[part 4 of 5: package /POWERTRAIN]
AUTOSAR XML (schema 3.2.2)
package /POWERTRAIN  (continued)
  can cluster POWERTRAIN:  (continued)
    physical channel POWERTRAIN  (continued)
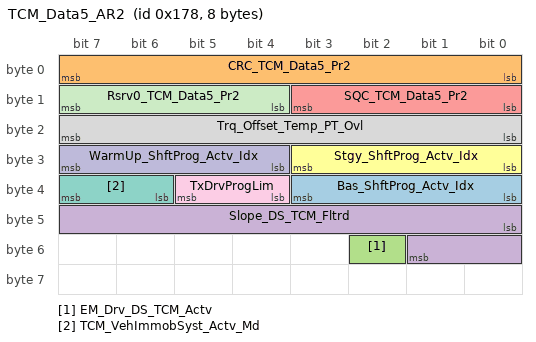
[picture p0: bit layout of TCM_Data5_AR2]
      frame TCM_Data5_AR2: id 0x178, from TCM, to CPC, frame-length=8, can-addressing-mode=STANDARD  # TCM Data5 AR2
        pdu TCM_Data5_AR2: length=64, unused-bit-pattern=0, cyclic-timing={repeating-time=0.1, starting-time=0.045}, event-controlled-timing=number-of-repeats=0, minimum-delay=0.01  # TCM Data5 AR2
          signal Bas_ShftProg_Actv_Idx: start 32, 4 bit, little-endian, data-type=c04_0_15_1_SNA_na, init-value=XDIS_2gdok7is6uk227cngmpgf9wxb/l0, transfer-property=TRIGGERED-ON-CHANGE, to CPC  # Index aktives Basisschaltprogramm / Index active base shift progrm
          signal CRC_TCM_Data5_Pr2: start 0, 8 bit, little-endian, data-type=c08_CRC_woSNA, init-value=l28, to CPC  # CRC-Checksumme der Signal Gruppe gemäß AUTOSAR Profil 2 / CRC-checksum of signal group according to AUTOSAR Profile 2
          signal EM_Drv_DS_TCM_Actv: start 50, 1 bit, little-endian, data-type=DC_BOOL, init-value=XDIS_h5tcyk98kzbgrc5svasomeyt/lfalse, transfer-property=TRIGGERED-ON-CHANGE, to CPC  # Aktivierung E-Fahrt Schaltprogramm der Fahrstrategie / activating E-Drive shift program of the driving strategie
          signal Slope_DS_TCM_Fltrd: start 40, 10 bit, little-endian, data-type=c10_perc_m30_70_0k1, init-value=XDIS_9q9tei3m1fjehhzmxi2ewe8ef/l1023, transfer-property=PENDING, to CPC  # Berechnete Steigung im TCM, gefiltert / Calculated TCM Slope, filtered
          signal SQC_TCM_Data5_Pr2: start 8, 4 bit, little-endian, data-type=c04_0_15_1_SNA_na, init-value=XDIS_2gdok7is6uk227cngmpgf9wxb/l0, to CPC  # Sequenzzähler / Sequence counter
          signal Stgy_ShftProg_Actv_Idx: start 24, 4 bit, little-endian, data-type=c04_0_15_1_SNA_na, init-value=XDIS_2gdok7is6uk227cngmpgf9wxb/l0, transfer-property=TRIGGERED-ON-CHANGE, to CPC  # Index aktives Strategie Schaltprogramm / Index active strategy shift progrm
          signal TCM_VehImmobSyst_Actv_Md: start 38, 2 bit, little-endian, data-type=c02_Rel_Lock_Free_SNA, init-value=XDIS_7xmnmysjdekva9q0y0lravx16/lREL, transfer-property=TRIGGERED-ON-CHANGE, to CPC  # FBS Freigabestatus TCM / TCM Vehicle immobilizing system active
          signal Trq_Offset_Temp_PT_Ovl: start 16, 8 bit, little-endian, data-type=c08_Nm_0_254_1, init-value=XDIS_atdfawq2fo29xmbv147hlg3xp/l255, to CPC  # Tq Offset für temporäre Überlastung PT / Torque Offset for temporary PT Overload
          signal TxDrvProgLim: start 36, 2 bit, little-endian, data-type=c02_TxDrvProgLim, init-value=lNO_RES_TCM, transfer-property=PENDING, to CPC  # Einschränkung Fahrprogramm TCM / TCM Limitation of Driving Program
          signal WarmUp_ShftProg_Actv_Idx: start 28, 4 bit, little-endian, data-type=c04_0_15_1_SNA_na, init-value=XDIS_2gdok7is6uk227cngmpgf9wxb/l0, transfer-property=TRIGGERED-ON-CHANGE, to CPC  # Index aktives Warmlaufschaltprogramm / Index active warmup shift progrm
          signal Rsrv0_TCM_Data5_Pr2: start 12, 4 bit, little-endian, data-type=Rsrv04, init-value=XDIS_eb9yua4lxmhrmvzyfsmxg3ler/l0, to CPC  # Reserviert für zukünftige Verwendung / Reserved for future use
          signal TCM_Data5_Pr2_c73komxr1qix41zrytxs0vhwu: little-endian, system-signal=[CRC_TCM_Data5_Pr2, Rsrv0_TCM_Data5_Pr2, SQC_TCM_Data5_Pr2, Trq_Offset_Temp_PT_Ovl], transfer-property=PENDING, to CPC  # TCM Data 5 (degraded) / TCM Date 5 (degraded)
      frame HVAC_Rs_AR2: id 0x1ED, from CPC, to ECM TCM, frame-length=8, can-addressing-mode=STANDARD  # Rückmeldung Klimaanlage / Heating, Ventilation and Air Conditioning response
        pdu HVAC_Rs_AR2: length=64, unused-bit-pattern=0, cyclic-timing=repeating-time=0.1  # Rückmeldung Klimaanlage / Heating, Ventilation and Air Conditioning response
          signal AddWtrPmp_Actv: start 36, 1 bit, little-endian, data-type=DC_BOOL, init-value=XDIS_h5tcyk98kzbgrc5svasomeyt/lfalse, transfer-property=PENDING, to ECM  # Zusatzwasserpumpe läuft / Additional water pump active
          signal AddWtrPmp_Err: start 37, 1 bit, little-endian, data-type=DC_BOOL, init-value=XDIS_h5tcyk98kzbgrc5svasomeyt/lfalse, transfer-property=PENDING, to ECM  # Fehler Zusatzwasserpumpe / Additional water pump error
          signal CRC_HVAC_CompTrq_Pr2: start 0, 8 bit, little-endian, data-type=c08_CRC_woSNA, init-value=l75, to ECM TCM  # CRC-Checksumme der Signal Gruppe gemäß AUTOSAR Profil 2 / CRC-checksum of signal group according to AUTOSAR Profile 2
          signal EngFanRPM_Rq_HVAC: start 56, 8 bit, little-endian, data-type=c08_perc_0_100_1, init-value=XDIS_526m332undv8qhobkm645cf10/l255, transfer-property=PENDING, to ECM  # Motorlüfter Solldrehzahl / Engine fan rpm request
          signal FrntGrllBlnd_Opn_Rq: start 29, 1 bit, little-endian, data-type=DC_BOOL, init-value=XDIS_h5tcyk98kzbgrc5svasomeyt/lfalse, transfer-property=PENDING, to ECM  # Jalousie Kühlergrill öffnen / Front grill blind open request
          signal HtPwr_Ft_Rq: start 48, 8 bit, little-endian, data-type=c08_perc_0_100_1, init-value=XDIS_526m332undv8qhobkm645cf10/l255, transfer-property=PENDING, to ECM  # Anforderung Heizleistung vorne / Heating power front request
          signal HVAC_Comp_Ft_On: start 28, 1 bit, little-endian, data-type=DC_BOOL, init-value=XDIS_h5tcyk98kzbgrc5svasomeyt/lfalse, transfer-property=PENDING, to ECM TCM  # Klima-Kompressor für vorne eingeschaltet / Aircon compressor front on
          signal HVAC_CompTrq_Ft: start 16, 8 bit, little-endian, data-type=c08_Nm_0_63k5_0k25, init-value=XDIS_3tke51neyh9tc3i280hit3n6t/l255, to ECM TCM  # Klima-Kompressormoment für vorne / Actual front aircon compressor crankshaft torque
          signal HVAC_CoolCirc_Actv: start 35, 1 bit, little-endian, data-type=DC_BOOL, init-value=XDIS_h5tcyk98kzbgrc5svasomeyt/lfalse, transfer-property=PENDING  # Kältekreislauf aktiv / HVAC cooling circuit active
          signal HVAC_CoolFan_Rq: start 31, 1 bit, little-endian, data-type=DC_BOOL, init-value=XDIS_h5tcyk98kzbgrc5svasomeyt/lfalse, transfer-property=PENDING  # Anforderung Klimaanlage: Kühlgebläse einschalten / Air condition cooling fan on request
          signal HVAC_CoolVlv_Rq: start 32, 2 bit, little-endian, data-type=c02_REM_CLS_OPN, init-value=XDIS_5kqf2dbype8wo99wu5c8aruyw/l3, transfer-property=PENDING  # Anforderung Kühlventil / Cool valve request
          signal HVAC_EngIdleRPM_Inc_Rq: start 27, 1 bit, little-endian, data-type=DC_BOOL, init-value=XDIS_h5tcyk98kzbgrc5svasomeyt/lfalse, transfer-property=PENDING, to ECM TCM  # Leerlauf-Drehzahlanhebung zur Kälteleistungserhöhung / Engine idle speed increase request
          signal HVAC_FrntGrllBlnd_Low_Rq: start 40, 4 bit, little-endian, data-type=c04_perc_0_100_10_SNA, init-value=XDIS_b7ef3mnghukxmc04ohxr08npp/l15, transfer-property=PENDING  # Anforderung untere Kühlergrill-Jalousie / Lower front grill blind request
          signal HVAC_FrntGrllBlnd_Up_Rq: start 44, 4 bit, little-endian, data-type=c04_perc_0_100_10_SNA, init-value=XDIS_b7ef3mnghukxmc04ohxr08npp/l15, transfer-property=PENDING  # Anforderung obere Kühlergrill-Jalousie / Upper front grill blind request
          signal HVAC_MaxCool_Rq: start 34, 1 bit, little-endian, data-type=DC_BOOL, init-value=XDIS_h5tcyk98kzbgrc5svasomeyt/lfalse, transfer-property=PENDING  # Maximale Kühlleistung für Klimakreislauf benötigt / Cooling circuit req. max. cooling performance
          signal HVAC_Ref_Circ_NA: start 30, 1 bit, little-endian, data-type=DC_BOOL, init-value=XDIS_h5tcyk98kzbgrc5svasomeyt/lfalse, transfer-property=PENDING  # HVAC Kühlkreislauf nicht verfügbar / HVAC cooling circuit not available
          signal HVAC_TxShftPoint_Inc_Rq: start 24, 1 bit, little-endian, data-type=DC_BOOL, init-value=XDIS_h5tcyk98kzbgrc5svasomeyt/lfalse, transfer-property=PENDING, to ECM TCM  # Anhebung des Getriebeschaltpunkts zur Klimakomfortsteigerung (kühlen) / Transmission shift point increase request for thermal comfort (cooling)
          signal HVAC_TxShftPointHt_Inc_Rq: start 25, 1 bit, little-endian, data-type=DC_BOOL, init-value=XDIS_h5tcyk98kzbgrc5svasomeyt/lfalse, transfer-property=PENDING, to ECM TCM  # Anhebung des Getriebeschaltpunkts zur Klimakomfortsteigerung (heizen) / Transmission shift point increase request for thermal comfort (heating)
          signal SQC_HVAC_CompTrq_Pr2: start 8, 4 bit, little-endian, data-type=c04_0_15_1_SNA_na, init-value=XDIS_2gdok7is6uk227cngmpgf9wxb/l0, to ECM TCM  # Sequenzzähler / Sequence counter
          signal SSA_Enbl_Rq_HVAC: start 26, 1 bit, little-endian, data-type=DC_BOOL, init-value=ltrue, transfer-property=PENDING, to ECM  # ASS enable / Enable stop/start automatic request
          signal Rsrv1_HVAC_Comp_Trq_Pr2: start 12, 4 bit, little-endian, data-type=Rsrv04, init-value=XDIS_eb9yua4lxmhrmvzyfsmxg3ler/l0, to ECM TCM  # Reserviert für zukünftige Verwendung / Reserved for future use
          signal HVAC_CompTrq_Pr2_c82iy4u15nkwuh8st1cqydegx: little-endian, system-signal=[CRC_HVAC_CompTrq_Pr2, HVAC_CompTrq_Ft, Rsrv1_HVAC_Comp_Trq_Pr2, SQC_HVAC_CompTrq_Pr2], transfer-property=PENDING, to ECM TCM  # KLimaanlage Kompressormoment (degraded) / HVAC compressor torque (degraded)
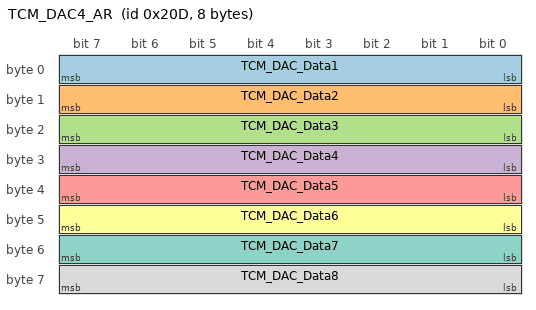
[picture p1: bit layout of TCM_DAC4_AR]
      frame TCM_DAC4_AR: id 0x20D, from TCM, to CPC, frame-length=8, can-addressing-mode=STANDARD  # FBS-Botschaft an EIS / Driving authorization checker
        pdu TCM_DAC4_AR: length=64, unused-bit-pattern=0, event-controlled-timing=number-of-repeats=0, minimum-delay=0.0050  # FBS-Botschaft an EIS / Driving authorization checker
          signal TCM_DAC_Data1: start 0, 8 bit, little-endian, data-type=c08_UInt_SNA_na, init-value=XDIS_2kt9ss9xytkqyzr4359iyexvi/l0, to CPC  # FBS-Botschaft an EIS Byte #1 / Driving authorization checker Byte #1
          signal TCM_DAC_Data2: start 8, 8 bit, little-endian, data-type=c08_UInt_SNA_na, init-value=XDIS_2kt9ss9xytkqyzr4359iyexvi/l0, to CPC  # FBS-Botschaft an EIS Byte #2 / Driving authorization checker Byte #2
          signal TCM_DAC_Data3: start 16, 8 bit, little-endian, data-type=c08_UInt_SNA_na, init-value=XDIS_2kt9ss9xytkqyzr4359iyexvi/l0, to CPC  # FBS-Botschaft an EIS Byte #3 / Driving authorization checker Byte #3
          signal TCM_DAC_Data4: start 24, 8 bit, little-endian, data-type=c08_UInt_SNA_na, init-value=XDIS_2kt9ss9xytkqyzr4359iyexvi/l0, to CPC  # FBS-Botschaft an EIS Byte #4 / Driving authorization checker Byte #4
          signal TCM_DAC_Data5: start 32, 8 bit, little-endian, data-type=c08_UInt_SNA_na, init-value=XDIS_2kt9ss9xytkqyzr4359iyexvi/l0, to CPC  # FBS-Botschaft an EIS Byte #5 / Driving authorization checker Byte #5
          signal TCM_DAC_Data6: start 40, 8 bit, little-endian, data-type=c08_UInt_SNA_na, init-value=XDIS_2kt9ss9xytkqyzr4359iyexvi/l0, to CPC  # FBS-Botschaft an EIS Byte #6 / Driving authorization checker Byte #6
          signal TCM_DAC_Data7: start 48, 8 bit, little-endian, data-type=c08_UInt_SNA_na, init-value=XDIS_2kt9ss9xytkqyzr4359iyexvi/l0, to CPC  # FBS-Botschaft an EIS Byte #7 / Driving authorization checker Byte #7
          signal TCM_DAC_Data8: start 56, 8 bit, little-endian, data-type=c08_UInt_SNA_na, init-value=XDIS_2kt9ss9xytkqyzr4359iyexvi/l0, to CPC  # FBS-Botschaft an EIS Byte #8 / Driving authorization checker Byte #8
          signal TCM_DAC_Data_4hn6jksl9jdh5r8zfj9p3zrj0: little-endian, system-signal=[TCM_DAC_Data1, TCM_DAC_Data2, TCM_DAC_Data3, TCM_DAC_Data4, TCM_DAC_Data5, TCM_DAC_Data6, TCM_DAC_Data7, TCM_DAC_Data8], transfer-property=TRIGGERED, to CPC  # FBS-Botschaft an EIS (degraded) / Driving authorization checker (degraded)
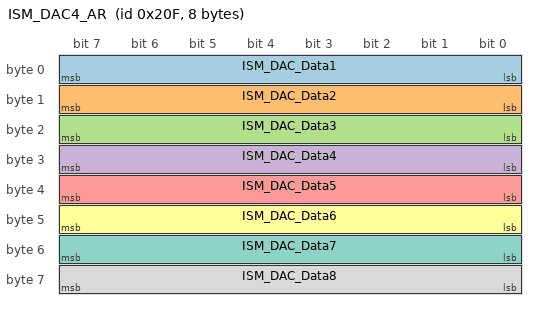
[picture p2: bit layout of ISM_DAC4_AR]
      frame ISM_DAC4_AR: id 0x20F, from ISM, to CPC, frame-length=8, can-addressing-mode=STANDARD  # FBS-Botschaft an EIS / Driving authorization checker
        pdu ISM_DAC4_AR: length=64, unused-bit-pattern=0, event-controlled-timing=number-of-repeats=0, minimum-delay=0.0050  # FBS-Botschaft an EIS / Driving authorization checker
          signal ISM_DAC_Data1: start 0, 8 bit, little-endian, data-type=c08_UInt_SNA_na, init-value=XDIS_2kt9ss9xytkqyzr4359iyexvi/l0, to CPC  # FBS-Botschaft an EIS Byte #1 / Driving authorization checker Byte #1
          signal ISM_DAC_Data2: start 8, 8 bit, little-endian, data-type=c08_UInt_SNA_na, init-value=XDIS_2kt9ss9xytkqyzr4359iyexvi/l0, to CPC  # FBS-Botschaft an EIS Byte #2 / Driving authorization checker Byte #2
          signal ISM_DAC_Data3: start 16, 8 bit, little-endian, data-type=c08_UInt_SNA_na, init-value=XDIS_2kt9ss9xytkqyzr4359iyexvi/l0, to CPC  # FBS-Botschaft an EIS Byte #3 / Driving authorization checker Byte #3
          signal ISM_DAC_Data4: start 24, 8 bit, little-endian, data-type=c08_UInt_SNA_na, init-value=XDIS_2kt9ss9xytkqyzr4359iyexvi/l0, to CPC  # FBS-Botschaft an EIS Byte #4 / Driving authorization checker Byte #4
          signal ISM_DAC_Data5: start 32, 8 bit, little-endian, data-type=c08_UInt_SNA_na, init-value=XDIS_2kt9ss9xytkqyzr4359iyexvi/l0, to CPC  # FBS-Botschaft an EIS Byte #5 / Driving authorization checker Byte #5
          signal ISM_DAC_Data6: start 40, 8 bit, little-endian, data-type=c08_UInt_SNA_na, init-value=XDIS_2kt9ss9xytkqyzr4359iyexvi/l0, to CPC  # FBS-Botschaft an EIS Byte #6 / Driving authorization checker Byte #6
          signal ISM_DAC_Data7: start 48, 8 bit, little-endian, data-type=c08_UInt_SNA_na, init-value=XDIS_2kt9ss9xytkqyzr4359iyexvi/l0, to CPC  # FBS-Botschaft an EIS Byte #7 / Driving authorization checker Byte #7
          signal ISM_DAC_Data8: start 56, 8 bit, little-endian, data-type=c08_UInt_SNA_na, init-value=XDIS_2kt9ss9xytkqyzr4359iyexvi/l0, to CPC  # FBS-Botschaft an EIS Byte #8 / Driving authorization checker Byte #8
          signal ISM_DAC_Data_7p6mfdvzdjn83yje572o4gwnl: little-endian, system-signal=[ISM_DAC_Data1, ISM_DAC_Data2, ISM_DAC_Data3, ISM_DAC_Data4, ISM_DAC_Data5, ISM_DAC_Data6, ISM_DAC_Data7, ISM_DAC_Data8], transfer-property=TRIGGERED, to CPC  # FBS-Botschaft an EIS (degraded) / Driving authorization checker (degraded)
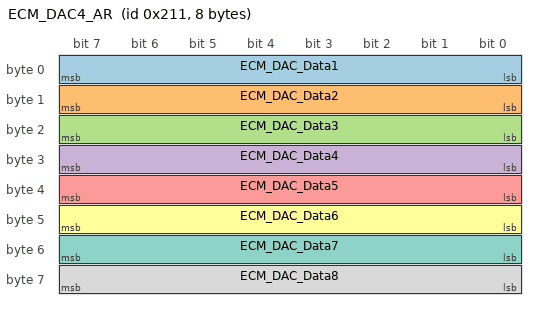
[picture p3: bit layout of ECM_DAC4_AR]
      frame ECM_DAC4_AR: id 0x211, from ECM, to CPC, frame-length=8, can-addressing-mode=STANDARD  # FBS-Botschaft an EIS / Driving authorization checker
        pdu ECM_DAC4_AR: length=64, unused-bit-pattern=0, event-controlled-timing=number-of-repeats=0, minimum-delay=0.0050  # FBS-Botschaft an EIS / Driving authorization checker
          signal ECM_DAC_Data1: start 0, 8 bit, little-endian, data-type=c08_UInt_SNA_na, init-value=XDIS_2kt9ss9xytkqyzr4359iyexvi/l0, to CPC  # FBS-Botschaft an EIS Byte #1 / Driving authorization checker Byte #1
          signal ECM_DAC_Data2: start 8, 8 bit, little-endian, data-type=c08_UInt_SNA_na, init-value=XDIS_2kt9ss9xytkqyzr4359iyexvi/l0, to CPC  # FBS-Botschaft an EIS Byte #2 / Driving authorization checker Byte #2
          signal ECM_DAC_Data3: start 16, 8 bit, little-endian, data-type=c08_UInt_SNA_na, init-value=XDIS_2kt9ss9xytkqyzr4359iyexvi/l0, to CPC  # FBS-Botschaft an EIS Byte #3 / Driving authorization checker Byte #3
          signal ECM_DAC_Data4: start 24, 8 bit, little-endian, data-type=c08_UInt_SNA_na, init-value=XDIS_2kt9ss9xytkqyzr4359iyexvi/l0, to CPC  # FBS-Botschaft an EIS Byte #4 / Driving authorization checker Byte #4
          signal ECM_DAC_Data5: start 32, 8 bit, little-endian, data-type=c08_UInt_SNA_na, init-value=XDIS_2kt9ss9xytkqyzr4359iyexvi/l0, to CPC  # FBS-Botschaft an EIS Byte #5 / Driving authorization checker Byte #5
          signal ECM_DAC_Data6: start 40, 8 bit, little-endian, data-type=c08_UInt_SNA_na, init-value=XDIS_2kt9ss9xytkqyzr4359iyexvi/l0, to CPC  # FBS-Botschaft an EIS Byte #6 / Driving authorization checker Byte #6
          signal ECM_DAC_Data7: start 48, 8 bit, little-endian, data-type=c08_UInt_SNA_na, init-value=XDIS_2kt9ss9xytkqyzr4359iyexvi/l0, to CPC  # FBS-Botschaft an EIS Byte #7 / Driving authorization checker Byte #7
          signal ECM_DAC_Data8: start 56, 8 bit, little-endian, data-type=c08_UInt_SNA_na, init-value=XDIS_2kt9ss9xytkqyzr4359iyexvi/l0, to CPC  # FBS-Botschaft an EIS Byte #8 / Driving authorization checker Byte #8
          signal ECM_DAC_Data_evokyfu54wz1o08tpk616zohb: little-endian, system-signal=[ECM_DAC_Data1, ECM_DAC_Data2, ECM_DAC_Data3, ECM_DAC_Data4, ECM_DAC_Data5, ECM_DAC_Data6, ECM_DAC_Data7, ECM_DAC_Data8], transfer-property=TRIGGERED, to CPC  # FBS-Botschaft an EIS (degraded) / Driving authorization checker (degraded)
      frame DAC4_ECM_AR: id 0x213, from CPC, to ECM, frame-length=8, can-addressing-mode=STANDARD  # FBS-Botschaft an ECM / Driving authorization checker
        pdu DAC4_ECM_AR: length=64, unused-bit-pattern=0, event-controlled-timing=number-of-repeats=0, minimum-delay=0.0050  # FBS-Botschaft an ECM / Driving authorization checker
          signal DAC_ECM_Data1: start 0, 8 bit, little-endian, data-type=c08_UInt_SNA_na, init-value=XDIS_2kt9ss9xytkqyzr4359iyexvi/l0, to ECM  # FBS-Botschaft an ECM Byte #1 / Driving authorization checker Byte #1
          signal DAC_ECM_Data2: start 8, 8 bit, little-endian, data-type=c08_UInt_SNA_na, init-value=XDIS_2kt9ss9xytkqyzr4359iyexvi/l0, to ECM  # FBS-Botschaft an ECM Byte #2 / Driving authorization checker Byte #2
          signal DAC_ECM_Data3: start 16, 8 bit, little-endian, data-type=c08_UInt_SNA_na, init-value=XDIS_2kt9ss9xytkqyzr4359iyexvi/l0, to ECM  # FBS-Botschaft an ECM Byte #3 / Driving authorization checker Byte #3
          signal DAC_ECM_Data4: start 24, 8 bit, little-endian, data-type=c08_UInt_SNA_na, init-value=XDIS_2kt9ss9xytkqyzr4359iyexvi/l0, to ECM  # FBS-Botschaft an ECM Byte #4 / Driving authorization checker Byte #4
          signal DAC_ECM_Data5: start 32, 8 bit, little-endian, data-type=c08_UInt_SNA_na, init-value=XDIS_2kt9ss9xytkqyzr4359iyexvi/l0, to ECM  # FBS-Botschaft an ECM Byte #5 / Driving authorization checker Byte #5
          signal DAC_ECM_Data6: start 40, 8 bit, little-endian, data-type=c08_UInt_SNA_na, init-value=XDIS_2kt9ss9xytkqyzr4359iyexvi/l0, to ECM  # FBS-Botschaft an ECM Byte #6 / Driving authorization checker Byte #6
          signal DAC_ECM_Data7: start 48, 8 bit, little-endian, data-type=c08_UInt_SNA_na, init-value=XDIS_2kt9ss9xytkqyzr4359iyexvi/l0, to ECM  # FBS-Botschaft an ECM Byte #7 / Driving authorization checker Byte #7
          signal DAC_ECM_Data8: start 56, 8 bit, little-endian, data-type=c08_UInt_SNA_na, init-value=XDIS_2kt9ss9xytkqyzr4359iyexvi/l0, to ECM  # FBS-Botschaft an ECM Byte #8 / Driving authorization checker Byte #8
          signal DAC_ECM_Data_2al2wd1ekctisq83jz37brera: little-endian, system-signal=[DAC_ECM_Data1, DAC_ECM_Data2, DAC_ECM_Data3, DAC_ECM_Data4, DAC_ECM_Data5, DAC_ECM_Data6, DAC_ECM_Data7, DAC_ECM_Data8], transfer-property=TRIGGERED, to ECM  # FBS-Botschaft an ECM (degraded) / Driving authorization checker (degraded)
      frame DAC4_TCM_AR: id 0x215, from CPC, to TCM, frame-length=8, can-addressing-mode=STANDARD  # FBS-Botschaft an TCM / Driving authorization checker
        pdu DAC4_TCM_AR: length=64, unused-bit-pattern=0, event-controlled-timing=number-of-repeats=0, minimum-delay=0.0050  # FBS-Botschaft an TCM / Driving authorization checker
          signal DAC_TCM_Data1: start 0, 8 bit, little-endian, data-type=c08_UInt_SNA_na, init-value=XDIS_2kt9ss9xytkqyzr4359iyexvi/l0, to TCM  # FBS-Botschaft an TCM Byte#1 / Driving authorization checker Byte#1
          signal DAC_TCM_Data2: start 8, 8 bit, little-endian, data-type=c08_UInt_SNA_na, init-value=XDIS_2kt9ss9xytkqyzr4359iyexvi/l0, to TCM  # FBS-Botschaft an TCM Byte#2 / Driving authorization checker Byte#2
          signal DAC_TCM_Data3: start 16, 8 bit, little-endian, data-type=c08_UInt_SNA_na, init-value=XDIS_2kt9ss9xytkqyzr4359iyexvi/l0, to TCM  # FBS-Botschaft an TCM Byte#3 / Driving authorization checker Byte#3
          signal DAC_TCM_Data4: start 24, 8 bit, little-endian, data-type=c08_UInt_SNA_na, init-value=XDIS_2kt9ss9xytkqyzr4359iyexvi/l0, to TCM  # FBS-Botschaft an TCM Byte#4 / Driving authorization checker Byte#4
          signal DAC_TCM_Data5: start 32, 8 bit, little-endian, data-type=c08_UInt_SNA_na, init-value=XDIS_2kt9ss9xytkqyzr4359iyexvi/l0, to TCM  # FBS-Botschaft an TCM Byte#5 / Driving authorization checker Byte#5
          signal DAC_TCM_Data6: start 40, 8 bit, little-endian, data-type=c08_UInt_SNA_na, init-value=XDIS_2kt9ss9xytkqyzr4359iyexvi/l0, to TCM  # FBS-Botschaft an TCM Byte#6 / Driving authorization checker Byte#6
          signal DAC_TCM_Data7: start 48, 8 bit, little-endian, data-type=c08_UInt_SNA_na, init-value=XDIS_2kt9ss9xytkqyzr4359iyexvi/l0, to TCM  # FBS-Botschaft an TCM Byte#7 / Driving authorization checker Byte#7
          signal DAC_TCM_Data8: start 56, 8 bit, little-endian, data-type=c08_UInt_SNA_na, init-value=XDIS_2kt9ss9xytkqyzr4359iyexvi/l0, to TCM  # FBS-Botschaft an TCM Byte#8 / Driving authorization checker Byte#8
          signal DAC_TCM_Data_2bwrxx3jxcrr8ui2py52ml14h: little-endian, system-signal=[DAC_TCM_Data1, DAC_TCM_Data2, DAC_TCM_Data3, DAC_TCM_Data4, DAC_TCM_Data5, DAC_TCM_Data6, DAC_TCM_Data7, DAC_TCM_Data8], transfer-property=TRIGGERED, to TCM  # FBS-Botschaft an TCM (degraded) / Driving authorization checker (degraded)
      frame DAC4_ISM_AR: id 0x217, from CPC, to ISM, frame-length=8, can-addressing-mode=STANDARD  # FBS-Botschaft an ISM / Driving authorization checker
        pdu DAC4_ISM_AR: length=64, unused-bit-pattern=0, event-controlled-timing=number-of-repeats=0, minimum-delay=0.0050  # FBS-Botschaft an ISM / Driving authorization checker
          signal DAC_ISM_Data1: start 0, 8 bit, little-endian, data-type=c08_UInt_SNA_na, init-value=XDIS_2kt9ss9xytkqyzr4359iyexvi/l0, to ISM  # FBS-Botschaft an ISM Byte#1 / Driving authorization checker Byte#1
          signal DAC_ISM_Data2: start 8, 8 bit, little-endian, data-type=c08_UInt_SNA_na, init-value=XDIS_2kt9ss9xytkqyzr4359iyexvi/l0, to ISM  # FBS-Botschaft an ISM Byte#2 / Driving authorization checker Byte#2
          signal DAC_ISM_Data3: start 16, 8 bit, little-endian, data-type=c08_UInt_SNA_na, init-value=XDIS_2kt9ss9xytkqyzr4359iyexvi/l0, to ISM  # FBS-Botschaft an ISM Byte#3 / Driving authorization checker Byte#3
          signal DAC_ISM_Data4: start 24, 8 bit, little-endian, data-type=c08_UInt_SNA_na, init-value=XDIS_2kt9ss9xytkqyzr4359iyexvi/l0, to ISM  # FBS-Botschaft an ISM Byte#4 / Driving authorization checker Byte#4
          signal DAC_ISM_Data5: start 32, 8 bit, little-endian, data-type=c08_UInt_SNA_na, init-value=XDIS_2kt9ss9xytkqyzr4359iyexvi/l0, to ISM  # FBS-Botschaft an ISM Byte#5 / Driving authorization checker Byte#5
          signal DAC_ISM_Data6: start 40, 8 bit, little-endian, data-type=c08_UInt_SNA_na, init-value=XDIS_2kt9ss9xytkqyzr4359iyexvi/l0, to ISM  # FBS-Botschaft an ISM Byte#6 / Driving authorization checker Byte#6
          signal DAC_ISM_Data7: start 48, 8 bit, little-endian, data-type=c08_UInt_SNA_na, init-value=XDIS_2kt9ss9xytkqyzr4359iyexvi/l0, to ISM  # FBS-Botschaft an ISM Byte#7 / Driving authorization checker Byte#7
          signal DAC_ISM_Data8: start 56, 8 bit, little-endian, data-type=c08_UInt_SNA_na, init-value=XDIS_2kt9ss9xytkqyzr4359iyexvi/l0, to ISM  # FBS-Botschaft an ISM Byte#8 / Driving authorization checker Byte#8
          signal DAC_ISM_Data_a00gd8sscucoi8oddzqtfrwxy: little-endian, system-signal=[DAC_ISM_Data1, DAC_ISM_Data2, DAC_ISM_Data3, DAC_ISM_Data4, DAC_ISM_Data5, DAC_ISM_Data6, DAC_ISM_Data7, DAC_ISM_Data8], transfer-property=TRIGGERED, to ISM  # FBS-Botschaft an ISM (degraded) / Driving authorization checker (degraded)
      frame Fuel_Stat_AR2: id 0x21D, from FSCM, to ECM, frame-length=8, can-addressing-mode=STANDARD
        pdu Fuel_Stat_AR2: length=64, unused-bit-pattern=0, cyclic-timing={repeating-time=0.1, starting-time=0.045}  # Kraftstoff Status / Fuel Status
          signal ElectricFuelPmp_Curr: start 32, 8 bit, little-endian, data-type=c08_A_0_30d1_0d15, init-value=XDIS_i4e3ph6igxm4spvtvcd0aaxn/l0, transfer-property=PENDING, to ECM  # Stromstärke elektrische Kraftstoffpumpe / Electric Fuel Pump current
          signal ElectricFuelPmp_RPM: start 24, 8 bit, little-endian, data-type=c08_rpm_0_5080_20, init-value=XDIS_em3qjydapl05yf4dt066kijsc/l0, transfer-property=PENDING, to ECM  # U/min der elektrischen Kraftstoffpumpe / RPM of the electric fuel Pump
          signal ElectricFuelPmp_Stat: start 40, 4 bit, little-endian, data-type=c04_ElectricFuelPmp_Stat, init-value=XDIS_cn7ds5rce5o16qs43tbneudnt/lOFF, transfer-property=PENDING, to ECM  # Status elektrische Kraftstoffpumpe / State of electric fuel pump
          signal EthanolConcent: start 16, 8 bit, little-endian, data-type=c08_perc_0_100_0k5, init-value=XDIS_7gd3auxmk1537dxoewcnzblfs/l255, transfer-property=PENDING, to ECM  # Kraftstoffethanolgehalt / Fuel Ethanol concentration
          signal FuelPmpDtyCyc: start 0, 8 bit, little-endian, data-type=c08_perc_0_100_0k5, init-value=XDIS_7gd3auxmk1537dxoewcnzblfs/l255, transfer-property=PENDING, to ECM  # Aktuelles Tastverhältnis Kraftstoffpumpe / Actual fuel pump duty cycle
          signal FuelPress: start 8, 8 bit, little-endian, data-type=c08_bar_0_10_0k05, init-value=XDIS_7frps0id7o3a7jqx301qmd2zx/l255, transfer-property=PENDING, to ECM  # Aktueller Kraftstoffdruck / Actual fuel pressure
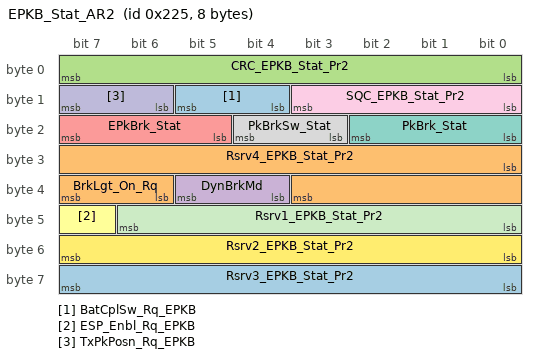
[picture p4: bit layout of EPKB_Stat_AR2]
      frame EPKB_Stat_AR2: id 0x225, from CPC, to ECM ISM TCM, frame-length=8, can-addressing-mode=STANDARD
        pdu EPKB_Stat_AR2: length=64, unused-bit-pattern=0, cyclic-timing=repeating-time=0.1, event-controlled-timing=number-of-repeats=0, minimum-delay=0.0050  # Status elektrische Parkbremse / Electrical parking brake state
          signal BatCplSw_Rq_EPKB: start 12, 2 bit, little-endian, data-type=c02_BatCplSw_Rq, init-value=XDIS_dl69ynb9ox7e9q5squkescmw4/lIDLE, transfer-property=TRIGGERED-ON-CHANGE, to ECM ISM TCM  # Anforderung Batteriekoppelschalter / Battery coupling switch request
          signal BrkLgt_On_Rq: start 38, 2 bit, little-endian, data-type=c02_Off_On, init-value=XDIS_222cmje3au9eeyrzykrya1i1q/lOFF, transfer-property=TRIGGERED-ON-CHANGE, to ECM ISM TCM  # Bremslicht einschalten / Brake light on request
          signal CRC_EPKB_Stat_Pr2: start 0, 8 bit, little-endian, data-type=c08_CRC_woSNA, init-value=l120, transfer-property=PENDING, to ECM ISM TCM  # CRC-Checksumme der Signal Gruppe gemäß AUTOSAR Profil 2 / CRC-checksum of signal group according to AUTOSAR Profile 2
          signal DynBrkMd: start 36, 2 bit, little-endian, data-type=c02_DynBrkMd, init-value=XDIS_34pxfrh12b3pknp94x9up6ty8/l3, transfer-property=TRIGGERED-ON-CHANGE, to ECM ISM TCM  # Modus dynamisches Bremsen / Dynamic braking mode
          signal EPkBrk_Stat: start 21, 3 bit, little-endian, data-type=c03_EPkBrk_Stat, init-value=XDIS_a5y42lspsaonemgf5sbikbeo/l7, transfer-property=TRIGGERED-ON-CHANGE, to ECM ISM TCM  # Status EPKB / Electrical parking brake system state
          signal ESP_Enbl_Rq_EPKB: start 47, 1 bit, little-endian, data-type=DC_BOOL, init-value=XDIS_h5tcyk98kzbgrc5svasomeyt/lfalse, transfer-property=TRIGGERED-ON-CHANGE, to ECM ISM TCM  # ESP-Anforderung erlaubt / Enable ESP request
          signal PkBrk_Stat: start 16, 3 bit, little-endian, data-type=c03_PkBrk_Stat, init-value=XDIS_792fn6nanbwsc1tnzw8o9lx5c/l7, transfer-property=TRIGGERED-ON-CHANGE, to ECM ISM TCM  # Status Feststellbremse / Parking brake state
          signal PkBrkSw_Stat: start 19, 2 bit, little-endian, data-type=c02_PkBrk_Sw_Stat, init-value=XDIS_256fs0r9jnfeiadezxr0n6q99/l3, transfer-property=TRIGGERED-ON-CHANGE, to ECM ISM TCM  # Feststellbremsenschalterzustand / Parking brake switch state
          signal SQC_EPKB_Stat_Pr2: start 8, 4 bit, little-endian, data-type=c04_0_15_1_SNA_na, init-value=XDIS_2gdok7is6uk227cngmpgf9wxb/l0, transfer-property=PENDING, to ECM ISM TCM  # Sequenzzähler / Sequence counter
          signal TxPkPosn_Rq_EPKB: start 14, 2 bit, little-endian, data-type=c02_TxPkPos_Rq, init-value=XDIS_2db0f8ngs6vghwr5wq6rrafpy/lIDLE, transfer-property=TRIGGERED-ON-CHANGE, to ECM ISM TCM  # EPKB-Wunsch: "P" einlegen / Transmission parking position request
          signal Rsrv1_EPKB_Stat_Pr2: start 40, 7 bit, little-endian, data-type=Rsrv07, init-value=XDIS_1uvqkcvexva3vp6bv7zoxjawg/l0, transfer-property=PENDING, to ECM ISM TCM  # Reserviert für zukünftige Verwendung / Reserved for future use
          signal Rsrv2_EPKB_Stat_Pr2: start 48, 8 bit, little-endian, data-type=Rsrv08, init-value=XDIS_4flxbk4wkjkdew7cw07d9of66/l0, transfer-property=PENDING, to ECM ISM TCM  # Reserviert für zukünftige Verwendung / Reserved for future use
          signal Rsrv3_EPKB_Stat_Pr2: start 56, 8 bit, little-endian, data-type=Rsrv08, init-value=XDIS_4flxbk4wkjkdew7cw07d9of66/l0, transfer-property=PENDING, to ECM ISM TCM  # Reserviert für zukünftige Verwendung / Reserved for future use
          signal Rsrv4_EPKB_Stat_Pr2: start 24, 12 bit, little-endian, data-type=Rsrv12, init-value=XDIS_94njywbs6xys4vfs8fqiw3tks/l0, transfer-property=PENDING, to ECM ISM TCM  # Reserviert für zukünftige Verwendung / Reserved for future use
          signal EPKB_Stat_Pr2_9vocfbztwmx64yya8hopavqwq: little-endian, system-signal=[BatCplSw_Rq_EPKB, BrkLgt_On_Rq, CRC_EPKB_Stat_Pr2, DynBrkMd, EPkBrk_Stat, ESP_Enbl_Rq_EPKB, PkBrk_Stat, PkBrkSw_Stat, Rsrv1_EPKB_Stat_Pr2, Rsrv2_EPKB_Stat_Pr2, Rsrv3_EPKB_Stat_Pr2, Rsrv4_EPKB_Stat_Pr2, SQC_EPKB_Stat_Pr2, TxPkPosn_Rq_EPKB], to ECM ISM TCM  # Status elektrische Parkbremse (degraded) / Electrical parking brake state (degraded)
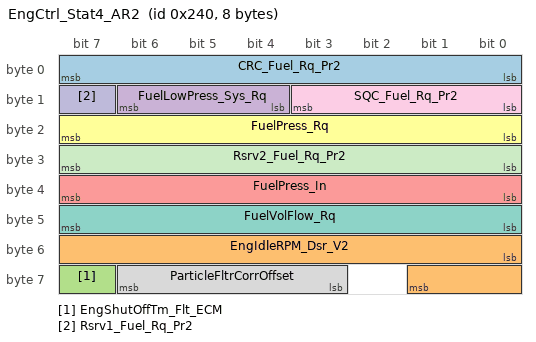
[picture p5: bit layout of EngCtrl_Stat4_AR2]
      frame EngCtrl_Stat4_AR2: id 0x240, from ECM, to CPC FSCM TCM, frame-length=8, can-addressing-mode=STANDARD
        pdu EngCtrl_Stat4_AR2: length=64, unused-bit-pattern=0, cyclic-timing={repeating-time=0.1, starting-time=0.0050}, event-controlled-timing=number-of-repeats=0, minimum-delay=0.01
          signal CRC_Fuel_Rq_Pr2: start 0, 8 bit, little-endian, data-type=c08_CRC_woSNA, init-value=l171, transfer-property=PENDING, to FSCM  # CRC-Checksumme der Signal Gruppe gemäß AUTOSAR Profil 2 / CRC-checksum of signal group according to AUTOSAR Profile 2
          signal EngIdleRPM_Dsr_V2: start 48, 10 bit, little-endian, data-type=c10_rpm_0_5000_5, init-value=XDIS_4l8q09vxqhutv9go97s4i82pi/l0, transfer-property=PENDING, to CPC TCM  # TCM Motorleerlaufsolldrehzahl / Desired engine idle speed to TCM
          signal EngShutOffTm_Flt_ECM: start 63, 1 bit, little-endian, data-type=DC_BOOL, init-value=XDIS_h5tcyk98kzbgrc5svasomeyt/lfalse, transfer-property=PENDING, to CPC FSCM  # Motorabstellzeit fehler von ECm festgestellt / Engine shut-off time fault from ECM
          signal FuelLowPress_Sys_Rq: start 12, 3 bit, little-endian, data-type=c03_FuelLowPress_Sys_Rq, init-value=XDIS_75kgv6x5wmeuyxn4jb0wfq7lq/l7, transfer-property=TRIGGERED-ON-CHANGE, to FSCM  # Anforderung an Kraftstoffniederdruckbereitstellung / Fuel Low pressure request
          signal FuelPress_In: start 32, 8 bit, little-endian, data-type=c08_hPa_0_12700_50, init-value=XDIS_bcvzfb8xc82lopd6nomhoa8hz/l0, transfer-property=PENDING, to FSCM  # Kraftstoffdruck für Mengensteuerung vor Hochdruckpumpe / Fuel pressure for quantity control before high pressure pump
          signal FuelPress_Rq: start 16, 8 bit, little-endian, data-type=c08_bar_0_10_0k05, init-value=XDIS_7frps0id7o3a7jqx301qmd2zx/l255, transfer-property=PENDING, to FSCM  # Anforderung Kraftstoffdruck / Fuel pressure request
          signal FuelVolFlow_Rq: start 40, 8 bit, little-endian, data-type=c08_l_per_h_0_381_1d5, init-value=XDIS_7aptig5ed7lppf85ff76xckus/l0, transfer-property=PENDING, to FSCM  # Kraftstoffflussanforderung / Fuel volume flow request
          signal ParticleFltrCorrOffset: start 59, 4 bit, little-endian, data-type=c04_0_0k42_0k03, init-value=XDIS_62zcs6tgdsblatw2e20ozynnd/l0, transfer-property=PENDING, to TCM  # Partikelfilterkorrekturwert / Particle filter correction offset on EngTrqMaxCorrFctr
          signal SQC_Fuel_Rq_Pr2: start 8, 4 bit, little-endian, data-type=c04_0_15_1_SNA_na, init-value=XDIS_2gdok7is6uk227cngmpgf9wxb/l0, transfer-property=PENDING, to FSCM  # Sequenzzähler / Sequence counter
          signal Rsrv1_Fuel_Rq_Pr2: start 15, 1 bit, little-endian, data-type=Rsrv01, init-value=XDIS_e2uhxyvdu33zsyqfjnk549pp2/l0, transfer-property=PENDING, to CPC FSCM TCM  # Reserviert für zukünftige Verwendung / Reserved for future use
          signal Rsrv2_Fuel_Rq_Pr2: start 24, 8 bit, little-endian, data-type=Rsrv08, init-value=XDIS_4flxbk4wkjkdew7cw07d9of66/l0, transfer-property=PENDING, to CPC FSCM TCM  # Reserviert für zukünftige Verwendung / Reserved for future use
          signal Fuel_Rq_Pr2_eypyqep6qt2njcbx8m8j4hfby: little-endian, system-signal=[CRC_Fuel_Rq_Pr2, FuelLowPress_Sys_Rq, FuelPress_Rq, Rsrv1_Fuel_Rq_Pr2, Rsrv2_Fuel_Rq_Pr2, SQC_Fuel_Rq_Pr2], to FSCM  # Fuel Request (degraded)
      frame FSCM_DTC_OBD_AR2: id 0x27F, from FSCM, to ECM, frame-length=8, can-addressing-mode=STANDARD  # FSCM Diagnostic trouble code für OBD / FSCM Diagnostic trouble code for OBD
        pdu FSCM_DTC_OBD_AR2: length=64, unused-bit-pattern=0, cyclic-timing={repeating-time=0.1, starting-time=0.0}  # FSCM Diagnostic trouble code für OBD / FSCM Diagnostic trouble code for OBD
          signal FSCM_CALID_CVN_ErrNum: start 0, 6 bit, little-endian, data-type=c06_0_63_1_SNA_na, init-value=XDIS_efjwndmyv9jwvt4o20fd0h4jr/l0, transfer-property=PENDING, to ECM  # Fehlernummer oder Zähler für CALID/CVN-Übertragung / Error number or counter for CALID/CVN transmission
          signal FSCM_CALID_Data: start 8, 8 bit, little-endian, data-type=c08_0_255_1_SNA_na, init-value=XDIS_ewtdrsxwev3sdrb0l7wuuy5x2/l255, transfer-property=PENDING, to ECM  # CALID/CVN Datenbyte / CALID/CVN data byte
          signal FSCM_CVN_Tx_Actv: start 7, 1 bit, little-endian, data-type=DC_BOOL, init-value=XDIS_h5tcyk98kzbgrc5svasomeyt/lfalse, transfer-property=PENDING, to ECM  # CVN wird übertragen / CVN transmission is active
          signal FSCM_DTC1_Idx: start 16, 5 bit, little-endian, data-type=c05_0_31_1_SNA_na, init-value=XDIS_eyvjtlfat7mxs0ushx899rtu2/l0, transfer-property=PENDING, to ECM  # Diagnostic trouble code #1 index
          signal FSCM_DTC1_Stat: start 21, 3 bit, little-endian, data-type=c03_RBS_DTC_Stat, init-value=lNOT_SUPPORTED, transfer-property=PENDING, to ECM  # Diagnostic trouble code #1 state
      frame TCM_Disp_Rq_AMG_AR: id 0x28D, from TCM, to CPC DRVU, frame-length=8, can-addressing-mode=STANDARD  # TCM Display Anforderung (nur AMG) / TCM display request (only AMG)
        pdu TCM_Disp_Rq_AMG_AR: length=64, unused-bit-pattern=0, cyclic-timing={repeating-time=0.2, starting-time=0.12}, event-controlled-timing=number-of-repeats=0, minimum-delay=0.04  # TCM Display Anforderung (nur AMG) / TCM display request (only AMG)
          signal TCM_TxLED_Disp_Rq: start 0, 5 bit, little-endian, data-type=c05_TCM_TxLED, init-value=XDIS_6h6s0bv7efp11m4nlf9yg5z0a/lLED_OFF, to CPC DRVU(timeout 2.1 s)  # Getriebe LED-Anzeige Anforderung / Transmission LED display request
          signal TCM_TxShift_Disp_Rq: start 8, 4 bit, little-endian, data-type=c04_TCM_TxShift, init-value=XDIS_bmt0u1x06oaiquus1ilde29fw/lNO_RQ, to CPC DRVU(timeout 2.1 s)  # Transmission shift denial/proposal display request
          signal Tx_OptmzFullLoad_Rq: start 62, 2 bit, little-endian, data-type=c02_InActv_Actv, init-value=XDIS_erebtjnp6vmvpjp0dso95abr3/lINACTV, transfer-property=TRIGGERED-ON-CHANGE, to CPC  # Optimierte Volllast Anforderung von Getriebe / Optimzied full load request of transmission
          signal TxBurnOut_Stat: start 5, 2 bit, little-endian, data-type=c02_TxBurnOut_Stat, init-value=lINACTIVE, to CPC DRVU(timeout 2.1 s)  # Getriebe Burnout status (nur AMG) / Transmission burnout state (only AMG)
          signal TCM_Disp_Rq_AMG_a2nvzdcsqucauph6dn6priuij: little-endian, system-signal=[TCM_TxLED_Disp_Rq, TCM_TxShift_Disp_Rq, TxBurnOut_Stat], transfer-property=TRIGGERED-ON-CHANGE, to CPC DRVU(timeout 2.1 s)  # TCM Display Anforderung (nur AMG) (degraded) / TCM display request (only AMG) (degraded)
      frame TCM_Rq1_AR: id 0x2A5, from TCM, to SSP, frame-length=8, can-addressing-mode=STANDARD
        pdu TCM_Rq1_AR: length=64, unused-bit-pattern=0, cyclic-timing={repeating-time=0.02, starting-time=0.1}
          signal AuxOilPmp_Mess_Enbl: start 8, 1 bit, little-endian, data-type=DC_BOOL, init-value=XDIS_h5tcyk98kzbgrc5svasomeyt/lfalse, transfer-property=PENDING, to SSP  # Enable measurement ID of auxiliary oil pump
          signal CurrDtyCyc_Rq: start 0, 8 bit, little-endian, data-type=c08_perc_0_100_0k5, init-value=XDIS_7gd3auxmk1537dxoewcnzblfs/l255, transfer-property=PENDING, to SSP  # Soll-Strom (Tastverhältnis) / Requested current duty cycle
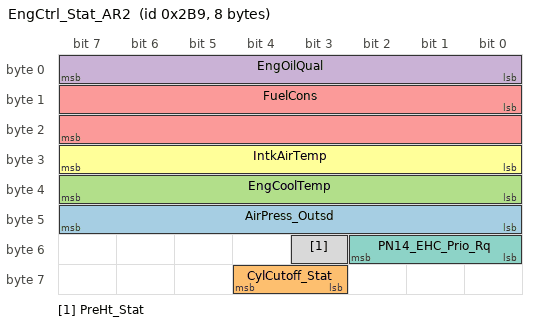
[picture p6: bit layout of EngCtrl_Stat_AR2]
      frame EngCtrl_Stat_AR2: id 0x2B9, from ECM, to ASX CPC FSCM TCM, frame-length=8, can-addressing-mode=STANDARD
        pdu EngCtrl_Stat_AR2: length=64, unused-bit-pattern=0, cyclic-timing={repeating-time=0.1, starting-time=0.065}, event-controlled-timing=number-of-repeats=0, minimum-delay=0.01
          signal AirPress_Outsd: start 40, 8 bit, little-endian, data-type=c08_hPa_0_1980_7k8, init-value=XDIS_2fhjzhyzrl6fjzklwzp7lg8jy/l255, transfer-property=PENDING, to CPC FSCM TCM  # Außenluftdruck / Outside air pressure
          signal CylCutoff_Stat: start 59, 2 bit, little-endian, data-type=c02_CylCutoff_Stat, init-value=lNO_ZAS, transfer-property=TRIGGERED-ON-CHANGE, to ASX CPC TCM  # Zylinderabschaltung Status / Cylinder cutoff state
          signal EngCoolTemp: start 32, 8 bit, little-endian, data-type=c08_degC_m40_214_1, init-value=XDIS_carqyv2gq7ncv789c849hnl6r/l255, transfer-property=PENDING, to CPC FSCM TCM  # Motorkühlmitteltemperatur / Engine coolant temperature
          signal EngOilQual: start 0, 8 bit, little-endian, data-type=c08_1_6_0k01969, init-value=XDIS_enuzrfb1f0b4exavz9gba8664/l255, transfer-property=PENDING, to CPC  # Motorölqualität / Engine oil quality
          signal FuelCons: start 8, 16 bit, little-endian, data-type=c16_ul_p_250ms_0_14200_0k21668, init-value=XDIS_a07pbof8nfjy6sopkumlg9k7r/l65535, transfer-property=PENDING, to CPC FSCM  # Verbrauch / Fuel consumption
          signal IntkAirTemp: start 24, 8 bit, little-endian, data-type=c08_degC_m40_214_1, init-value=XDIS_carqyv2gq7ncv789c849hnl6r/l255, transfer-property=PENDING, to CPC TCM  # Ansauglufttemperatur / Intake air temperature
          signal PN14_EHC_Prio_Rq: start 48, 3 bit, little-endian, data-type=c03_PN14_EHC_Prio_Rq, init-value=XDIS_2wcffyjyaskh0k7y4ufyneacn/lOFF, transfer-property=PENDING, to CPC  # Anforderung für EHC Priorität / Priority of EHC request
          signal PreHt_Stat: start 51, 1 bit, little-endian, data-type=DC_BOOL, init-value=XDIS_h5tcyk98kzbgrc5svasomeyt/lfalse, transfer-property=PENDING, to CPC  # Vorglühstatus / Preheating state
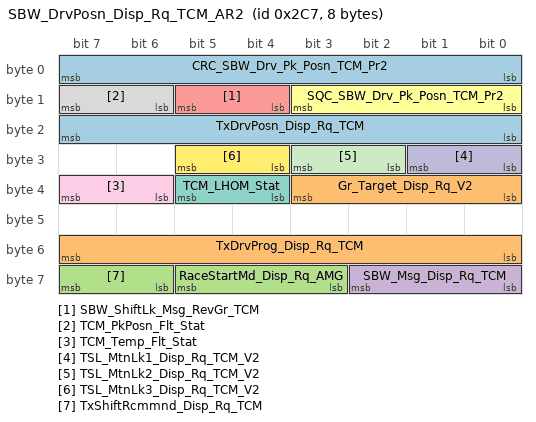
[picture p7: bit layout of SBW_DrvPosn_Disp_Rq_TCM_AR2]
      frame SBW_DrvPosn_Disp_Rq_TCM_AR2: id 0x2C7, from TCM, to CPC DRVU ECM, frame-length=8, can-addressing-mode=STANDARD  # Anzeige Shift by Wire und Fahrstufe / Shift by wire and driving position display request
        pdu SBW_DrvPosn_Disp_Rq_TCM_AR2: length=64, unused-bit-pattern=0, cyclic-timing={repeating-time=0.2, starting-time=0.17}, event-controlled-timing=number-of-repeats=0, minimum-delay=0.02  # Anzeige Shift by Wire und Fahrstufe / Shift by wire and driving position display request
          signal CRC_SBW_Drv_Pk_Posn_TCM_Pr2: start 0, 8 bit, little-endian, data-type=c08_CRC_woSNA, init-value=l205, transfer-property=PENDING, to CPC DRVU(timeout 2.1 s) ECM  # CRC-Checksumme der Signal Gruppe gemäß AUTOSAR Profil 2 / CRC-checksum of signal group according to AUTOSAR Profile 2
          signal Gr_Target_Disp_Rq_V2: start 32, 4 bit, little-endian, data-type=c04_Gr_Target_Disp_Rq_V2, init-value=XDIS_t15dy9y69dbq57aa6cdecyq/l15, transfer-property=TRIGGERED-ON-CHANGE, to CPC  # Anforderung Anzeige Zielgang / Target gear display request
          signal RaceStartMd_Disp_Rq_AMG: start 59, 3 bit, little-endian, data-type=c03_RaceStMd_Disp_Rq_AMG, init-value=XDIS_80m5pwr2zjsnpgmh203n30pqt/l7, transfer-property=TRIGGERED-ON-CHANGE, to CPC DRVU(timeout 2.1 s)  # Anzeige Rennstart-Modus / Race start mode display request
          signal SBW_Msg_Disp_Rq_TCM: start 56, 3 bit, little-endian, data-type=c03_SBW_Msg_Disp_Rq, init-value=XDIS_1btwp40vfzysklfc9vhyfb8lg/lIDLE, transfer-property=TRIGGERED-ON-CHANGE, to CPC  # Anforderung Shift by wire Meldung anzeigen / Shift by wire message display request
          signal SBW_ShiftLk_Msg_RevGr_TCM: start 12, 2 bit, little-endian, data-type=c02_SBW_ShiftLk_Msg_RevGr_TCM, init-value=XDIS_5ky3lk60o7o5ndyw6cx2aook/l3, transfer-property=TRIGGERED-ON-CHANGE, to CPC DRVU(timeout 2.1 s) ECM  # SBW Nachricht TCM "Bremse betätigen, um Rückwärtsgang einzulegen" / SBW Message from TCM "Press Brake to orient Reverse Gear"
          signal SQC_SBW_Drv_Pk_Posn_TCM_Pr2: start 8, 4 bit, little-endian, data-type=c04_0_15_1_SNA_na, init-value=XDIS_2gdok7is6uk227cngmpgf9wxb/l0, transfer-property=PENDING, to CPC DRVU(timeout 2.1 s) ECM  # Sequenzzähler / Sequence counter
          signal TCM_LHOM_Stat: start 36, 2 bit, little-endian, data-type=c02_TCM_LHOM_Stat, init-value=XDIS_7ksp2j8cgi96g5rowq7ywoklr/lIDLE, transfer-property=TRIGGERED-ON-CHANGE, to CPC(timeout 3.1 s)  # Status Getriebe Notabschaltung / TCM limp-home state
          signal TCM_PkPosn_Flt_Stat: start 14, 2 bit, little-endian, data-type=c02_TCM_PkPosn_Flt, init-value=XDIS_8k19ab1yez6czusrvo38kfnut/lIDLE, transfer-property=TRIGGERED-ON-CHANGE, to CPC DRVU(timeout 2.1 s) ECM  # Störung Parksperre / Transmission park position fault state
          signal TCM_Temp_Flt_Stat: start 38, 2 bit, little-endian, data-type=c02_TCM_Temp_Flt, init-value=XDIS_82nnft7uwz4cxp9vzn6tew6vu/lIDLE, transfer-property=TRIGGERED-ON-CHANGE, to CPC  # Getriebetemperatur Fehlerstatus / Transmission temperature fault state
          signal TSL_MtnLk1_Disp_Rq_TCM_V2: start 24, 2 bit, little-endian, data-type=c02_TSL_MtnLk_Disp_Rq_V2, init-value=XDIS_46hl4413mztp2ukvqdcv4cwpj/lIDLE, transfer-property=TRIGGERED-ON-CHANGE, to CPC  # Anforderung Getriebewählhebelsperre 1 Anzeige / Transmission selector lever motion lock 1 display request
          signal TSL_MtnLk2_Disp_Rq_TCM_V2: start 26, 2 bit, little-endian, data-type=c02_TSL_MtnLk2_3_Disp_Rq_V2, init-value=XDIS_ekoet742eksgh9ctith6nex6m/lIDLE, transfer-property=TRIGGERED-ON-CHANGE, to CPC  # Anforderung Getriebewählhebelsperre 2 Anzeige / Transmission selector lever motion lock 2 display request
          signal TSL_MtnLk3_Disp_Rq_TCM_V2: start 28, 2 bit, little-endian, data-type=c02_TSL_MtnLk2_3_Disp_Rq_V2, init-value=XDIS_ekoet742eksgh9ctith6nex6m/lIDLE, transfer-property=TRIGGERED-ON-CHANGE, to CPC  # Anforderung Getriebewählhebelsperre 3 Anzeige / Transmission selector lever motion lock 3 display request
          signal TxDrvPosn_Disp_Rq_TCM: start 16, 8 bit, little-endian, data-type=c08_TxDrvPosn, init-value=XDIS_1cx5hyudrxwg04ni87gsdlad7/l255, transfer-property=TRIGGERED-ON-CHANGE, to CPC DRVU(timeout 2.1 s) ECM  # Anforderung Anzeige Getriebefahrstufe / Transmission driving position display request
          signal TxDrvProg_Disp_Rq_TCM: start 48, 8 bit, little-endian, data-type=c08_TxDrvProg, init-value=XDIS_bh1p1818zl6ing1j8hr41frrg/l255, transfer-property=TRIGGERED-ON-CHANGE, to CPC DRVU(timeout 2.1 s) ECM  # Anforderung Anzeige Getriebefahrprogramm / Transmission driving program display request
          signal TxShiftRcmmnd_Disp_Rq_TCM: start 62, 2 bit, little-endian, data-type=c02_TxShftRcmnd_Disp_Rq_TCM, init-value=XDIS_cv70zed5pprac0yqjn2k05rnv/lIDLE, transfer-property=TRIGGERED-ON-CHANGE, to CPC  # Anforderung Anzeige Getriebeschaltempfehlung / Transmission shift recommendation display request
          signal SBW_Drv_Pk_Posn_TCM_Pr2_87jwxqxlzqql6r2vkjah89c7p: little-endian, system-signal=[CRC_SBW_Drv_Pk_Posn_TCM_Pr2, SBW_ShiftLk_Msg_RevGr_TCM, SQC_SBW_Drv_Pk_Posn_TCM_Pr2, TCM_PkPosn_Flt_Stat, TxDrvPosn_Disp_Rq_TCM], to CPC DRVU(timeout 2.1 s) ECM  # SBW_Drv_Pk_Posn_TCM_Pr2 (degraded)
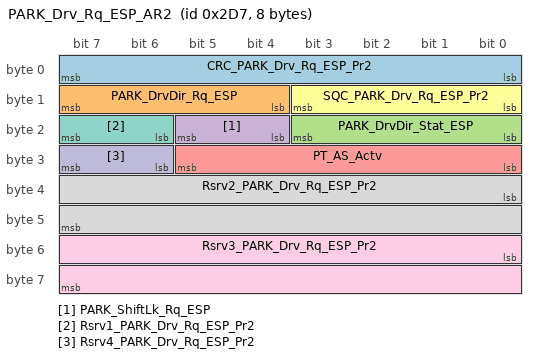
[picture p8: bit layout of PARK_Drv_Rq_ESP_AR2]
      frame PARK_Drv_Rq_ESP_AR2: id 0x2D7, from CPC, to ECM ISM TCM, frame-length=8, can-addressing-mode=STANDARD
        pdu PARK_Drv_Rq_ESP_AR2: length=64, unused-bit-pattern=0, cyclic-timing={repeating-time=0.1, starting-time=0.02}  # PARK fordert ESP an / PARK Requests ESP
          signal CRC_PARK_Drv_Rq_ESP_Pr2: start 0, 8 bit, little-endian, data-type=c08_CRC_woSNA, init-value=l175, to ECM ISM(timeout 1.05 s) TCM(timeout 1.05 s)  # CRC-Checksumme der Signal Gruppe gemäß AUTOSAR Profil 2 / CRC-checksum of signal group according to AUTOSAR Profile 2
          signal PARK_DrvDir_Rq_ESP: start 12, 4 bit, little-endian, data-type=c04_PARK_DrvDir_Rq_EBS, init-value=XDIS_4v614sdwfh8bujpigj1pmwdvy/lIDLE, to ECM ISM(timeout 1.05 s) TCM(timeout 1.05 s)  # ParkMan Fahrtrichtungsanforderung von ESP / ParkMan driving direction request from ESP
          signal PARK_DrvDir_Stat_ESP: start 16, 4 bit, little-endian, data-type=c04_PARK_DrvDir_Stat_EBS, init-value=XDIS_617d24xuqh44r69m83zq6at3s/lIDLE, to ECM ISM(timeout 1.05 s) TCM(timeout 1.05 s)  # ParkMan Fahrtrichtungsstatus von ESP / ParkMan driving direction state from ESP
          signal PARK_ShiftLk_Rq_ESP: start 20, 2 bit, little-endian, data-type=c02_PARK_ShiftLk_Rq_EBS, init-value=lACTIVE, to ECM ISM(timeout 1.05 s) TCM(timeout 1.05 s)  # ParkMan Anforderung Schaltsperre von ESP (Ermöglicht Verlassen von P) / ParkMan Shift-Lock request from ESP (enables leaving of P)
          signal PT_AS_Actv: start 24, 6 bit, little-endian, data-type=c06_VehAccel_X_AS_Actv, init-value=XDIS_7slpd5uy08tpkficw8xdx499o/lIDLE, to ECM ISM(timeout 1.05 s) TCM(timeout 1.05 s)  # Antwort aktives Assistenzsystem / Active assistance system response
          signal SQC_PARK_Drv_Rq_ESP_Pr2: start 8, 4 bit, little-endian, data-type=c04_0_15_1_SNA_na, init-value=XDIS_2gdok7is6uk227cngmpgf9wxb/l0, to ECM ISM(timeout 1.05 s) TCM(timeout 1.05 s)  # Sequenzzähler / Sequence counter
          signal Rsrv1_PARK_Drv_Rq_ESP_Pr2: start 22, 2 bit, little-endian, data-type=Rsrv02, init-value=XDIS_7jeo5ges9wp8ufla3pohsuw83/l0, to ECM ISM TCM  # Reserviert für zukünftige Verwendung / Reserved for future use
          signal Rsrv2_PARK_Drv_Rq_ESP_Pr2: start 32, 16 bit, little-endian, data-type=Rsrv16, init-value=XDIS_dn8lf2t3vtro1vkmqfxqg05qy/l0, to ECM ISM TCM  # Reserviert für zukünftige Verwendung / Reserved for future use
          signal Rsrv3_PARK_Drv_Rq_ESP_Pr2: start 48, 16 bit, little-endian, data-type=Rsrv16, init-value=XDIS_dn8lf2t3vtro1vkmqfxqg05qy/l0, to ECM ISM TCM  # Reserviert für zukünftige Verwendung / Reserved for future use
          signal Rsrv4_PARK_Drv_Rq_ESP_Pr2: start 30, 2 bit, little-endian, data-type=Rsrv02, init-value=XDIS_7jeo5ges9wp8ufla3pohsuw83/l0, to ECM ISM TCM  # Reserviert für zukünftige Verwendung / Reserved for future use
          signal PARK_Drv_Rq_ESP_Pr2_156rahkn2e7mmvc2542gbao5u: little-endian, system-signal=[CRC_PARK_Drv_Rq_ESP_Pr2, PARK_DrvDir_Rq_ESP, PARK_DrvDir_Stat_ESP, PARK_ShiftLk_Rq_ESP, PT_AS_Actv, Rsrv1_PARK_Drv_Rq_ESP_Pr2, Rsrv2_PARK_Drv_Rq_ESP_Pr2, Rsrv3_PARK_Drv_Rq_ESP_Pr2, Rsrv4_PARK_Drv_Rq_ESP_Pr2, SQC_PARK_Drv_Rq_ESP_Pr2], transfer-property=PENDING, to ECM ISM(timeout 1.05 s) TCM(timeout 1.05 s)  # PARK fordert ESP an (degraded) / PARK Requests ESP (degraded)
      frame PARK_Drv_Rs_TCM_AR2: id 0x2EE, from ISM TCM, to CPC, frame-length=8, can-addressing-mode=STANDARD
        pdu PARK_Drv_Rs_TCM_AR2: length=64, unused-bit-pattern=0, cyclic-timing={repeating-time=0.12, starting-time=0.03}  # TCM Antwort an PARK / TCM response to PARK
          signal CRC_PARK_Drv_Rs_TCM_Pr2: start 0, 8 bit, little-endian, data-type=c08_CRC_woSNA, init-value=l192, to CPC  # CRC-Checksumme der Signal Gruppe gemäß AUTOSAR Profil 2 / CRC-checksum of signal group according to AUTOSAR Profile 2
          signal PARK_DrvDir_Stat_TCM: start 12, 4 bit, little-endian, data-type=c04_PARK_DrvDir_Stat_EBS, init-value=XDIS_5cef29zuo9cutic9pjz31ahco/l15, to CPC  # ParkMan Status Fahrtrichtung von TCM / ParkMan driving direction state from TCM
          signal SQC_PARK_Drv_Rs_TCM_Pr2: start 8, 4 bit, little-endian, data-type=c04_0_15_1_SNA_na, init-value=XDIS_2gdok7is6uk227cngmpgf9wxb/l0, to CPC  # Sequenzzähler / Sequence counter
          signal TCM_Dir_Stat: start 16, 5 bit, little-endian, data-type=c05_TCM_Dir_Stat, init-value=XDIS_2quzou7gbuptic5scarc72vwd/l31, to CPC  # ParkMan: Mögliche Richtungen des TCM / ParkMan possible directions from TCM
          signal Rsrv1_PARK_Drv_Rs_TCM_Pr2: start 21, 11 bit, little-endian, data-type=Rsrv11, init-value=XDIS_e2tmoqhrqj608ty4o78grs9ui/l0, to CPC  # Reserviert für zukünftige Verwendung / Reserved for future use
          signal Rsrv2_PARK_Drv_Rs_TCM_Pr2: start 32, 8 bit, little-endian, data-type=Rsrv08, init-value=XDIS_4flxbk4wkjkdew7cw07d9of66/l0, to CPC  # Reserviert für zukünftige Verwendung / Reserved for future use
          signal PARK_Drv_Rs_TCM_Pr2_oe4nkdc61vmdsai3dvff2tvs: little-endian, system-signal=[CRC_PARK_Drv_Rs_TCM_Pr2, PARK_DrvDir_Stat_TCM, Rsrv1_PARK_Drv_Rs_TCM_Pr2, Rsrv2_PARK_Drv_Rs_TCM_Pr2, SQC_PARK_Drv_Rs_TCM_Pr2, TCM_Dir_Stat], transfer-property=PENDING, to CPC  # TCM Antwort an PARK (degraded) / TCM response to PARK (degraded)
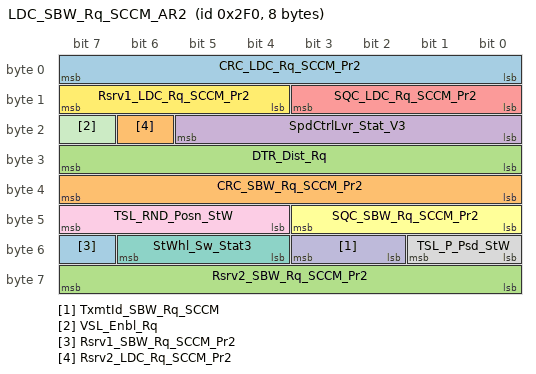
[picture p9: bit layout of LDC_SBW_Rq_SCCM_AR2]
      frame LDC_SBW_Rq_SCCM_AR2: id 0x2F0, from CPC, to ECM ISM TCM, frame-length=8, can-addressing-mode=STANDARD  # SCCM-Anforderungen Längsregler und Shift by Wire / Longitudinal controller and shift by wire request by SCCM
        pdu LDC_SBW_Rq_SCCM_AR2: length=64, unused-bit-pattern=0, cyclic-timing=repeating-time=0.2, event-controlled-timing=number-of-repeats=0, minimum-delay=0.02  # SCCM-Anforderungen Längsregler und Shift by Wire / Longitudinal controller and shift by wire request by SCCM
          signal CRC_LDC_Rq_SCCM_Pr2: start 0, 8 bit, little-endian, data-type=c08_CRC_woSNA, init-value=l196, transfer-property=PENDING, to ECM TCM  # CRC-Checksumme der Signal Gruppe gemäß AUTOSAR Profil 2 / CRC-checksum of signal group according to AUTOSAR Profile 2
          signal CRC_SBW_Rq_SCCM_Pr2: start 32, 8 bit, little-endian, data-type=c08_CRC_woSNA, init-value=l219, transfer-property=PENDING, to ECM ISM TCM  # CRC-Checksumme der Signal Gruppe gemäß AUTOSAR Profil 2 / CRC-checksum of signal group according to AUTOSAR Profile 2
          signal DTR_Dist_Rq: start 24, 8 bit, little-endian, data-type=c08_0_200_1, init-value=XDIS_37r48co1agrbd30wx53gabdmv/l255, transfer-property=TRIGGERED-ON-CHANGE, to ECM TCM  # DTR Abstandsfaktor / Distronic distance factor request
          signal SpdCtrlLvr_Stat_V3: start 16, 6 bit, little-endian, data-type=c02_SpdCtrlLvr_Stat_V3, init-value=lFWD, transfer-property=TRIGGERED-ON-CHANGE, to ECM TCM  # Tempomatwählhebel betätigt / Speed control lever state
          signal SQC_LDC_Rq_SCCM_Pr2: start 8, 4 bit, little-endian, data-type=c04_0_15_1_SNA_na, init-value=XDIS_2gdok7is6uk227cngmpgf9wxb/l0, transfer-property=PENDING, to ECM TCM  # Sequenzzähler / Sequence counter
          signal SQC_SBW_Rq_SCCM_Pr2: start 40, 4 bit, little-endian, data-type=c04_0_15_1_SNA_na, init-value=XDIS_2gdok7is6uk227cngmpgf9wxb/l0, transfer-property=PENDING, to ECM ISM TCM  # Sequenzzähler / Sequence counter
          signal StWhl_Sw_Stat3: start 52, 3 bit, little-endian, data-type=c03_StWhl_Sw_Stat3, init-value=XDIS_6y1s8o04spumiv3g0r74kz1ku/lINI, transfer-property=TRIGGERED-ON-CHANGE, to ECM ISM TCM  # Lenkradtasten "+", "-" betätigt / State steering wheel switch ("+","-")
          signal TSL_P_Psd_StW: start 48, 2 bit, little-endian, data-type=c02_TSL_P_Psd_StW, init-value=XDIS_14t9fsb52vme4w2qcdz9a54fa/lINI, transfer-property=TRIGGERED-ON-CHANGE, to ECM ISM TCM  # Getriebewählhebel "P" betätigt / Transmission selector lever "P" switch actuated (steering wheel)
          signal TSL_RND_Posn_StW: start 44, 4 bit, little-endian, data-type=c04_TSL_RND_Posn_StW, init-value=XDIS_arh4cc0juzqoc7r4h5upl0lsk/lINI, transfer-property=TRIGGERED-ON-CHANGE, to ECM ISM TCM  # Getriebewählhebel RND-Stellung (Lenkrad) / Transmission selector lever RND position (steering wheel)
          signal TxmtId_SBW_Rq_SCCM: start 50, 2 bit, little-endian, data-type=c02_TxmtId_SBW_Rq_SCCM, init-value=XDIS_e06dodsc3ez64f6agiitc7pqb/lEWM, transfer-property=TRIGGERED-ON-CHANGE, to ECM ISM TCM  # Senderkennung / Transmitter identification
          signal VSL_Enbl_Rq: start 23, 1 bit, little-endian, data-type=DC_BOOL, init-value=XDIS_h5tcyk98kzbgrc5svasomeyt/lfalse, transfer-property=TRIGGERED-ON-CHANGE, to ECM TCM  # Bedienung variable Geschwindigkeitsbegrenzung / Enable variable speed limiter request
          signal Rsrv1_LDC_Rq_SCCM_Pr2: start 12, 4 bit, little-endian, data-type=Rsrv04, init-value=XDIS_eb9yua4lxmhrmvzyfsmxg3ler/l0, transfer-property=PENDING, to ECM ISM TCM  # Reserviert für zukünftige Verwendung / Reserved for future use
          signal Rsrv1_SBW_Rq_SCCM_Pr2: start 55, 1 bit, little-endian, data-type=Rsrv01, init-value=XDIS_e2uhxyvdu33zsyqfjnk549pp2/l0, transfer-property=PENDING, to ECM ISM TCM  # Reserviert für zukünftige Verwendung / Reserved for future use
          signal Rsrv2_LDC_Rq_SCCM_Pr2: start 22, 1 bit, little-endian, data-type=Rsrv01, init-value=XDIS_e2uhxyvdu33zsyqfjnk549pp2/l0, transfer-property=PENDING, to ECM ISM TCM  # Reserviert für zukünftige Verwendung / Reserved for future use
          signal Rsrv2_SBW_Rq_SCCM_Pr2: start 56, 8 bit, little-endian, data-type=Rsrv08, init-value=XDIS_4flxbk4wkjkdew7cw07d9of66/l0, transfer-property=PENDING, to ECM ISM TCM  # Reserviert für zukünftige Verwendung / Reserved for future use
          signal LDC_Rq_SCCM_Pr2_1urxjv3xbtzkrxlqmdhowxf5n: little-endian, system-signal=[CRC_LDC_Rq_SCCM_Pr2, DTR_Dist_Rq, Rsrv1_LDC_Rq_SCCM_Pr2, Rsrv2_LDC_Rq_SCCM_Pr2, SpdCtrlLvr_Stat_V3, SQC_LDC_Rq_SCCM_Pr2, VSL_Enbl_Rq], to ECM TCM  # SCCM-Anforderungen Längsregler (degraded) / Longitudinal controller request by SCCM (degraded)
          signal SBW_Rq_SCCM_Pr2_1bw4xg1pomod9nov43ee8m7kx: little-endian, system-signal=[CRC_SBW_Rq_SCCM_Pr2, Rsrv1_SBW_Rq_SCCM_Pr2, Rsrv2_SBW_Rq_SCCM_Pr2, SQC_SBW_Rq_SCCM_Pr2, StWhl_Sw_Stat3, TSL_P_Psd_StW, TSL_RND_Posn_StW, TxmtId_SBW_Rq_SCCM], to ECM ISM TCM  # SCCM-Anforderungen Shift by Wire (degraded) / Shift by wire request by SCCM (degraded)
      frame EVC_CfgBit_01_32_AR2: id 0x2F1, from CPC, to ECM TCM, frame-length=8, can-addressing-mode=STANDARD  # EVC-CfgMessage[Bitfield:01h-32h]
        pdu EVC_CfgBit_01_32_AR2: length=64, unused-bit-pattern=0, cyclic-timing=repeating-time=1.0  # EVC-CfgMessage[Bitfeld:01h-32h] / EVC-CfgMessage[Bitfield:01h-32h]
          signal CRC_EVC_CfgBit_01_32_Pr2: start 0, 8 bit, little-endian, data-type=c08_CRC_woSNA, init-value=l221, to ECM TCM  # CRC-Checksumme der Signal Gruppe gemäß AUTOSAR Profil 2 / CRC-checksum of signal group according to AUTOSAR Profile 2
          signal EVC_01_Ver_USA_Avl: start 14, 1 bit, little-endian, data-type=DC_BOOL, init-value=XDIS_h5tcyk98kzbgrc5svasomeyt/lfalse, to ECM TCM  # 494 USA-AUSFUEHRUNG / 494 VERSION FOR USA
          signal EVC_02_Ver_Mexico_Avl: start 15, 1 bit, little-endian, data-type=DC_BOOL, init-value=XDIS_h5tcyk98kzbgrc5svasomeyt/lfalse, to ECM TCM  # 496 MEXIKO-AUSFUEHRUNG / 496 VERSION FOR MEXICO
          signal EVC_03_Ver_Japan_Avl: start 16, 1 bit, little-endian, data-type=DC_BOOL, init-value=XDIS_h5tcyk98kzbgrc5svasomeyt/lfalse, to ECM TCM  # 498 JAPAN-AUSFUEHRUNG / 498 VERSION FOR JAPAN
          signal EVC_04_Ver_GulfStates_Avl: start 17, 1 bit, little-endian, data-type=DC_BOOL, init-value=XDIS_h5tcyk98kzbgrc5svasomeyt/lfalse, to ECM TCM  # 623 GOLF-STAATEN-AUSFUEHRUNG / 623 VERSION FOR GULF STATES
          signal EVC_05_Ver_Australia_Avl: start 18, 1 bit, little-endian, data-type=DC_BOOL, init-value=XDIS_h5tcyk98kzbgrc5svasomeyt/lfalse, to ECM TCM  # 625 AUSTRALIEN-AUSFUEHRUNG / 625 VERSION FOR AUSTRALIA
          signal EVC_06_Ver_China_Avl: start 19, 1 bit, little-endian, data-type=DC_BOOL, init-value=XDIS_h5tcyk98kzbgrc5svasomeyt/lfalse, to ECM TCM  # 830 CHINA-FAHRZEUGE-ZUSATZTEILE / 830 VEHICLES FOR CHINA-ADDITIONAL PARTS
          signal EVC_07_Ver_S_Korea_Avl: start 20, 1 bit, little-endian, data-type=DC_BOOL, init-value=XDIS_h5tcyk98kzbgrc5svasomeyt/lfalse, to ECM TCM  # 835 KOREA-SUED-ZUSATZTEILE / 835 SOUTHERN KOREA-SUPPLEMENTARY PARTS
          signal EVC_08_Ver_Canada_Avl: start 21, 1 bit, little-endian, data-type=DC_BOOL, init-value=XDIS_h5tcyk98kzbgrc5svasomeyt/lfalse, to ECM TCM  # 460 KANADA-AUSFUEHRUNG / ZUSATZTEILE / 460 VEHICLES FOR CANADA, ADDITIONAL PARTS
          signal EVC_09_FullHyb_Avl: start 22, 1 bit, little-endian, data-type=DC_BOOL, init-value=XDIS_h5tcyk98kzbgrc5svasomeyt/lfalse, to ECM TCM  # ME03 FULL-HYBRID ANTRIEB / ME03 FULL-HYBRID DRIVE
          signal EVC_0A_Hyb_20kW_Avl: start 23, 1 bit, little-endian, data-type=DC_BOOL, init-value=XDIS_h5tcyk98kzbgrc5svasomeyt/lfalse, to ECM TCM  # ME04 HYBRIDANTRIEB 20KW - VARIANTE / ME04 HYBRID DRIVE 20KW - VERSION
          signal EVC_0B_PlugInHyb_80kW_Avl: start 24, 1 bit, little-endian, data-type=DC_BOOL, init-value=XDIS_h5tcyk98kzbgrc5svasomeyt/lfalse, to ECM TCM  # ME05 HYBRIDANTRIEB 80 KW - VARIANTE (INKLUSIVE PLUGIN) / ME05 HYBRID DRIVE 80 KW - VERSION (INCLUSIVE PLUGIN)
          signal EVC_0C_AllWheelDr_Avl: start 25, 1 bit, little-endian, data-type=DC_BOOL, init-value=XDIS_h5tcyk98kzbgrc5svasomeyt/lfalse, to ECM TCM  # M005 FAHRZEUGE MIT 4-MATIC-/ALLRAD-ANTRIEB / M005 CHASSIS WITH 4-MATIC-/ALL-WHEEL DRIVE
          signal EVC_0D_4x2Drive_Avl: start 26, 1 bit, little-endian, data-type=DC_BOOL, init-value=XDIS_h5tcyk98kzbgrc5svasomeyt/lfalse, to ECM TCM  # M007 FAHRZEUGE MIT 4X2 ANTRIEB / M007 CHASSIS WITH 4X2 DRIVE
          signal EVC_0E_Presf_Avl: start 27, 1 bit, little-endian, data-type=DC_BOOL, init-value=XDIS_h5tcyk98kzbgrc5svasomeyt/lfalse, to ECM TCM  # 299 PRESAFE
          signal EVC_0F_TrlrHtch_Avl: start 28, 1 bit, little-endian, data-type=DC_BOOL, init-value=XDIS_h5tcyk98kzbgrc5svasomeyt/lfalse, to ECM TCM  # 550 ANHAENGEVORRICHTUNG / 550 TRAILER HITCH
          signal EVC_10_KG_Avl: start 29, 1 bit, little-endian, data-type=DC_BOOL, init-value=XDIS_h5tcyk98kzbgrc5svasomeyt/lfalse, to ECM TCM  # 889 KEYLESS - GO
          signal EVC_11_AutTrunkLid_Avl: start 30, 1 bit, little-endian, data-type=DC_BOOL, init-value=XDIS_h5tcyk98kzbgrc5svasomeyt/lfalse, to ECM TCM  # 881 HECKDECKEL-FERNSCHLIESSUNG / 881 TRUNK LID REMOTE LOCKING
          signal EVC_12_AutRearDr_Avl: start 31, 1 bit, little-endian, data-type=DC_BOOL, init-value=XDIS_h5tcyk98kzbgrc5svasomeyt/lfalse, to ECM TCM  # 890 AUTOMATISCHE RUECKWANDTUER / 890 AUTOMATIC REAR DOOR
          signal EVC_13_PwrCls_Avl: start 32, 1 bit, little-endian, data-type=DC_BOOL, init-value=XDIS_h5tcyk98kzbgrc5svasomeyt/lfalse, to ECM TCM  # 883 SERVOSCHLIESSUNG / 883 CLOSING AID
          signal EVC_14_RainSens_Avl: start 33, 1 bit, little-endian, data-type=DC_BOOL, init-value=XDIS_h5tcyk98kzbgrc5svasomeyt/lfalse, to ECM TCM  # 345 REGENSENSOR / 345 RAIN SENSOR
          signal EVC_15_DRLt_Avl: start 34, 1 bit, little-endian, data-type=DC_BOOL, init-value=XDIS_h5tcyk98kzbgrc5svasomeyt/lfalse, to ECM TCM  # 236 TAGFAHRLICHT / 236 DAYTIME RUNNING LAMP
          signal EVC_16_FogLmp_Avl: start 35, 1 bit, little-endian, data-type=DC_BOOL, init-value=XDIS_h5tcyk98kzbgrc5svasomeyt/lfalse, to ECM TCM  # U37 NEBELSCHEINWERFER / U37 FOG LAMPS
          signal EVC_17_IL_Pk_Avl: start 36, 1 bit, little-endian, data-type=DC_BOOL, init-value=XDIS_h5tcyk98kzbgrc5svasomeyt/lfalse, to ECM TCM  # 876 INNENRAUM-LICHTPAKET / 876 INTERIOR LIGHT ASSY.
          signal EVC_18_AmbLgt_Avl: start 37, 1 bit, little-endian, data-type=DC_BOOL, init-value=XDIS_h5tcyk98kzbgrc5svasomeyt/lfalse, to ECM TCM  # 877 AMBIENTENBELEUCHTUNG / 877 AMBIENCE LIGHTING
          signal EVC_19_ElDrPosnSel_Avl: start 38, 1 bit, little-endian, data-type=DC_BOOL, init-value=XDIS_h5tcyk98kzbgrc5svasomeyt/lfalse, to ECM TCM  # 279 FAHRSTUFENWAHL ELEKTRONISCH / 279 ELECTRICAL DRIVE POSITION SELECTION
          signal EVC_1A_IntSfProt_Avl: start 39, 1 bit, little-endian, data-type=DC_BOOL, init-value=XDIS_h5tcyk98kzbgrc5svasomeyt/lfalse, to ECM TCM  # 882 INNENRAUMABSICHERUNG / 882 INTERIOR SAFEGUARD/TOWING PROTECTION
          signal EVC_1B_VTA_Avl: start 40, 1 bit, little-endian, data-type=DC_BOOL, init-value=XDIS_h5tcyk98kzbgrc5svasomeyt/lfalse, to ECM TCM  # 551 EINBRUCH- UND DIEBSTAHLWARNANLAGE (EDW) / 551 THEFT WARNING SYSTEM
          signal EVC_1C_HghVTP_Avl: start 41, 1 bit, little-endian, data-type=DC_BOOL, init-value=XDIS_h5tcyk98kzbgrc5svasomeyt/lfalse, to ECM TCM  # 885 ERHOEHTER DIEBSTAHLSCHUTZ / 885 HIGHTEN THEFT PROTECTION
          signal EVC_1D_SecurityVer_Avl: start 42, 1 bit, little-endian, data-type=DC_BOOL, init-value=XDIS_h5tcyk98kzbgrc5svasomeyt/lfalse, to ECM TCM  # 979 SONDERSCHUTZ-AUSFUEHRUNG / 979 SECURITY VERSION
          signal EVC_1E_GuardLvl_B4_Avl: start 43, 1 bit, little-endian, data-type=DC_BOOL, init-value=XDIS_h5tcyk98kzbgrc5svasomeyt/lfalse, to ECM TCM  # Z04 B4-PANZERUNG BEI SONDERSCHUTZAUSFUEHRUNG / Z04 B4-ARMOR-PLATING FOR SECURITY VERSION
          signal EVC_1F_GuardLvl_B6_Avl: start 44, 1 bit, little-endian, data-type=DC_BOOL, init-value=XDIS_h5tcyk98kzbgrc5svasomeyt/lfalse, to ECM TCM  # Z06 B6-PANZERUNG BEI SONDERSCHUTZAUSFUEHRUNG / Z06 B6-ARMOR-PLATING FOR SECURITY VERSION
          signal EVC_20_GuardLvl_B7_Avl: start 45, 1 bit, little-endian, data-type=DC_BOOL, init-value=XDIS_h5tcyk98kzbgrc5svasomeyt/lfalse, to ECM TCM  # Z07 B7-PANZERUNG BEI SONDERSCHUTZAUSFUEHRUNG / Z07 B7-ARMOR-PLATING FOR SECURITY VERSION
          signal EVC_21_Pullman_Avl: start 46, 1 bit, little-endian, data-type=DC_BOOL, init-value=XDIS_h5tcyk98kzbgrc5svasomeyt/lfalse, to ECM TCM  # Z19 STAATSLIMOUSINE FVV PULLMAN / Z19 STATE COACH FVV PULLMAN
          signal EVC_22_SpecClos_Avl: start 47, 1 bit, little-endian, data-type=DC_BOOL, init-value=XDIS_h5tcyk98kzbgrc5svasomeyt/lfalse, to ECM TCM  # Z93 SONDERVERRIEGELUNG TANKDECKEL / Z93 SPECIAL LOCKING TANK CAP
          signal EVC_23_PASS_Avl: start 48, 1 bit, little-endian, data-type=DC_BOOL, init-value=XDIS_h5tcyk98kzbgrc5svasomeyt/lfalse, to ECM TCM  # 348 NOTRUF - / ASSISTENTSYSTEM / 348 EMERGENCY-/ASSISTANT SYSTEM
          signal EVC_24_ICH_Avl: start 49, 1 bit, little-endian, data-type=DC_BOOL, init-value=XDIS_h5tcyk98kzbgrc5svasomeyt/lfalse, to ECM TCM  # 228 ZUSATZHEIZUNG / 228 AUXILIARY HEATING
          signal EVC_25_HVAC_R_Avl: start 50, 1 bit, little-endian, data-type=DC_BOOL, init-value=XDIS_h5tcyk98kzbgrc5svasomeyt/lfalse, to ECM TCM  # 582 KLIMAANLAGE IM FOND / 582 CLIMATE CONTROL SYSTEM IN REAR
          signal EVC_26_SSA_Avl: start 51, 1 bit, little-endian, data-type=DC_BOOL, init-value=XDIS_h5tcyk98kzbgrc5svasomeyt/lfalse, to ECM TCM  # B03 DIREKTSTART / ECO START-STOP-FUNKTION / B03 DIREKTSTART / STOP-START-AUTOMATIC
          signal EVC_27_HandsFreeAcc_Avl: start 52, 1 bit, little-endian, data-type=DC_BOOL, init-value=XDIS_h5tcyk98kzbgrc5svasomeyt/lfalse, to ECM TCM  # 871 SENSORIK F. HECKDECKELOEFFNUNG/SCHLIESSUNG / 871 HANDSFREE ACCESS
          signal EVC_28_PlugInHyb_50kW_Avl: start 53, 1 bit, little-endian, data-type=DC_BOOL, init-value=XDIS_h5tcyk98kzbgrc5svasomeyt/lfalse, to ECM TCM  # ME06 HYBRIDANTRIEB 50 KW - VARIANTE (INKLUSIVE PLUGIN) / ME06 HYBRID DRIVE 50 KW - VERSION (INCLUSIVE PLUGIN)
          signal EVC_29_Hyb_30kW_Avl: start 54, 1 bit, little-endian, data-type=DC_BOOL, init-value=XDIS_h5tcyk98kzbgrc5svasomeyt/lfalse, to ECM TCM  # ME07 HYBRIDANTRIEB 30 KW - VARIANTE / ME07 HYBRID DRIVE 30 KW - VERSION
          signal EVC_2A_SeatElAdj_F_OprtnR_Avl: start 55, 1 bit, little-endian, data-type=DC_BOOL, init-value=XDIS_h5tcyk98kzbgrc5svasomeyt/lfalse, to ECM TCM  # 247 SITZVERSTELLUNG EL.ZUSAETZLICH VOM FOND BEDIENBAR / 247 SEAT ADJUSTMENT ELEC. ALSO OPERABLE FROM REAR
          signal EVC_2B_DSI_Sel_Avl: start 56, 1 bit, little-endian, data-type=DC_BOOL, init-value=XDIS_h5tcyk98kzbgrc5svasomeyt/lfalse, to ECM TCM  # 445 DSI-Wählhebel am Lenkrad / 445 DSI-selector on steering wheel
          signal EVC_2C_WC_VEDA_Avl: start 57, 1 bit, little-endian, data-type=DC_BOOL, init-value=XDIS_h5tcyk98kzbgrc5svasomeyt/lfalse, to ECM TCM  # 896 DRAHTLOSE AUFLADUNG, FAHRZEUGZUGANG UND BERECHTIG. / 896 WIRELESS CHARGING, VEHICLE ENTR.A.DRIVING AUTHOR.
          signal EVC_2D_AutoSpdCtrl_Avl: start 58, 1 bit, little-endian, data-type=DC_BOOL, init-value=XDIS_h5tcyk98kzbgrc5svasomeyt/lfalse, to ECM TCM  # 546 AUTOMATISCHE GESCHWINDIGKEITSREGELUNG / 546 AUTOMATIC SPEED CONTROL
          signal EVC_2E_AddEquipBlock_Avl: start 59, 1 bit, little-endian, data-type=DC_BOOL, init-value=XDIS_h5tcyk98kzbgrc5svasomeyt/lfalse, to ECM TCM  # 2Eh weitere Ausstattung Blockiert (kann nicht verwendet werden) / 2Eh Additional Equipment Blocked (not for use)
          signal EVC_2F_AddEquip_Avl: start 60, 1 bit, little-endian, data-type=DC_BOOL, init-value=XDIS_h5tcyk98kzbgrc5svasomeyt/lfalse, to ECM TCM  # 2Fh weitere Ausstattung (noch nicht genauer definiert) / 2Fh Additional Equipment (not specialized yet)
          signal EVC_30_AddEquip_Avl: start 61, 1 bit, little-endian, data-type=DC_BOOL, init-value=XDIS_h5tcyk98kzbgrc5svasomeyt/lfalse, to ECM TCM  # 30h weitere Ausstattung (noch nicht genauer definiert) / 30h Additional Equipment (not specialized yet)
          signal EVC_31_AddEquip_Avl: start 62, 1 bit, little-endian, data-type=DC_BOOL, init-value=XDIS_h5tcyk98kzbgrc5svasomeyt/lfalse, to ECM TCM  # 31h weitere Ausstattung (noch nicht genauer definiert) / 31h Additional Equipment (not specialized yet)
          signal EVC_32_AddEquip_Avl: start 63, 1 bit, little-endian, data-type=DC_BOOL, init-value=XDIS_h5tcyk98kzbgrc5svasomeyt/lfalse, to ECM TCM  # 32h weitere Ausstattung (noch nicht genauer definiert) / 32h Additional Equipment (not specialized yet)
          signal EVC_CfgBit_01_32_Stat: start 12, 2 bit, little-endian, data-type=c02_EVC_Stat, init-value=XDIS_b0sx1bf1u21ozu36byqxxhp5b/l3, to ECM TCM  # Status EVC-CfgMessage[Bitfeld:01h-32h] / Status EVC-CfgMessage[Bitfield:01h-32h]
          signal SQC_EVC_CfgBit_01_32_Pr2: start 8, 4 bit, little-endian, data-type=c04_0_15_1_SNA_na, init-value=XDIS_2gdok7is6uk227cngmpgf9wxb/l0, to ECM TCM  # Sequenzzähler / Sequence counter
          signal EVC_CfgBit_01_32_Pr2_bczisb61ims7titum6cc8o5oq: little-endian, system-signal=[CRC_EVC_CfgBit_01_32_Pr2, EVC_01_Ver_USA_Avl, EVC_02_Ver_Mexico_Avl, EVC_03_Ver_Japan_Avl, EVC_04_Ver_GulfStates_Avl, EVC_05_Ver_Australia_Avl, EVC_06_Ver_China_Avl, EVC_07_Ver_S_Korea_Avl, EVC_08_Ver_Canada_Avl, EVC_09_FullHyb_Avl, EVC_0A_Hyb_20kW_Avl, EVC_0B_PlugInHyb_80kW_Avl, EVC_0C_AllWheelDr_Avl, EVC_0D_4x2Drive_Avl, EVC_0E_Presf_Avl, EVC_0F_TrlrHtch_Avl, EVC_10_KG_Avl, EVC_11_AutTrunkLid_Avl, EVC_12_AutRearDr_Avl, EVC_13_PwrCls_Avl, EVC_14_RainSens_Avl, EVC_15_DRLt_Avl, EVC_16_FogLmp_Avl, EVC_17_IL_Pk_Avl, EVC_18_AmbLgt_Avl, EVC_19_ElDrPosnSel_Avl, EVC_1A_IntSfProt_Avl, EVC_1B_VTA_Avl, EVC_1C_HghVTP_Avl, EVC_1D_SecurityVer_Avl, EVC_1E_GuardLvl_B4_Avl, EVC_1F_GuardLvl_B6_Avl, EVC_20_GuardLvl_B7_Avl, EVC_21_Pullman_Avl, EVC_22_SpecClos_Avl, EVC_23_PASS_Avl, EVC_24_ICH_Avl, EVC_25_HVAC_R_Avl, EVC_26_SSA_Avl, EVC_27_HandsFreeAcc_Avl, EVC_28_PlugInHyb_50kW_Avl, EVC_29_Hyb_30kW_Avl, EVC_2A_SeatElAdj_F_OprtnR_Avl, EVC_2B_DSI_Sel_Avl, EVC_2C_WC_VEDA_Avl, EVC_2D_AutoSpdCtrl_Avl, EVC_2E_AddEquipBlock_Avl, EVC_2F_AddEquip_Avl, EVC_30_AddEquip_Avl, EVC_31_AddEquip_Avl, EVC_32_AddEquip_Avl, EVC_CfgBit_01_32_Stat, SQC_EVC_CfgBit_01_32_Pr2], transfer-property=PENDING, to ECM TCM  # EVC-CfgMessage[Bitfeld:01h-32h] (degraded) / EVC-CfgMessage[Bitfield:01h-32h] (degraded)
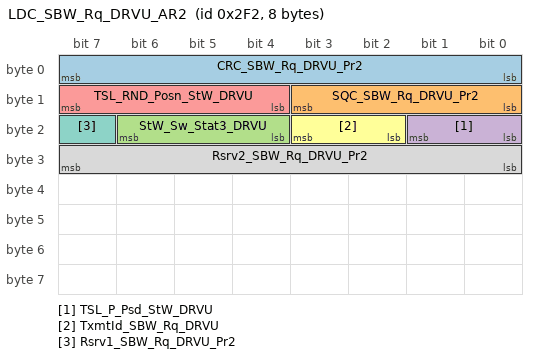
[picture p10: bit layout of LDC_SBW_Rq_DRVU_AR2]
      frame LDC_SBW_Rq_DRVU_AR2: id 0x2F2, from DRVU, to CPC ISM TCM, frame-length=8, can-addressing-mode=STANDARD  # SCCM-Anforderungen Längsregler und Shift by Wire / Longitudinal controller and shift by wire request by SCCM
        pdu LDC_SBW_Rq_DRVU_AR2: length=64, unused-bit-pattern=0, cyclic-timing={repeating-time=0.2, starting-time=0.1}, event-controlled-timing=number-of-repeats=0, minimum-delay=0.02  # SCCM-Anforderungen Längsregler und Shift by Wire / Longitudinal controller and shift by wire request by SCCM
          signal CRC_SBW_Rq_DRVU_Pr2: start 0, 8 bit, little-endian, data-type=c08_CRC_woSNA, init-value=l126, transfer-property=PENDING, to CPC ISM TCM  # CRC-Checksumme der Signal Gruppe gemäß AUTOSAR Profil 2 / CRC-checksum of signal group according to AUTOSAR Profile 2
          signal SQC_SBW_Rq_DRVU_Pr2: start 8, 4 bit, little-endian, data-type=c04_0_15_1_SNA_na, init-value=XDIS_2gdok7is6uk227cngmpgf9wxb/l0, transfer-property=PENDING, to CPC ISM TCM  # Sequenzzähler / Sequence counter
          signal StW_Sw_Stat3_DRVU: start 20, 3 bit, little-endian, data-type=c03_Npsd_Plus_Minus, init-value=lNPSD, transfer-property=TRIGGERED-ON-CHANGE, to CPC ISM TCM  # Lenkradtasten "+", "-" betätigt / State steering wheel switch ("+","-")
          signal TSL_P_Psd_StW_DRVU: start 16, 2 bit, little-endian, data-type=c02_TSL_P_Psd_StW, init-value=XDIS_14t9fsb52vme4w2qcdz9a54fa/lINI, transfer-property=TRIGGERED-ON-CHANGE, to CPC ISM TCM  # Getriebewählhebel "P" betätigt / Transmission selector lever "P" switch actuated (steering wheel)
          signal TSL_RND_Posn_StW_DRVU: start 12, 4 bit, little-endian, data-type=c04_TSL_RND_Posn_StW, init-value=XDIS_arh4cc0juzqoc7r4h5upl0lsk/lINI, transfer-property=TRIGGERED-ON-CHANGE, to CPC ISM TCM  # Getriebewählhebel RND-Stellung (Lenkrad) / Transmission selector lever RND position (steering wheel)
          signal TxmtId_SBW_Rq_DRVU: start 18, 2 bit, little-endian, data-type=c02_TxmtId_SBW_Rq_DRVU, init-value=XDIS_7r8rqqm9bzb4ksfh4tbf956i2/lEWM, transfer-property=TRIGGERED-ON-CHANGE, to CPC ISM TCM  # Senderkennung / Transmitter identification
          signal Rsrv1_SBW_Rq_DRVU_Pr2: start 23, 1 bit, little-endian, data-type=Rsrv01, init-value=XDIS_e2uhxyvdu33zsyqfjnk549pp2/l0, transfer-property=PENDING, to CPC ISM TCM  # Reserviert für zukünftige Verwendung / Reserved for future use
          signal Rsrv2_SBW_Rq_DRVU_Pr2: start 24, 8 bit, little-endian, data-type=Rsrv08, init-value=XDIS_4flxbk4wkjkdew7cw07d9of66/l0, transfer-property=PENDING, to CPC ISM TCM  # Reserviert für zukünftige Verwendung / Reserved for future use
          signal SBW_Rq_DRVU_Pr2_71okqqkd28hyyebm190lxt3vd: little-endian, system-signal=[CRC_SBW_Rq_DRVU_Pr2, Rsrv1_SBW_Rq_DRVU_Pr2, Rsrv2_SBW_Rq_DRVU_Pr2, SQC_SBW_Rq_DRVU_Pr2, StW_Sw_Stat3_DRVU, TSL_P_Psd_StW_DRVU, TSL_RND_Posn_StW_DRVU, TxmtId_SBW_Rq_DRVU], to CPC ISM TCM  # DRVU-Anforderungen Shift by Wire (degraded) / Shift by wire request by DRVU (degraded)
      frame EVC_CfgBit_33_64_AR2: id 0x2F3, from CPC, to ASX, frame-length=8, can-addressing-mode=STANDARD  # EVC-CfgMessage[Bitfield:33h-64h]
        pdu EVC_CfgBit_33_64_AR2: length=64, unused-bit-pattern=0, cyclic-timing=repeating-time=1.0  # EVC-CfgMessage[Bitfeld:33h-64h] / EVC-CfgMessage[Bitfield:33h-64h]
          signal CRC_EVC_CfgBit_33_64_Pr2: start 0, 8 bit, little-endian, data-type=c08_CRC_woSNA, init-value=l209, to ASX(timeout 10.5 s)  # CRC-Checksumme der Signal Gruppe gemäß AUTOSAR Profil 2 / CRC-checksum of signal group according to AUTOSAR Profile 2
          signal EVC_33_EmgOpn_F_Avl: start 14, 1 bit, little-endian, data-type=DC_BOOL, init-value=XDIS_h5tcyk98kzbgrc5svasomeyt/lfalse, to ASX(timeout 10.5 s)  # Z29 SPERRUNG FONDBEDIENUNG FENSTERHEBER / Z29 LOCKOUT OPERATING REAR WINDOW LIFTER
          signal EVC_34_Curtain_F_Avl: start 15, 1 bit, little-endian, data-type=DC_BOOL, init-value=XDIS_h5tcyk98kzbgrc5svasomeyt/lfalse, to ASX(timeout 10.5 s)  # 295 VORHANG AN FONDTUERE LI U. RE / 295 CURTAIN AT REAR DOOR LEFT AND RIGHT
          signal EVC_35_EmgOpn_Inact: start 16, 1 bit, little-endian, data-type=DC_BOOL, init-value=XDIS_h5tcyk98kzbgrc5svasomeyt/lfalse, to ASX(timeout 10.5 s)  # Z86 DEAKTIVIERUNG ZV NOTOEFFUNG / Z86 DEACTIVATION EMERGENCY OPENING (POWER LOCKS)
          signal EVC_36_SpecVehPW_FL_Avl: start 17, 1 bit, little-endian, data-type=DC_BOOL, init-value=XDIS_h5tcyk98kzbgrc5svasomeyt/lfalse, to ASX(timeout 10.5 s)  # Z11 FENSTERHEBER VO LI BEI SONDERSCHUTZ / Z11 WINDOW CONTR. FRT.LEFT FOR SPECIAL PROTECTION
          signal EVC_37_SpecVehPW_FR_Avl: start 18, 1 bit, little-endian, data-type=DC_BOOL, init-value=XDIS_h5tcyk98kzbgrc5svasomeyt/lfalse, to ASX(timeout 10.5 s)  # Z12 FENSTERHEBER VO RE BEI SONDERSCHUTZ / Z12 WINDOW CONTR. FRT.RIGHT FOR SPECIAL PROTECTION
          signal EVC_38_SpecVehPW_RL_Avl: start 19, 1 bit, little-endian, data-type=DC_BOOL, init-value=XDIS_h5tcyk98kzbgrc5svasomeyt/lfalse, to ASX(timeout 10.5 s)  # Z13 FENSTERHEBER HI LI BEI SONDERSCHUTZ / Z13 WINDOW CONTR. REAR.LEFT FOR SPECIAL PROTECTION
          signal EVC_39_SpecVehPW_RR_Avl: start 20, 1 bit, little-endian, data-type=DC_BOOL, init-value=XDIS_h5tcyk98kzbgrc5svasomeyt/lfalse, to ASX(timeout 10.5 s)  # Z14 FENSTERHEBER HI RE BEI SONDERSCHUTZ / Z14 WINDOW CONTR. REAR.RIGHT FOR SPECIAL PROTECTION
          signal EVC_3A_RB_F_Avl: start 21, 1 bit, little-endian, data-type=DC_BOOL, init-value=XDIS_h5tcyk98kzbgrc5svasomeyt/lfalse, to ASX(timeout 10.5 s)  # 297 SONNENSCHUTZROLLO IN FONDTUER LI.U.RE / 297 SUN BLIND IN REAR DOORS LH AND RH
          signal EVC_3B_RB_R_Avl: start 22, 1 bit, little-endian, data-type=DC_BOOL, init-value=XDIS_h5tcyk98kzbgrc5svasomeyt/lfalse, to ASX(timeout 10.5 s)  # 540 ROLLO ELEKTRISCH FUER HECKFENSTER / 540 ELECTRIC BLIND FOR REAR WINDOW
          signal EVC_3C_SeatDrvDyn_Ft_Avl: start 23, 1 bit, little-endian, data-type=DC_BOOL, init-value=XDIS_h5tcyk98kzbgrc5svasomeyt/lfalse, to ASX(timeout 10.5 s)  # 432 FAHRDYNAMISCHER SITZ LINKS UND RECHTS / 432 DYNAMICS SEAT,FRONT LEFT AND RIGHT
          signal EVC_3D_ComfHdRst_Ft_Avl: start 24, 1 bit, little-endian, data-type=DC_BOOL, init-value=XDIS_h5tcyk98kzbgrc5svasomeyt/lfalse, to ASX(timeout 10.5 s)  # 436 KOMFORTKOPFSTUETZE FAHRER UND BEIFAHRER / 436 COMFORT HEADREST DRIVER AND FRONTPASSENGER
          signal EVC_3E_SeatMultiCont_Ft_Avl: start 25, 1 bit, little-endian, data-type=DC_BOOL, init-value=XDIS_h5tcyk98kzbgrc5svasomeyt/lfalse, to ASX(timeout 10.5 s)  # 409 MULTIKONTURSITZ VORN LINKS U.RECHTS / 409 MULTI-CONTOUR SEAT, FRONT LEFT AND RIGHT
          signal EVC_3F_SeatHt_Ft_Avl: start 26, 1 bit, little-endian, data-type=DC_BOOL, init-value=XDIS_h5tcyk98kzbgrc5svasomeyt/lfalse, to ASX(timeout 10.5 s)  # 873 SITZHEIZUNG FAHRERSITZ LINKS UND RECHTS / 873 SEAT HEATING FRONT SEATS LH AND RH
          signal EVC_40_SeatClim_Ft_Avl: start 27, 1 bit, little-endian, data-type=DC_BOOL, init-value=XDIS_h5tcyk98kzbgrc5svasomeyt/lfalse, to ASX(timeout 10.5 s)  # 401 SITZKLIMATISIERUNG VORNE / 401 CLIMATISED SEATS FRONT
          signal EVC_41_SeatMem_LHD_Avl: start 28, 1 bit, little-endian, data-type=DC_BOOL, init-value=XDIS_h5tcyk98kzbgrc5svasomeyt/lfalse, to ASX(timeout 10.5 s)  # 241 FAHRERSITZ LI. ELEKTR.VERSTELLBAR M.MEMORY / 241 FRONT SEAT LH ELECTRIC ADJUSTABLE WITH MEMORY
          signal EVC_42_SeatMem_RHD_Avl: start 29, 1 bit, little-endian, data-type=DC_BOOL, init-value=XDIS_h5tcyk98kzbgrc5svasomeyt/lfalse, to ASX(timeout 10.5 s)  # 242 FAHRERSITZ RE. ELEKTR.VERSTELLBAR M.MEMORY / 242 FRONT SEAT RH ELECTRIC ADJUSTABLE WITH MEMORY
          signal EVC_43_SeatMemPk_Avl: start 30, 1 bit, little-endian, data-type=DC_BOOL, init-value=XDIS_h5tcyk98kzbgrc5svasomeyt/lfalse, to ASX(timeout 10.5 s)  # 275 MEMORY-PAKET (FAHRERSITZ, LENKSAEULE U. SPIEGEL) / 275 MEMORY PACKAGE (DRIVER SEAT, STRG. COL., MIRROR)
          signal EVC_44_ReclSeat_Avl: start 31, 1 bit, little-endian, data-type=DC_BOOL, init-value=XDIS_h5tcyk98kzbgrc5svasomeyt/lfalse, to ASX(timeout 10.5 s)  # 453 SITZ MIT LIEGEFUNKTION / 453 RECLINING SEAT
          signal EVC_45_SeatMultiCont_R_Avl: start 32, 1 bit, little-endian, data-type=DC_BOOL, init-value=XDIS_h5tcyk98kzbgrc5svasomeyt/lfalse, to ASX(timeout 10.5 s)  # 406 MULTIKONTURSITZ IM FOND / 406 MULTI-CONTOUR REAR SEAT
          signal EVC_46_SeatBkRstAdj_R_Avl: start 33, 1 bit, little-endian, data-type=DC_BOOL, init-value=XDIS_h5tcyk98kzbgrc5svasomeyt/lfalse, to ASX(timeout 10.5 s)  # 223 FONDLEHNENVERSTELLUNG UND KOPFSTUETZEN ELEKTRISCH / 223 REAR BACK REST ADJUSTMENT AND HEAD RESTRAINTS, ELE
          signal EVC_47_SeatHt_R_Avl: start 34, 1 bit, little-endian, data-type=DC_BOOL, init-value=XDIS_h5tcyk98kzbgrc5svasomeyt/lfalse, to ASX(timeout 10.5 s)  # 872 SITZHEIZUNG FONDSITZ LI UND RE / 872 REAR SEAT BENCH HEATING LEFT UND RIGHT
          signal EVC_48_SeatClim_R_Avl: start 35, 1 bit, little-endian, data-type=DC_BOOL, init-value=XDIS_h5tcyk98kzbgrc5svasomeyt/lfalse, to ASX(timeout 10.5 s)  # 402 SITZKLIMATISIERUNG HINTEN / 402 CLIMATISED SEATS REAR
          signal EVC_49_WShWashHt_Avl: start 36, 1 bit, little-endian, data-type=DC_BOOL, init-value=XDIS_h5tcyk98kzbgrc5svasomeyt/lfalse, to ASX(timeout 10.5 s)  # 875 SCHEIBENWASCHANLAGE BEHEIZT / 875 WINDSCREEN WASHING SYSTEM, HEATED
          signal EVC_4A_TaxiPwrSup_Avl: start 37, 1 bit, little-endian, data-type=DC_BOOL, init-value=XDIS_h5tcyk98kzbgrc5svasomeyt/lfalse, to ASX(timeout 10.5 s)  # 965 TAXI / MIETWAGEN - ELEKTRISCHE VORRUESTUNG / 965 ELECTR. PROVISION FOR HIRED CARS / TAXICAB
          signal EVC_4B_TaxiRoofLmpCon_Avl: start 38, 1 bit, little-endian, data-type=DC_BOOL, init-value=XDIS_h5tcyk98kzbgrc5svasomeyt/lfalse, to ASX(timeout 10.5 s)  # 342 ANSCHLUSS FUER TAXI-DACHZEICHEN / 342 CONNECTION FOR TAXI ROOF SIGN
          signal EVC_4C_TaxiEmgAlm_Avl: start 39, 1 bit, little-endian, data-type=DC_BOOL, init-value=XDIS_h5tcyk98kzbgrc5svasomeyt/lfalse, to ASX(timeout 10.5 s)  # 934 TAXI-NOTALARM-ANLAGE / 934 TAXI EMERGENCY WARNING SYSTEM
          signal EVC_4D_RadioHdFree_Avl: start 40, 1 bit, little-endian, data-type=DC_BOOL, init-value=XDIS_h5tcyk98kzbgrc5svasomeyt/lfalse, to ASX(timeout 10.5 s)  # 938 FUNKGERAETSCHALTER UND MIKROFON / 938 RADIO UNIT SWITCH AND MICROPHONE
          signal EVC_4E_GAS_Avl: start 41, 1 bit, little-endian, data-type=DC_BOOL, init-value=XDIS_h5tcyk98kzbgrc5svasomeyt/lfalse, to ASX(timeout 10.5 s)  # Z22 GEFAEHRDETEN ALARMSYSTEM (GAS)
          signal EVC_4F_CtrlU_MultiFunc_Avl: start 42, 1 bit, little-endian, data-type=DC_BOOL, init-value=XDIS_h5tcyk98kzbgrc5svasomeyt/lfalse, to ASX(timeout 10.5 s)  # Z90 MULTIFUNKTIONALES STEUERGERAET F. SONDERFUNKTIONEN / Z90 CONTROL CODE FOR MULTIFUNCTIONEL CONTROL UNIT
          signal EVC_50_TaxInMirr_Avl: start 43, 1 bit, little-endian, data-type=DC_BOOL, init-value=XDIS_h5tcyk98kzbgrc5svasomeyt/lfalse, to ASX(timeout 10.5 s)  # 337 TAXAMETER IM RUECKSPIEGEL INTEGRIERT / 337 TAXIMETER INTEGRATED IN REAR VIEW MIRROR
          signal EVC_51_DistRecInMirr_Avl: start 44, 1 bit, little-endian, data-type=DC_BOOL, init-value=XDIS_h5tcyk98kzbgrc5svasomeyt/lfalse, to ASX(timeout 10.5 s)  # 338 WEGSTRECKENZAEHLER IM RUECKSPIEGEL INTEGRIERT / 338 DISTANCE RECORDER INTEGRATED IN INTERIOR MIRROR
          signal EVC_52_PreInstRad_Avl: start 45, 1 bit, little-endian, data-type=DC_BOOL, init-value=XDIS_h5tcyk98kzbgrc5svasomeyt/lfalse, to ASX(timeout 10.5 s)  # 941 VORRUESTUNG FUER "INTEGRATION FUNK" / 941 PREINSTALLATION FOR "RADIO TRANSM. INTEG."
          signal EVC_53_VehHandi_Avl: start 46, 1 bit, little-endian, data-type=DC_BOOL, init-value=XDIS_h5tcyk98kzbgrc5svasomeyt/lfalse, to ASX(timeout 10.5 s)  # Z97 ELEKTRONISCHE KUNDENWUNSCH SCHNITTSTELLE / Z97 ELECTRONIC CUSTOMER REQUEST INTERFACE
          signal EVC_54_PanelHt_Ft_Avl: start 47, 1 bit, little-endian, data-type=DC_BOOL, init-value=XDIS_h5tcyk98kzbgrc5svasomeyt/lfalse, to ASX(timeout 10.5 s)  # 906 AUFLAGEN VORNE BEHEIZT / 906 PANEL HEATING FRONT
          signal EVC_55_SeatComfHt_Ft_Avl: start 48, 1 bit, little-endian, data-type=DC_BOOL, init-value=XDIS_h5tcyk98kzbgrc5svasomeyt/lfalse, to ASX(timeout 10.5 s)  # 902 KOMFORTSITZHEIZUNG VORNE / 902 COMFORT SEAT HEATING FRONT
          signal EVC_56_SeatComfHt_R_Avl: start 49, 1 bit, little-endian, data-type=DC_BOOL, init-value=XDIS_h5tcyk98kzbgrc5svasomeyt/lfalse, to ASX(timeout 10.5 s)  # 903 KOMFORTSITZHEIZUNG HINTEN / 903 COMFORT SEAT HEATING REAR
          signal EVC_57_IntFoldHdRst_Ft_Avl: start 50, 1 bit, little-endian, data-type=DC_BOOL, init-value=XDIS_h5tcyk98kzbgrc5svasomeyt/lfalse, to ASX(timeout 10.5 s)  # 439 INTELLIGENTE / KLAPPBARE KOMFORT-KOPFSTUETZE VORN / 439 INTELLIGENT / FOLDING COMFORT HEAD REST IN FRONT
          signal EVC_58_SeatInd_R_Avl: start 51, 1 bit, little-endian, data-type=DC_BOOL, init-value=XDIS_h5tcyk98kzbgrc5svasomeyt/lfalse, to ASX(timeout 10.5 s)  # 224 FONDEINZELSITZE / 224 INDIVIDUAL REAR SEATS
          signal EVC_59_SeatChauffPos_P_Avl: start 52, 1 bit, little-endian, data-type=DC_BOOL, init-value=XDIS_h5tcyk98kzbgrc5svasomeyt/lfalse, to ASX(timeout 10.5 s)  # 452 CHAUFFEURSTELLUNG BEIFAHRERSITZ / 452 CHAUFFEUR-POSTION FRONT PASSENGER
          signal EVC_5A_SeatMContMass_Ft_Avl: start 53, 1 bit, little-endian, data-type=DC_BOOL, init-value=XDIS_h5tcyk98kzbgrc5svasomeyt/lfalse, to ASX(timeout 10.5 s)  # 399 MULTIKONTURSITZ VORN MIT MASSAGEFUNKTION / 399 MULTI-CONTOUR SEAT FRONT WITH MASSAGE FUNCTION
          signal EVC_5B_PanelHt_R_Avl: start 54, 1 bit, little-endian, data-type=DC_BOOL, init-value=XDIS_h5tcyk98kzbgrc5svasomeyt/lfalse, to ASX(timeout 10.5 s)  # 907 AUFLAGEN HINTEN BEHEIZT / 907 PANEL HEATING REAR
          signal EVC_5C_Airscarf_Ft_Avl: start 55, 1 bit, little-endian, data-type=DC_BOOL, init-value=XDIS_h5tcyk98kzbgrc5svasomeyt/lfalse, to ASX(timeout 10.5 s)  # 403 AIRSCARF-SYSTEM VORNE / 403 HEADROOM VENTILATION FRONT
          signal EVC_5D_SeatLimit_P_Avl: start 56, 1 bit, little-endian, data-type=DC_BOOL, init-value=XDIS_h5tcyk98kzbgrc5svasomeyt/lfalse, to ASX(timeout 10.5 s)  # Z99 PROGRAMMIERUNG SITZBEGRENZUNG NACH VORN, BEIFAHRER
          signal EVC_5E_TaxiRoofLmp_Avl: start 57, 1 bit, little-endian, data-type=DC_BOOL, init-value=XDIS_h5tcyk98kzbgrc5svasomeyt/lfalse, to ASX(timeout 10.5 s)  # 341 TAXI-DACHZEICHEN / 341 TAXI ROOF SIGN
          signal EVC_5F_SeatElAdj_LHD_Avl: start 58, 1 bit, little-endian, data-type=DC_BOOL, init-value=XDIS_h5tcyk98kzbgrc5svasomeyt/lfalse, to ASX(timeout 10.5 s)  # 221 FAHRERSITZ LINKS ELEKTRISCH VERSTELLBAR / 221 FRONT SEAT LH ELECTRIC ADJUSTABLE
          signal EVC_60_SeatElAdj_RHD_Avl: start 59, 1 bit, little-endian, data-type=DC_BOOL, init-value=XDIS_h5tcyk98kzbgrc5svasomeyt/lfalse, to ASX(timeout 10.5 s)  # 222 FAHRERSITZ RECHTS ELEKTRISCH VERSTELLBAR / 222 FRONT SEAT RH ELECTRIC ADJUSTABLE
          signal EVC_61_AMGPerfSusp_Avl: start 60, 1 bit, little-endian, data-type=DC_BOOL, init-value=XDIS_h5tcyk98kzbgrc5svasomeyt/lfalse, to ASX(timeout 10.5 s)  # 492 AMG-PERFORMANCE FAHRWERK / 492 AMG-PERFORMANCE SUSPENSION
          signal EVC_62_ShiftExhstSys_Avl: start 61, 1 bit, little-endian, data-type=DC_BOOL, init-value=XDIS_h5tcyk98kzbgrc5svasomeyt/lfalse, to ASX(timeout 10.5 s)  # U78 SCHALTBARE ABGASANLAGE / U78 SHIFTABLE EXHAUST SYSTEM
          signal EVC_63_ActvLDA_MPC_Avl: start 62, 1 bit, little-endian, data-type=DC_BOOL, init-value=XDIS_h5tcyk98kzbgrc5svasomeyt/lfalse, to ASX(timeout 10.5 s)  # 243 AKTIVER SPURHALTE-ASSISTENT (KAMERA) / 243 ACTIVE LANE DEPARTURE-ASSISTANT (CAMERA)
          signal EVC_64_EAS_Avl: start 63, 1 bit, little-endian, data-type=DC_BOOL, init-value=XDIS_h5tcyk98kzbgrc5svasomeyt/lfalse, to ASX(timeout 10.5 s)  # 545K AUSWEICHASSISTENT (noch Entwicklungscode)
          signal EVC_CfgBit_33_64_Stat: start 12, 2 bit, little-endian, data-type=c02_EVC_Stat, init-value=XDIS_b0sx1bf1u21ozu36byqxxhp5b/l3, to ASX(timeout 10.5 s)  # Status EVC-CfgMessage[Bitfeld:33h-64h] / Status EVC-CfgMessage[Bitfield:33h-64h]
          signal SQC_EVC_CfgBit_33_64_Pr2: start 8, 4 bit, little-endian, data-type=c04_0_15_1_SNA_na, init-value=XDIS_2gdok7is6uk227cngmpgf9wxb/l0, to ASX(timeout 10.5 s)  # Sequenzzähler / Sequence counter
          signal EVC_CfgBit_33_64_Pr2_6j1ey0vfxblk9wf2gvnbh92fe: little-endian, system-signal=[CRC_EVC_CfgBit_33_64_Pr2, EVC_33_EmgOpn_F_Avl, EVC_34_Curtain_F_Avl, EVC_35_EmgOpn_Inact, EVC_36_SpecVehPW_FL_Avl, EVC_37_SpecVehPW_FR_Avl, EVC_38_SpecVehPW_RL_Avl, EVC_39_SpecVehPW_RR_Avl, EVC_3A_RB_F_Avl, EVC_3B_RB_R_Avl, EVC_3C_SeatDrvDyn_Ft_Avl, EVC_3D_ComfHdRst_Ft_Avl, EVC_3E_SeatMultiCont_Ft_Avl, EVC_3F_SeatHt_Ft_Avl, EVC_40_SeatClim_Ft_Avl, EVC_41_SeatMem_LHD_Avl, EVC_42_SeatMem_RHD_Avl, EVC_43_SeatMemPk_Avl, EVC_44_ReclSeat_Avl, EVC_45_SeatMultiCont_R_Avl, EVC_46_SeatBkRstAdj_R_Avl, EVC_47_SeatHt_R_Avl, EVC_48_SeatClim_R_Avl, EVC_49_WShWashHt_Avl, EVC_4A_TaxiPwrSup_Avl, EVC_4B_TaxiRoofLmpCon_Avl, EVC_4C_TaxiEmgAlm_Avl, EVC_4D_RadioHdFree_Avl, EVC_4E_GAS_Avl, EVC_4F_CtrlU_MultiFunc_Avl, EVC_50_TaxInMirr_Avl, EVC_51_DistRecInMirr_Avl, EVC_52_PreInstRad_Avl, EVC_53_VehHandi_Avl, EVC_54_PanelHt_Ft_Avl, EVC_55_SeatComfHt_Ft_Avl, EVC_56_SeatComfHt_R_Avl, EVC_57_IntFoldHdRst_Ft_Avl, EVC_58_SeatInd_R_Avl, EVC_59_SeatChauffPos_P_Avl, EVC_5A_SeatMContMass_Ft_Avl, EVC_5B_PanelHt_R_Avl, EVC_5C_Airscarf_Ft_Avl, EVC_5D_SeatLimit_P_Avl, EVC_5E_TaxiRoofLmp_Avl, EVC_5F_SeatElAdj_LHD_Avl, EVC_60_SeatElAdj_RHD_Avl, EVC_61_AMGPerfSusp_Avl, EVC_62_ShiftExhstSys_Avl, EVC_63_ActvLDA_MPC_Avl, EVC_64_EAS_Avl, EVC_CfgBit_33_64_Stat, SQC_EVC_CfgBit_33_64_Pr2], transfer-property=PENDING, to ASX(timeout 10.5 s)  # EVC-CfgMessage[Bitfeld:33h-64h] (degraded) / EVC-CfgMessage[Bitfield:33h-64h] (degraded)
      frame EVC_CfgBit_65_96_AR2: id 0x2F5, from CPC, to TCM, frame-length=8, can-addressing-mode=STANDARD  # EVC-CfgMessage[Bitfield:65h-96h]
        pdu EVC_CfgBit_65_96_AR2: length=64, unused-bit-pattern=0, cyclic-timing=repeating-time=1.0  # EVC-CfgMessage[Bitfeld:65h-96h] / EVC-CfgMessage[Bitfield:65h-96h]
          signal CRC_EVC_CfgBit_65_96_Pr2: start 0, 8 bit, little-endian, data-type=c08_CRC_woSNA, init-value=l234, to TCM  # CRC-Checksumme der Signal Gruppe gemäß AUTOSAR Profil 2 / CRC-checksum of signal group according to AUTOSAR Profile 2
          signal EVC_65_CruiseCtrl_Avl: start 14, 1 bit, little-endian, data-type=DC_BOOL, init-value=XDIS_h5tcyk98kzbgrc5svasomeyt/lfalse, to TCM  # 440 TEMPOMAT / 440 CRUISE CONTROL
          signal EVC_66_OffRoadPk_Avl: start 15, 1 bit, little-endian, data-type=DC_BOOL, init-value=XDIS_h5tcyk98kzbgrc5svasomeyt/lfalse, to TCM  # 430 OFFROAD-PAKET / 430 OFFROAD-PACKAGE
          signal EVC_67_CMS_Avl: start 16, 1 bit, little-endian, data-type=DC_BOOL, init-value=XDIS_h5tcyk98kzbgrc5svasomeyt/lfalse, to TCM  # 300 KOLLISIONSMINDERUNG -BREMSEINGRIFF/WARNUNG (CMS) / 300 COLLISION MITIGATION SYSTEM
          signal EVC_68_CMS_R_Avl: start 17, 1 bit, little-endian, data-type=DC_BOOL, init-value=XDIS_h5tcyk98kzbgrc5svasomeyt/lfalse, to TCM  # 253 HECKKOLLISIONSWARN-UND SCHUTZSYSTEM / 253 REAR COLLISION MITIGATION SYSTEM
          signal EVC_69_BrkEngg_PP_Avl: start 18, 1 bit, little-endian, data-type=DC_BOOL, init-value=XDIS_h5tcyk98kzbgrc5svasomeyt/lfalse, to TCM  # 271 AUTONOMER BREMSEINGRIFF/WARNG. Z FUSSGAENGERSCHUTZ / 271 AUTONOMIC BRAKE-ENGAGEMENT F.PEDESTRIAN PROTECTION
          signal EVC_6A_BasExtd_Avl: start 19, 1 bit, little-endian, data-type=DC_BOOL, init-value=XDIS_h5tcyk98kzbgrc5svasomeyt/lfalse, to TCM  # 268 BREMSASSISTENT ERWEITERT (BAS+) / 268 BRAKE-ASSISTANCE EXTENDED
          signal EVC_6B_MirrFld_Avl: start 20, 1 bit, little-endian, data-type=DC_BOOL, init-value=XDIS_h5tcyk98kzbgrc5svasomeyt/lfalse, to TCM  # 500 AUSSENSPIEGEL LI. U. RE. ABKLAPPBAR / 500 OUTSIDE REAR VIEW MIRROR LH AND RH FOLDING
          signal EVC_6C_BSM_Avl: start 21, 1 bit, little-endian, data-type=DC_BOOL, init-value=XDIS_h5tcyk98kzbgrc5svasomeyt/lfalse, to TCM  # 234 TOTWINKEL-ASSISTENT / 234 BLIND SPOT-ASSISTANT
          signal EVC_6D_ActvBSM_Avl: start 22, 1 bit, little-endian, data-type=DC_BOOL, init-value=XDIS_h5tcyk98kzbgrc5svasomeyt/lfalse, to TCM  # 237 AKTIVER TOTWINKEL-ASSISTENT / 237 ACTIVE BLIND SPOT ASSISTANT
          signal EVC_6E_TurnAss_Avl: start 23, 1 bit, little-endian, data-type=DC_BOOL, init-value=XDIS_h5tcyk98kzbgrc5svasomeyt/lfalse, to TCM  # 559K ABBIEGEASSISTENT (noch Entwicklungscode)
          signal EVC_6F_ADTR_Avl: start 24, 1 bit, little-endian, data-type=DC_BOOL, init-value=XDIS_h5tcyk98kzbgrc5svasomeyt/lfalse, to TCM  # 233 ABSTANDSREGELTEMPOMAT PLUS (DISTRONIC PLUS) / 233 ADVANCED DISTRONIC
          signal EVC_70_DTR_Pro_Avl: start 25, 1 bit, little-endian, data-type=DC_BOOL, init-value=XDIS_h5tcyk98kzbgrc5svasomeyt/lfalse, to TCM  # 239 ABSTANDSREGELTEMPOMAT PRO "DISTRONIC PRO" / 239 DISTRONIC PRO
          signal EVC_71_ALS_Avl: start 26, 1 bit, little-endian, data-type=DC_BOOL, init-value=XDIS_h5tcyk98kzbgrc5svasomeyt/lfalse, to TCM  # 266 DISTRONIC PLUS QUERUNTERSTUETZUNG (DTR+Q) / 266 DISTRONIC PLUS CROSS-ASSISTANCE
          signal EVC_72_ActvLDA_Avl: start 27, 1 bit, little-endian, data-type=DC_BOOL, init-value=XDIS_h5tcyk98kzbgrc5svasomeyt/lfalse, to TCM  # 238 AKTIVER SPURHALTE-ASSISTENT / 238 ACTIVE LANE DEPARTURE-ASSISTANT
          signal EVC_73_FCW_Avl: start 28, 1 bit, little-endian, data-type=DC_BOOL, init-value=XDIS_h5tcyk98kzbgrc5svasomeyt/lfalse, to TCM  # 258 KOLLISIONSWARNER M. AKTIVEM BREMSEINGRIFF FCW-STOP / 258 FORWARD COLLISION WARN.(FCW) W.ACTIVE BRAKE CONTR.
          signal EVC_74_LaneRec_Avl: start 29, 1 bit, little-endian, data-type=DC_BOOL, init-value=XDIS_h5tcyk98kzbgrc5svasomeyt/lfalse, to TCM  # 476 AUTOM. FAHRSPURERKENNUNG / 476 AUTO. LANE RECOGNITION (CONDITION ASSISTENT)
          signal EVC_75_NV_Avl: start 30, 1 bit, little-endian, data-type=DC_BOOL, init-value=XDIS_h5tcyk98kzbgrc5svasomeyt/lfalse, to TCM  # 610 NACHTSICHTSYSTEM / 610 NIGHTVIEW-SYSTEM
          signal EVC_76_RoadSignDtct_Avl: start 31, 1 bit, little-endian, data-type=DC_BOOL, init-value=XDIS_h5tcyk98kzbgrc5svasomeyt/lfalse, to TCM  # 513 VERKEHRSZEICHENERKENNUNG (SLA) / 513 ROAD SIGN DETECTION (SLA)
          signal EVC_77_RVC_Avl: start 32, 1 bit, little-endian, data-type=DC_BOOL, init-value=XDIS_h5tcyk98kzbgrc5svasomeyt/lfalse, to TCM  # 218 RUECKFAHRKAMERA / 218 REVERSING CAMERA
          signal EVC_78_SurrView_Avl: start 33, 1 bit, little-endian, data-type=DC_BOOL, init-value=XDIS_h5tcyk98kzbgrc5svasomeyt/lfalse, to TCM  # 501 RUNDUMSICHTSYSTEM (SURROUND VIEW) / 501 SURROUND VIEW SYSTEM
          signal EVC_79_PTS_Avl: start 34, 1 bit, little-endian, data-type=DC_BOOL, init-value=XDIS_h5tcyk98kzbgrc5svasomeyt/lfalse, to TCM  # 220 PARKTRONIC-SYSTEM (PTS) / 220 PARKTRONIC SYSTEM (PTS)
          signal EVC_7A_APG_Avl: start 35, 1 bit, little-endian, data-type=DC_BOOL, init-value=XDIS_h5tcyk98kzbgrc5svasomeyt/lfalse, to TCM  # 230 PARKFUEHRUNG / 230 ADVANCED PARKING GUIDANCE
          signal EVC_7B_ActPKAS_Avl: start 36, 1 bit, little-endian, data-type=DC_BOOL, init-value=XDIS_h5tcyk98kzbgrc5svasomeyt/lfalse, to TCM  # 235 AKTIVER PARKASSISTENT / 235 ACTIVE PARKING ASSISTANCE
          signal EVC_7C_IHC_Avl: start 37, 1 bit, little-endian, data-type=DC_BOOL, init-value=XDIS_h5tcyk98kzbgrc5svasomeyt/lfalse, to TCM  # 608 AUTOMATISCHE FERNLICHTSCHALTUNG (IHC) / 608 INTELLIGENT HEADLIGHT CONTROL
          signal EVC_7D_IHC_Plus_Avl: start 38, 1 bit, little-endian, data-type=DC_BOOL, init-value=XDIS_h5tcyk98kzbgrc5svasomeyt/lfalse, to TCM  # 628 AUTOMATISCHE FERNLICHTSCHALTUNG PLUS (IHC+) / 628 INTELLIGENT HEADLIGHT CONTROL PLUS (IHC+)
          signal EVC_7E_BasPlusQ_Avl: start 39, 1 bit, little-endian, data-type=DC_BOOL, init-value=XDIS_h5tcyk98kzbgrc5svasomeyt/lfalse, to TCM  # 269 BREMSASSISTENT PLUS QUERVERKEHR (BAS+Q) / 269 BRAKE-ASISSTANCE PLUS CROSS-TRAFFIC
          signal EVC_7F_ECO_St_Avl: start 40, 1 bit, little-endian, data-type=DC_BOOL, init-value=XDIS_h5tcyk98kzbgrc5svasomeyt/lfalse, to TCM  # 212 ECO LENKUNG
          signal EVC_80_PSTS_Avl: start 41, 1 bit, little-endian, data-type=DC_BOOL, init-value=XDIS_h5tcyk98kzbgrc5svasomeyt/lfalse, to TCM  # 213 PARAMETER-LENKUNG / VARIO-LENKUNG / 213 PARAMETRIC-STEERING
          signal EVC_81_ABC_Avl: start 42, 1 bit, little-endian, data-type=DC_BOOL, init-value=XDIS_h5tcyk98kzbgrc5svasomeyt/lfalse, to TCM  # 487 ABC-FEDERUNG (ACTIVE BODY CONTROL) / 487 ABC-SPRING (ACTIVE BODY CONTROL)
          signal EVC_82_SteelAirSusp_Avl: start 43, 1 bit, little-endian, data-type=DC_BOOL, init-value=XDIS_h5tcyk98kzbgrc5svasomeyt/lfalse, to TCM  # 488 FAHRWERK MIT STAHL-/LUFTFEDERUNG / 488 CHASSIS WITH STEEL-/AIR SUSPENSION
          signal EVC_83_AirSemiActv_Susp_Avl: start 44, 1 bit, little-endian, data-type=DC_BOOL, init-value=XDIS_h5tcyk98kzbgrc5svasomeyt/lfalse, to TCM  # 489 AIRMATIC DC / LUFTFEDERUNG SEMIAKTIV / 489 AIRMATIC DUAL CONTROL / AIR SUSPENSION SEMI-ACTIVE
          signal EVC_84_SportSusp_Avl: start 45, 1 bit, little-endian, data-type=DC_BOOL, init-value=XDIS_h5tcyk98kzbgrc5svasomeyt/lfalse, to TCM  # 486 SPORTFAHRWERK / 486 SPORTS SUSPENSION
          signal EVC_85_SportPk_AMG_Avl: start 46, 1 bit, little-endian, data-type=DC_BOOL, init-value=XDIS_h5tcyk98kzbgrc5svasomeyt/lfalse, to TCM  # 950 SPORTPAKET AMG / 950 AMG SPORTS PACKAGE
          signal EVC_86_SportPk_Avl: start 47, 1 bit, little-endian, data-type=DC_BOOL, init-value=XDIS_h5tcyk98kzbgrc5svasomeyt/lfalse, to TCM  # 952 SPORTPAKET / 952 SPORTS PACKAGE
          signal EVC_87_SportPk_Ext_Avl: start 48, 1 bit, little-endian, data-type=DC_BOOL, init-value=XDIS_h5tcyk98kzbgrc5svasomeyt/lfalse, to TCM  # P96 SPORTPAKET EXTERIEUR / P96 SPORT PACKAGE EXTERIEUR
          signal EVC_88_DualView_Avl: start 49, 1 bit, little-endian, data-type=DC_BOOL, init-value=XDIS_h5tcyk98kzbgrc5svasomeyt/lfalse, to TCM  # 867 BEIFAHRER - ENTERTAINMENT / 867 SPLITVIEW
          signal EVC_89_Entertain_R_Avl: start 50, 1 bit, little-endian, data-type=DC_BOOL, init-value=XDIS_h5tcyk98kzbgrc5svasomeyt/lfalse, to TCM  # 864 FOND-ENTERTAINMENT (2 BILDSCHIRME) / 864 REAR SEAT-ENTERTAINMENT (2 MONITORS)
          signal EVC_8A_DigTV_Avl: start 51, 1 bit, little-endian, data-type=DC_BOOL, init-value=XDIS_h5tcyk98kzbgrc5svasomeyt/lfalse, to TCM  # 863 TV-TUNER DIGITAL/ANALOG / 863 TV-TUNER DIGITAL TO ANALOG
          signal EVC_8B_DAB_Tun_Avl: start 52, 1 bit, little-endian, data-type=DC_BOOL, init-value=XDIS_h5tcyk98kzbgrc5svasomeyt/lfalse, to TCM  # 537 DAB-TUNER
          signal EVC_8C_MTUS_Avl: start 53, 1 bit, little-endian, data-type=DC_BOOL, init-value=XDIS_h5tcyk98kzbgrc5svasomeyt/lfalse, to TCM  # 386 VORRUESTG.MOBILTELEFON M.UNIVERS.-SCHNITTST.(MTUS) / 386 MOBILE PRE.-INSTALLATION (MTUS)
          signal EVC_8D_UCI_Avl: start 54, 1 bit, little-endian, data-type=DC_BOOL, init-value=XDIS_h5tcyk98kzbgrc5svasomeyt/lfalse, to TCM  # 518 UNIVERSELLE KOMMUNIKATIONSSCHNITTSTELLE (UCI) / 518 UNIVERSAL CONSUMER INTERFACE (UCI)
          signal EVC_8E_SndSys_Avl: start 55, 1 bit, little-endian, data-type=DC_BOOL, init-value=XDIS_h5tcyk98kzbgrc5svasomeyt/lfalse, to TCM  # 810 SOUNDSYSTEM
          signal EVC_8F_WShViewWin_Avl: start 56, 1 bit, little-endian, data-type=DC_BOOL, init-value=XDIS_h5tcyk98kzbgrc5svasomeyt/lfalse, to TCM  # 599 WINDSCHUTZSCHEIBE MIT SICHTFENSTER / 599 WINDSHIELD WITH VIEWING WINDOW
          signal EVC_90_WSh_Clr_Avl: start 57, 1 bit, little-endian, data-type=DC_BOOL, init-value=XDIS_h5tcyk98kzbgrc5svasomeyt/lfalse, to TCM  # Y980 ZB WINDSCHUTZSCHEIBE KLAR / Y980 CLEAR WINDSHIELD ASSEMBLY WITH RAIN SENSOR
          signal EVC_91_WSh_Ht_Avl: start 58, 1 bit, little-endian, data-type=DC_BOOL, init-value=XDIS_h5tcyk98kzbgrc5svasomeyt/lfalse, to TCM  # Z17 WINDSCHUTZSCHEIBE HEIZBAR / Z17 HEATED WINDSHIELD
          signal EVC_92_WShBL_Prot_Avl: start 59, 1 bit, little-endian, data-type=DC_BOOL, init-value=XDIS_h5tcyk98kzbgrc5svasomeyt/lfalse, to TCM  # Z021 WINDSCH.U.HECKSCHEIBE VERSTAERKT BEI SONDERSCHUTZ / Z021 WINDSHIELD/REAR SCREEN REINFORCED ON SPEC.PROTECT.
          signal EVC_93_WSh_Ht_Lcut_Avl: start 60, 1 bit, little-endian, data-type=DC_BOOL, init-value=XDIS_h5tcyk98kzbgrc5svasomeyt/lfalse, to TCM  # Z251 WINDSCHUTZSCHEIBE HEIZBAR MIT LASERCUTFENSTER
          signal EVC_94_OptPack_Clas_Avl: start 61, 1 bit, little-endian, data-type=DC_BOOL, init-value=XDIS_h5tcyk98kzbgrc5svasomeyt/lfalse, to TCM  # 953 CLASSIC/SERIENAUSSTATTUNG / 953 EQUIPMENT PACKAGE CLASSIC
          signal EVC_95_OptPack_Avan_Avl: start 62, 1 bit, little-endian, data-type=DC_BOOL, init-value=XDIS_h5tcyk98kzbgrc5svasomeyt/lfalse, to TCM  # 954 AUSSTATTUNGSPAKET AVANTGARDE / 954 EQUIPMENT PACKAGE AVANTGARDE
          signal EVC_96_OptPack_Eleg_Avl: start 63, 1 bit, little-endian, data-type=DC_BOOL, init-value=XDIS_h5tcyk98kzbgrc5svasomeyt/lfalse, to TCM  # 955 AUSSTATTUNGSPAKET ELEGANCE / 955 EQUIPMENT PACKAGE ELEGANCE
          signal EVC_CfgBit_65_96_Stat: start 12, 2 bit, little-endian, data-type=c02_EVC_Stat, init-value=XDIS_b0sx1bf1u21ozu36byqxxhp5b/l3, to TCM  # Status EVC-CfgMessage[Bitfeld:65h-96h] / Status EVC-CfgMessage[Bitfield:65h-96h]
          signal SQC_EVC_CfgBit_65_96_Pr2: start 8, 4 bit, little-endian, data-type=c04_0_15_1_SNA_na, init-value=XDIS_2gdok7is6uk227cngmpgf9wxb/l0, to TCM  # Sequenzzähler / Sequence counter
          signal EVC_CfgBit_65_96_Pr2_av2hye5lktbglj5y8o60nsl17: little-endian, system-signal=[CRC_EVC_CfgBit_65_96_Pr2, EVC_65_CruiseCtrl_Avl, EVC_66_OffRoadPk_Avl, EVC_67_CMS_Avl, EVC_68_CMS_R_Avl, EVC_69_BrkEngg_PP_Avl, EVC_6A_BasExtd_Avl, EVC_6B_MirrFld_Avl, EVC_6C_BSM_Avl, EVC_6D_ActvBSM_Avl, EVC_6E_TurnAss_Avl, EVC_6F_ADTR_Avl, EVC_70_DTR_Pro_Avl, EVC_71_ALS_Avl, EVC_72_ActvLDA_Avl, EVC_73_FCW_Avl, EVC_74_LaneRec_Avl, EVC_75_NV_Avl, EVC_76_RoadSignDtct_Avl, EVC_77_RVC_Avl, EVC_78_SurrView_Avl, EVC_79_PTS_Avl, EVC_7A_APG_Avl, EVC_7B_ActPKAS_Avl, EVC_7C_IHC_Avl, EVC_7D_IHC_Plus_Avl, EVC_7E_BasPlusQ_Avl, EVC_7F_ECO_St_Avl, EVC_80_PSTS_Avl, EVC_81_ABC_Avl, EVC_82_SteelAirSusp_Avl, EVC_83_AirSemiActv_Susp_Avl, EVC_84_SportSusp_Avl, EVC_85_SportPk_AMG_Avl, EVC_86_SportPk_Avl, EVC_87_SportPk_Ext_Avl, EVC_88_DualView_Avl, EVC_89_Entertain_R_Avl, EVC_8A_DigTV_Avl, EVC_8B_DAB_Tun_Avl, EVC_8C_MTUS_Avl, EVC_8D_UCI_Avl, EVC_8E_SndSys_Avl, EVC_8F_WShViewWin_Avl, EVC_90_WSh_Clr_Avl, EVC_91_WSh_Ht_Avl, EVC_92_WShBL_Prot_Avl, EVC_93_WSh_Ht_Lcut_Avl, EVC_94_OptPack_Clas_Avl, EVC_95_OptPack_Avan_Avl, EVC_96_OptPack_Eleg_Avl, EVC_CfgBit_65_96_Stat, SQC_EVC_CfgBit_65_96_Pr2], transfer-property=PENDING, to TCM  # EVC-CfgMessage[Bitfeld:65h-96h] (degraded) / EVC-CfgMessage[Bitfield:65h-96h] (degraded)
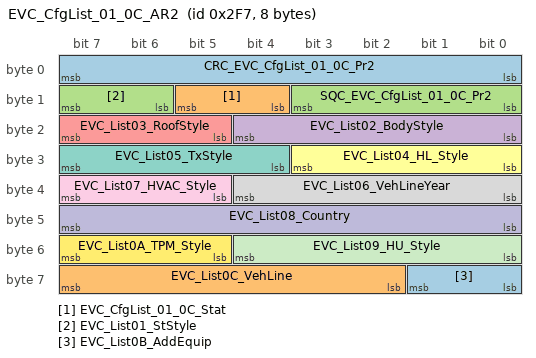
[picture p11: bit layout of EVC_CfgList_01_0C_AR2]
      frame EVC_CfgList_01_0C_AR2: id 0x2F7, from CPC, to ASX ECM TCM, frame-length=8, can-addressing-mode=STANDARD  # EVC-CfgMessage[Lists:01h-0Ch]
        pdu EVC_CfgList_01_0C_AR2: length=64, unused-bit-pattern=0, cyclic-timing=repeating-time=1.0  # EVC-CfgMessage[Listen:01h-0Ch] / EVC-CfgMessage[Lists:01h-0Ch]
          signal CRC_EVC_CfgList_01_0C_Pr2: start 0, 8 bit, little-endian, data-type=c08_CRC_woSNA, init-value=l33, to ASX ECM TCM  # CRC-Checksumme der Signal Gruppe gemäß AUTOSAR Profil 2 / CRC-checksum of signal group according to AUTOSAR Profile 2
          signal EVC_CfgList_01_0C_Stat: start 12, 2 bit, little-endian, data-type=c02_EVC_Stat, init-value=XDIS_b0sx1bf1u21ozu36byqxxhp5b/l3, to ASX ECM TCM  # Status EVC-CfgMessage[Listen:01h-0Ch] / Status EVC-CfgMessage[Lists:01h-0Ch]
          signal EVC_List01_StStyle: start 14, 2 bit, little-endian, data-type=c02_StStyle, init-value=XDIS_2mu1yfynzx7eq98ugq1zsz33c/l3, to ASX ECM TCM  # Lenkungsvariante / Steering variant
          signal EVC_List02_BodyStyle: start 16, 5 bit, little-endian, data-type=c05_EVC_BodyStyle, init-value=XDIS_dil9l0u36vmrk4slsnp17mahd/lOTHER, to ASX ECM TCM  # Karosserievariante / Vehicle body style
          signal EVC_List03_RoofStyle: start 21, 3 bit, little-endian, data-type=c03_EVC_RoofStyle, init-value=XDIS_d9yd6xyexwqqqwkngpic257wx/lOTHER, to ASX ECM TCM  # Dachvariante / Roof Style
          signal EVC_List04_HL_Style: start 24, 4 bit, little-endian, data-type=c04_EVC_HL_Style, init-value=XDIS_577jt4tp9alp9uu1sij0270o4/lOTHER, to ASX ECM TCM  # Scheinwerferart / Headlamp Style
          signal EVC_List05_TxStyle: start 28, 4 bit, little-endian, data-type=c04_EVC_TxStyle, init-value=XDIS_54ybgp27x5vskb2dv6vwhabu9/lOTHER, to ASX ECM TCM  # Getriebeart / Transmission Style
          signal EVC_List06_VehLineYear: start 32, 5 bit, little-endian, data-type=c05_EVC_VehLineYear, init-value=XDIS_ajew9a0uit45wx0xtvu446cfv/l31, to ASX ECM TCM  # Änderungsjahr: Jahr / Vehicle line version: year
          signal EVC_List07_HVAC_Style: start 37, 3 bit, little-endian, data-type=c03_EVC_HVAC_Style, init-value=XDIS_7j9pky1up2b8g1la265uef3we/lOTHER, to ASX ECM TCM  # Variante Klimaanlage / Heating Ventilation Air Conditioning Style
          signal EVC_List08_Country: start 40, 8 bit, little-endian, data-type=c08_EVC_Country, init-value=XDIS_diolmgay34ck0c0molf9pznyp/lOTHER, to ASX ECM TCM  # Land / Country
          signal EVC_List09_HU_Style: start 48, 5 bit, little-endian, data-type=c05_EVC_HU_Style, init-value=XDIS_b444aizu620gbf4q6u6nf1acq/lOTHER, to ASX ECM TCM  # Variante Headunit / Headunit Style
          signal EVC_List0A_TPM_Style: start 53, 3 bit, little-endian, data-type=c03_EVC_TPM_Style, init-value=XDIS_dr87ylzskw1u9hclvhhcvy8qz/lOTHER, to ASX ECM TCM  # Variante Reifendrucküberwachung / Tyre Pressure Monitoring Style
          signal EVC_List0B_AddEquip: start 56, 2 bit, little-endian, data-type=c02_EVC_AddEquip, init-value=XDIS_33qjvgjtp408uvl55msel1lo3/lOTHER, to ASX ECM TCM  # weitere Ausstattungsliste (noch nicht genauer definiert) / Additional Equipment List (not specialized yet)
          signal EVC_List0C_VehLine: start 58, 6 bit, little-endian, data-type=c06_EVC_VehLine, init-value=XDIS_71s5eiv53ol0041jb1i5btwvv/lOTHER, to ASX ECM TCM  # Baureihe / Vehicle line
          signal SQC_EVC_CfgList_01_0C_Pr2: start 8, 4 bit, little-endian, data-type=c04_0_15_1_SNA_na, init-value=XDIS_2gdok7is6uk227cngmpgf9wxb/l0, to ASX ECM TCM  # Sequenzzähler / Sequence counter
          signal EVC_CfgList_01_0C_Pr2_3qvfhaj56jpqdd0izhj6fs0z3: little-endian, system-signal=[CRC_EVC_CfgList_01_0C_Pr2, EVC_CfgList_01_0C_Stat, EVC_List01_StStyle, EVC_List02_BodyStyle, EVC_List03_RoofStyle, EVC_List04_HL_Style, EVC_List05_TxStyle, EVC_List06_VehLineYear, EVC_List07_HVAC_Style, EVC_List08_Country, EVC_List09_HU_Style, EVC_List0A_TPM_Style, EVC_List0B_AddEquip, EVC_List0C_VehLine, SQC_EVC_CfgList_01_0C_Pr2], transfer-property=PENDING, to ASX ECM TCM  # EVC-CfgMessage[Listen:01h-0Ch] (degraded) / EVC-CfgMessage[Lists:01h-0Ch] (degraded)
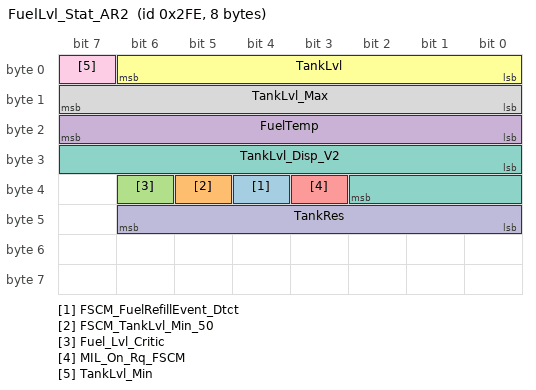
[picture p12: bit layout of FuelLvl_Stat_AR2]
      frame FuelLvl_Stat_AR2: id 0x2FE, from FSCM, to CPC ECM, frame-length=8, can-addressing-mode=STANDARD  # Fuel_Stat
        pdu FuelLvl_Stat_AR2: length=64, unused-bit-pattern=0, cyclic-timing={repeating-time=1.0, starting-time=0.09}  # Kraftstoff Status / Fuel Status
          signal FSCM_FuelRefillEvent_Dtct: start 36, 1 bit, little-endian, data-type=DC_BOOL, init-value=XDIS_h5tcyk98kzbgrc5svasomeyt/lfalse, transfer-property=PENDING, to CPC ECM  # Nachtank-Ereignis erkannt / Refill of fuel tank is detected
          signal FSCM_TankLvl_Min_50: start 37, 1 bit, little-endian, data-type=DC_BOOL, init-value=XDIS_h5tcyk98kzbgrc5svasomeyt/lfalse, transfer-property=PENDING, to CPC  # Tankfüllstand bei 50% des Minimums / Fuel tank level at 50% of minimum
          signal Fuel_Lvl_Critic: start 38, 1 bit, little-endian, data-type=DC_BOOL, init-value=XDIS_h5tcyk98kzbgrc5svasomeyt/lfalse, transfer-property=PENDING, to CPC ECM  # Kritischer Füllstand im Tank / Critical fuel level
          signal FuelTemp: start 16, 8 bit, little-endian, data-type=c08_degC_m50_204_1, init-value=XDIS_1qgh8ijswcrhuty1cyrfufsk3/l255, transfer-property=PENDING, to CPC ECM  # Aktueller Kraftstofftemperatur / Actual Fuel temperature
          signal MIL_On_Rq_FSCM: start 35, 1 bit, little-endian, data-type=DC_BOOL, init-value=XDIS_h5tcyk98kzbgrc5svasomeyt/lfalse, transfer-property=PENDING, to CPC ECM  # Diagnose Kontrolllampe (OBD II) / Malfunction indicator lamp on request (OBD II)
          signal TankLvl: start 0, 7 bit, little-endian, data-type=c07_perc_0_100_1, init-value=XDIS_3bh4hz6f9npcj7z85ik5esdib/l127, transfer-property=PENDING, to CPC ECM  # Tankfüllstand / Tank level
          signal TankLvl_Disp_V2: start 24, 11 bit, little-endian, data-type=c11_l_0_204k6_0k1, init-value=XDIS_ahldgnuii6jwiml6x5zur6yaa/l2047, transfer-property=PENDING, to CPC ECM  # Angezeigter Tankfüllstand / Displayed tank level
          signal TankLvl_Max: start 8, 8 bit, little-endian, data-type=c08_l_0_254_1, init-value=XDIS_cd4bn1so8z4o8wforq3f7ykbn/l255, transfer-property=PENDING, to CPC ECM  # Maximaler Tankfüllstand / Maximum tank level
          signal TankLvl_Min: start 7, 1 bit, little-endian, data-type=DC_BOOL, init-value=XDIS_h5tcyk98kzbgrc5svasomeyt/lfalse, transfer-property=PENDING, to CPC ECM  # Tankfüllstandsminimum / Tank level minimum
          signal TankRes: start 40, 7 bit, little-endian, data-type=c07_per_0to100_1_SNA, init-value=XDIS_6w7kc8amiekknqhh61qaaoij9/l127, transfer-property=PENDING, to CPC  # Angezeigte Tankreserve / Displayed TankReserve
      frame IC_BasicInfo_AR2: id 0x309, from CPC, to ASX ECM FFAP_STAR_2 FSCM ISM TCM, frame-length=8, can-addressing-mode=STANDARD  # IC Odometer, Geschwindigkeit, Temperatur, Zeitzähler / IC Odometer, Speed, Temperature, Timecounter
        pdu IC_BasicInfo_AR2: length=64, unused-bit-pattern=0, cyclic-timing=repeating-time=1.0, event-controlled-timing=number-of-repeats=0, minimum-delay=0.1  # IC Odometer, Geschwindigkeit, Temperatur, Zeitzähler / IC Odometer, Speed, Temperature, Timecounter
          signal AirTemp_Outsd_Disp: start 24, 8 bit, little-endian, data-type=c08_degC_m40_85_0k5, init-value=XDIS_blybmtx9riv2qoxuohj41e22d/l255, transfer-property=PENDING, to ECM FSCM TCM  # Angezeigte Außenlufttemperatur / Displayed outside air temperature
          signal IC_TP_Alive: start 63, 1 bit, little-endian, data-type=DC_BOOL, init-value=XDIS_h5tcyk98kzbgrc5svasomeyt/lfalse, transfer-property=TRIGGERED-ON-CHANGE  # IC TP alive
          signal Odo: start 0, 24 bit, little-endian, data-type=c24_km_0_999999k9_0k1, init-value=l16777215, transfer-property=PENDING, to ASX ECM FFAP_STAR_2 FSCM ISM TCM  # Kilometerstand (für alle, FFFFFEh: Signal ungültig) / Odometer (for everyone, FFFFFEh: Signal invalid)
          signal UnitVehSpd: start 60, 1 bit, little-endian, data-type=c01_UnitVehSpd_IC, init-value=lKMH_KM, transfer-property=PENDING  # Geschwindigkeitseinheit / Vehicle speed unit
          signal VehSpd_Disp: start 48, 12 bit, little-endian, data-type=c12_km_p_h_0_409k4_0k1, init-value=XDIS_1fl5m527mfqxrtai409n5nt6p/l4095, transfer-property=TRIGGERED-ON-CHANGE, to ASX FSCM TCM  # Angezeigte Geschwindigkeit (ohne Zeigerdämpfung) / Displayed vehicle speed (without attenuation)
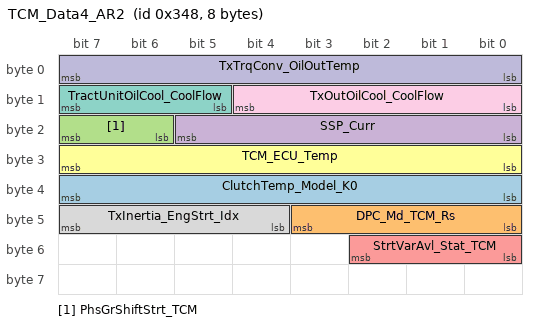
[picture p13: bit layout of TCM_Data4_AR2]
      frame TCM_Data4_AR2: id 0x348, from TCM, to CPC, frame-length=8, can-addressing-mode=STANDARD  # TCM Data4 AR2
        pdu TCM_Data4_AR2: length=64, unused-bit-pattern=0, cyclic-timing={repeating-time=0.2, starting-time=0.19}, event-controlled-timing=number-of-repeats=0, minimum-delay=0.01  # TCM Data4 AR2
          signal ClutchTemp_Model_K0: start 32, 8 bit, little-endian, data-type=c08_degC_m50_350_2, init-value=XDIS_2t4xaut0t5vtattx6puvpt4xi/l255, transfer-property=PENDING, to CPC  # Modellierte K0-Lamellentemperatur / Clutch temperature model for K0
          signal DPC_Md_TCM_Rs: start 40, 4 bit, little-endian, data-type=c04_DPC_Md_PT_Rx_HU, init-value=XDIS_qkvu5pqsnjj53jpo6exsklnq/lINIT, transfer-property=PENDING, to CPC  # Fahrprogrammwahl: Antwort Getriebe / Driving program control: transmission mode response
          signal PhsGrShiftStrt_TCM: start 22, 2 bit, little-endian, data-type=c02_PhsGrShiftStrt, init-value=lPH_0, transfer-property=TRIGGERED-ON-CHANGE, to CPC  # Aktive TCM-Phase für Schaltgestützten Motorstart / Active TCM phase for shift supported engine start
          signal SSP_Curr: start 16, 6 bit, little-endian, data-type=c6_a_0_62_1, init-value=XDIS_ass9zq7bb2aby3lv1fwo915q6/l0, transfer-property=PENDING, to CPC  # Strom der Zusatzölpumpe / SSP Current
          signal StrtVarAvl_Stat_TCM: start 48, 3 bit, little-endian, data-type=c03_StrtVarAvl_Stat_TCM, init-value=lSTRT_DWNSHIFT_AVL, transfer-property=TRIGGERED-ON-CHANGE, to CPC  # Verfügbare Motorstart Varianten / Available engine start variants
          signal TCM_ECU_Temp: start 24, 8 bit, little-endian, data-type=c08_degC_m50_204_1, init-value=XDIS_1qgh8ijswcrhuty1cyrfufsk3/l255, transfer-property=PENDING, to CPC  # Steuergerätetemperatur TCM / ECU Temperature of TCM
          signal TractUnitOilCool_CoolFlow: start 13, 3 bit, little-endian, data-type=c03_l_per_min_0_3_0k5, init-value=XDIS_4g73cqjaawfv5dydbaqapujlx/l0, transfer-property=PENDING, to CPC  # Kühlmittel Durchflussmenge für Ölkühler am Triebkopf (Traction Unit) / Coolant flow of oil cooler at traction unit
          signal TxInertia_EngStrt_Idx: start 44, 4 bit, little-endian, data-type=c04_TxInertia_EngStrt_Idx, init-value=XDIS_5g7hv7745ltohm7o2m7fq7geg/lIDLE, transfer-property=TRIGGERED-ON-CHANGE, to CPC  # Aktive Getriebeträgheit während des Motorstartes / Active transmission inertia during engine start
          signal TxOutOilCool_CoolFlow: start 8, 5 bit, little-endian, data-type=c05_l_per_min_0_15_0k5, init-value=XDIS_6orcl756eoqwhq5aunx3kjhn8/l0, transfer-property=PENDING, to CPC  # Kühlmittel Durchflussmenge für Ölkühler am Getriebeausgang / Coolant flow of oil cooler at transmission output
          signal TxTrqConv_OilOutTemp: start 0, 8 bit, little-endian, data-type=c08_degC_m40_214_1, init-value=XDIS_2w6cbkwiimui1ikli98aqr08p/l0, transfer-property=PENDING, to CPC  # Öl Austrittstemperatur des Getriebewandlers / Oil output temperature of transmission torque converter
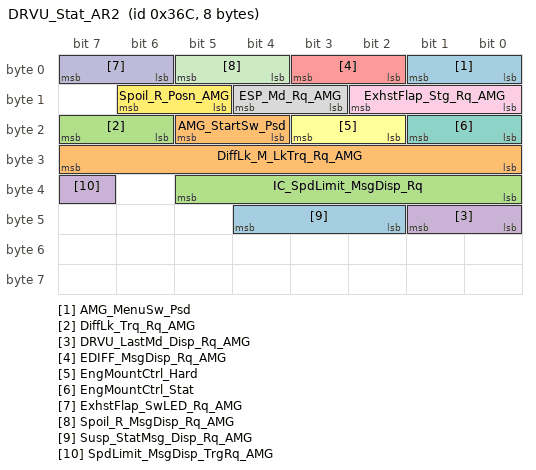
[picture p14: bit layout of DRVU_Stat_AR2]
      frame DRVU_Stat_AR2: id 0x36C, from DRVU, to ASX ECM, frame-length=8, can-addressing-mode=STANDARD  # AMG aerodynamics status / Status of AMG aeordynamics
        pdu DRVU_Stat_AR2: length=64, unused-bit-pattern=0, cyclic-timing={repeating-time=0.1, starting-time=0.05}, event-controlled-timing=number-of-repeats=0, minimum-delay=0.02  # DRIVEUNIT Status / DRIVEUNIT State
          signal AMG_MenuSw_Psd: start 0, 2 bit, little-endian, data-type=c02_AMG_MenuSw_Psd, init-value=XDIS_4kp2g078a5fpwjt4cdz62uku2/l3, transfer-property=TRIGGERED-ON-CHANGE  # Taster AMG-Menü betätigt / AMG menue switch pressed
          signal DiffLk_M_LkTrq_Rq_AMG: start 24, 8 bit, little-endian, data-type=c08_Nm_0_1270_5, init-value=XDIS_dfmsesljm1l0qmgkteetm3xmh/l255, transfer-property=TRIGGERED-ON-CHANGE  # Momentenanforderung manuelles Programm AMG / Locking torque request manual mode AMG
          signal DiffLk_Trq_Rq_AMG: start 22, 2 bit, little-endian, data-type=c02_DiffLk_Trq_Rq_AMG, init-value=XDIS_ae5xrnuvh33g0yb25el7eep4k/lIDLE, transfer-property=TRIGGERED-ON-CHANGE  # Momentenanforderung Automatik-Programm AMG / Torque request automatic mode AMG
          signal DRVU_LastMd_Disp_Rq_AMG: start 40, 2 bit, little-endian, data-type=c02_ESP_LastMd_Disp_Rq, init-value=XDIS_5ilxwnkz53oa90kwdz13h1cg1/lNO_RQ, transfer-property=TRIGGERED-ON-CHANGE  # ESP-Mode Anzeigeanforderung letzter Modus Agility Select (nuer AMG) / ESP mode display request with last mode agility select (AMG only)
          signal EDIFF_MsgDisp_Rq_AMG: start 2, 2 bit, little-endian, data-type=c02_EDIFF_MsgDisp_Rq_AMG, init-value=XDIS_9r0gtu7ve79mlahhb23ex7m2g/l3, transfer-property=TRIGGERED-ON-CHANGE  # Elektrisches Differential - Displaymeldungen / Electrical differential message display request
          signal EngMountCtrl_Hard: start 18, 2 bit, little-endian, data-type=c02_Soft_Mid_Hard_SNA, init-value=lSOFT, transfer-property=TRIGGERED-ON-CHANGE, to ECM  # Haerte der Motorlager-Steuerung / Engine mountings control hardness
          signal EngMountCtrl_Stat: start 16, 2 bit, little-endian, data-type=c02_Norm_Flt_Ndef_SNA, init-value=XDIS_9cqn87tsf02uy044vd3qzo44h/lNORMAL, transfer-property=TRIGGERED-ON-CHANGE, to ECM  # Status der Motorlager Steuerung / Engine mountings control state
          signal ESP_Md_Rq_AMG: start 11, 2 bit, little-endian, data-type=c02_ESP_Md_Rq_AMG, init-value=lNO, transfer-property=TRIGGERED-ON-CHANGE  # Anforderung ESP-Modus AMG / ESP mode request AMG
          signal ExhstFlap_Stg_Rq_AMG: start 8, 3 bit, little-endian, data-type=c03_ExhstFlap_Stg, init-value=XDIS_dj236vlj8xzzdctuelqz8u9rt/lIDLE, transfer-property=TRIGGERED-ON-CHANGE, to ASX(timeout 1.05 s) ECM(timeout 1.05 s)  # Anforderung einer Abgasklappenstellung (nur AMG) / Request for exhaust flap stage (AMG only)
          signal ExhstFlap_SwLED_Rq_AMG: start 6, 2 bit, little-endian, data-type=c02_ExhstFlap_SwLED_Rq, init-value=XDIS_2hjdem9i1croyuwfcpuw9nxsq/lLED_OFF, transfer-property=TRIGGERED-ON-CHANGE  # Anforderung LED Taster Abgasklappe (nur AMG) / Exhaust flap switch LED request (AMG only)
          signal Spoil_R_MsgDisp_Rq_AMG: start 4, 2 bit, little-endian, data-type=c02_Spoil_R_MsgDisp_Rq_AMG, init-value=XDIS_c52lksz5u322bd4oae8xkj7fh/l3, transfer-property=TRIGGERED-ON-CHANGE  # Heckspoiler-Displaymeldungen / Rear spoiler message display request
          signal Spoil_R_Posn_AMG: start 13, 2 bit, little-endian, data-type=c02_Spoil_R_Posn_AMG, init-value=XDIS_v6vz84cs1bbwfzvdkzdfu0kg/l3, transfer-property=TRIGGERED-ON-CHANGE  # Position Heckspoiler / Rear spoiler position
          signal Susp_StatMsg_Disp_Rq_AMG: start 42, 3 bit, little-endian, data-type=c03_Susp_Stat_AMG, init-value=lNONE, transfer-property=TRIGGERED-ON-CHANGE  # Anzeigeanforderung Statusmeldung Federung AMG / Suspension state message display request - AMG
          signal AMG_StartSw_Psd: start 20, 2 bit, little-endian, data-type=c02_NPsd_Psd, init-value=XDIS_daq9spsdlmsva4t7y2tw69dn3/l3, transfer-property=PENDING  # AMG-Starttaster betätigt / AMG start switch pressed
          signal IC_SpdLimit_MsgDisp_Rq: start 32, 6 bit, little-endian, data-type=c06_0_310_5, init-value=XDIS_7iqmvm5ur5x2cozuic1m6ch0f/l63  # Anzeige Meldung des Fahrzeuggeschwindigkeitsbegrenzung / Speed limitation display request for IC
          signal SpdLimit_MsgDisp_TrgRq_AMG: start 39, 1 bit, little-endian, data-type=DC_BOOL, init-value=XDIS_h5tcyk98kzbgrc5svasomeyt/lfalse  # Anforderung an IC: Auslösen der Geschwindigkeitsbegrenzungsanzeige / Speed limitation display trigger request for IC
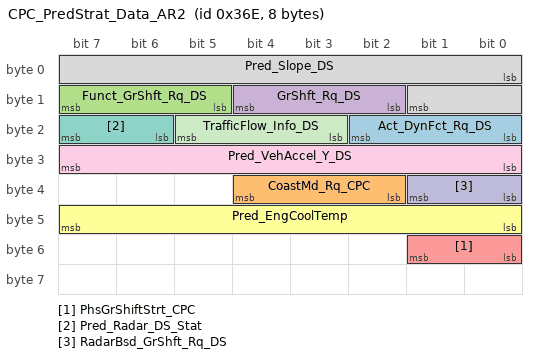
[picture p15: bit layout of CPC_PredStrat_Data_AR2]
      frame CPC_PredStrat_Data_AR2: id 0x36E, from CPC, to ISM TCM, frame-length=8, can-addressing-mode=STANDARD
        pdu CPC_PredStrat_Data_AR2: length=64, unused-bit-pattern=0, cyclic-timing={repeating-time=0.2, starting-time=0.19}, event-controlled-timing=number-of-repeats=0, minimum-delay=0.02
          signal Act_DynFct_Rq_DS: start 16, 3 bit, little-endian, data-type=c03_Act_DynFct_Rq_DS, init-value=XDIS_dnf6hhyeye1ebcwx2imhebqum/l7, transfer-property=PENDING, to ISM TCM  # Aktuelle geoditären Informationen für dynamische Funktionen der Schaltstrategie / Actual geodetical information for the dynamic functions of the Driving Strategy
          signal CoastMd_Rq_CPC: start 34, 3 bit, little-endian, data-type=c03_CoastMd_Rq, init-value=XDIS_d70t0nscru75hebntakcwyznu/l7, transfer-property=TRIGGERED-ON-CHANGE, to ISM TCM  # Status Verkehrsvorhersage für Segelmodus / State of traffic prediction as requirement for coasting mode
          signal Funct_GrShft_Rq_DS: start 13, 3 bit, little-endian, data-type=c03_Funct_GrShft_Rq_DS, init-value=XDIS_8qlmnw9tobi7dd8p2sllxpb9v/l7, transfer-property=PENDING, to ISM TCM  # Verantwortliche Funktion für Schaltanforderung und -Verbot / Responsible Function/Use Case for Request and prohibition of gear shift
          signal GrShft_Rq_DS: start 10, 3 bit, little-endian, data-type=c03_GrShft_Rq_DS, init-value=XDIS_5ovt5l93gwvy4it3m7ozigx3d/l7, transfer-property=TRIGGERED-ON-CHANGE, to ISM TCM  # Schalt-Anforderung und -Verbot durch vorrausschauende Schaltstrategie / Request and prohibition of gear shift predictive Driving Strategy
          signal PhsGrShiftStrt_CPC: start 48, 2 bit, little-endian, data-type=c02_PhsGrShiftStrt, init-value=lPH_0, transfer-property=TRIGGERED-ON-CHANGE, to TCM  # Aktive CPC-Phase für Schaltgestützten Motorstart / Active CPC phase for shift supported engine start
          signal Pred_EngCoolTemp: start 40, 8 bit, little-endian, data-type=c08_degC_m40_150_SNA_1, init-value=XDIS_e7m4guz2uvj6p2oxh8v2fcmko/l255, transfer-property=PENDING, to TCM  # Vorhergesagte Motorkühlmitteltemperatur / Predicted engine coolant temperature
          signal Pred_Radar_DS_Stat: start 22, 2 bit, little-endian, data-type=c02_Idle_Active_Inactive, init-value=XDIS_54tv8lvpsqhu4dtjgc8hg03xr/l3, transfer-property=PENDING, to ISM TCM  # Status radarbasierte vorausschauende Fahrstrategie / Status of the radar based predictive Driving Strategy
          signal Pred_Slope_DS: start 0, 10 bit, little-endian, data-type=c10_perc_m30_70_0k1, init-value=XDIS_9q9tei3m1fjehhzmxi2ewe8ef/l1023, transfer-property=PENDING, to ISM TCM  # Vorhergesagtes Gefälle des HRC / Predicted slope of the HRC
          signal Pred_VehAccel_Y_DS: start 24, 8 bit, little-endian, data-type=c08_m_p_sq_s_m10k24_10k08_0k08, init-value=XDIS_9e7l6lmqsltnn6zpnqq36qyov/l255, transfer-property=PENDING, to ISM TCM  # Vorhergesagte Y-Beschleunigung der vorrausschauenden Schaltstrategie / Predicted acceleration y of the predictive Driving Strategy
          signal RadarBsd_GrShft_Rq_DS: start 32, 2 bit, little-endian, data-type=c02_RadarBsd_GrShft_Rq_DS, init-value=XDIS_ex01vmxcoylj8za4oq7tkykis/l3, transfer-property=PENDING, to ISM TCM  # Ausgabe der radarbasierten vorrauschauenden Schaltstrategie / Output of the radar based predictive Driving Strategy
          signal TrafficFlow_Info_DS: start 19, 3 bit, little-endian, data-type=c03_TrafficFlow_Info_DS, init-value=XDIS_bvznr5hc07mn59ifk3pkwudq7/l7, transfer-property=PENDING, to ISM TCM  # Verkehrsflussinformation für Schaltstrategie / Traffic flow information for the Driving Strategy
          signal CPC_PredStrat_Data_AR2_gtq6klj4fn801tl507uvamgb: little-endian, system-signal=[Act_DynFct_Rq_DS, CoastMd_Rq_CPC, Funct_GrShft_Rq_DS, GrShft_Rq_DS, Pred_Radar_DS_Stat, Pred_Slope_DS, Pred_VehAccel_Y_DS, RadarBsd_GrShft_Rq_DS, TrafficFlow_Info_DS], to ISM TCM  # CPC_PredStrat_Data_AR2 (degraded)
      frame VehPwrMngmnt_Rq_AR: id 0x375, from ECM, to CPC TCM, frame-length=8, can-addressing-mode=STANDARD  # Powertrain Vehicle Power Management
        pdu VehPwrMngmnt_Rq_AR: length=64, unused-bit-pattern=0, cyclic-timing={repeating-time=1.0, starting-time=0.165}  # Powertrain Vehicle Power Management
          signal EM_OutDC_Curr_ECM: start 16, 16 bit, little-endian, data-type=c16_A_m3276k6_3276k8_0k1, init-value=XDIS_e1wuwi89appks4l77615nudip/l65535, transfer-property=PENDING, to CPC  # DC Strom / Electric machine output DC current
          signal EM_OutDC_Volt_ECM: start 32, 16 bit, little-endian, data-type=c16_V_0_6553k4_0k1, init-value=XDIS_521gwchioxgex9yqc7rslp1tg/l65535, transfer-property=PENDING, to CPC  # DC Spannung / Electric machine output DC voltage
          signal GenLoad: start 8, 6 bit, little-endian, data-type=c06_perc_0_31_3k22581, init-value=XDIS_2crnikbdfbucgvm5bjgk7sxb0/l63, to CPC TCM  # Generatorauslastung / Actual generator load
          signal PN14_GenExctCurr: start 0, 8 bit, little-endian, data-type=c08_A_0_12k7_0k05, init-value=XDIS_cs0ttnzu21fq87jdomn5pyq2e/l255, to CPC TCM  # Generator-Erregerstrom / Generator excitation current
          signal PN14_GenStyle: start 48, 4 bit, little-endian, data-type=c04_PN14_GenStyle, init-value=XDIS_7fjp9m00yv1c68qpmhcmvk34n/l15, transfer-property=PENDING, to CPC  # Generator-Variante / Generator style
          signal PN14_Gen_Stat_9qi9lgyawpnfo9d10zylnfnr0: little-endian, system-signal=[GenLoad, PN14_GenExctCurr], transfer-property=PENDING, to CPC TCM  # Powernet 14V generator status (degraded)
      frame EngCtrl_Stat3_AR: id 0x3D8, from ECM, to FSCM, frame-length=8, can-addressing-mode=STANDARD
        pdu EngCtrl_Stat3_AR: length=64, unused-bit-pattern=0, cyclic-timing={repeating-time=1.0, starting-time=0.155}
          signal FuelPress_Diff: start 0, 8 bit, little-endian, data-type=c08_mbar_m381_381_3, init-value=XDIS_4uzadvcjidv26jpzq30itq1yy/l255, transfer-property=PENDING, to FSCM  # Kraftstoffdruck Differenz / Fuel differential pressure
          signal FuelVlv_Opn: start 8, 1 bit, little-endian, data-type=DC_BOOL, init-value=XDIS_h5tcyk98kzbgrc5svasomeyt/lfalse, transfer-property=PENDING, to FSCM  # Kraftstoffventil offen / Fuel open
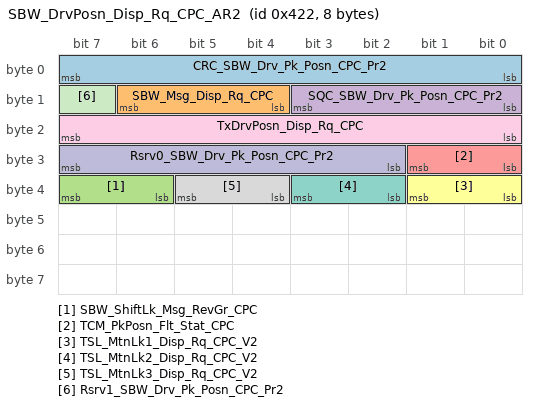
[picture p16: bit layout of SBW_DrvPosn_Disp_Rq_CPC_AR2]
      frame SBW_DrvPosn_Disp_Rq_CPC_AR2: id 0x422, from CPC, to TCM, frame-length=8, can-addressing-mode=STANDARD  # Anzeige Shift by Wire und Fahrstufe / Shift by wire and driving position display request
        pdu SBW_DrvPosn_Disp_Rq_CPC_AR2: length=64, unused-bit-pattern=0, cyclic-timing={repeating-time=0.2, starting-time=0.13}, event-controlled-timing=number-of-repeats=0, minimum-delay=0.02  # Anzeige Shift by Wire und Fahrstufe / Shift by wire and driving position display request
          signal CRC_SBW_Drv_Pk_Posn_CPC_Pr2: start 0, 8 bit, little-endian, data-type=c08_CRC_woSNA, init-value=l135, transfer-property=PENDING, to TCM  # CRC-Checksumme der Signal Gruppe gemäß AUTOSAR Profil 2 / CRC-checksum of signal group according to AUTOSAR Profile 2
          signal SBW_Msg_Disp_Rq_CPC: start 12, 3 bit, little-endian, data-type=c03_SBW_Msg_Disp_Rq, init-value=XDIS_1btwp40vfzysklfc9vhyfb8lg/lIDLE, transfer-property=TRIGGERED-ON-CHANGE, to TCM  # Anforderung Shift by wire Meldung anzeigen von CPC / Shift by wire message display request by CPC
          signal SBW_ShiftLk_Msg_RevGr_CPC: start 38, 2 bit, little-endian, data-type=c02_SBW_ShiftLk_Msg_RevGr_TCM, init-value=XDIS_5ky3lk60o7o5ndyw6cx2aook/l3, transfer-property=TRIGGERED-ON-CHANGE, to TCM  # SBW Nachricht CPC "Bremse betätigen, um Rückwärtsgang einzulegen" / SBW Message from CPC "Press Brake to orient Reverse Gear"
          signal SQC_SBW_Drv_Pk_Posn_CPC_Pr2: start 8, 4 bit, little-endian, data-type=c04_0_15_1_SNA_na, init-value=XDIS_2gdok7is6uk227cngmpgf9wxb/l0, transfer-property=PENDING, to TCM  # Sequenzzähler / Sequence counter
          signal TCM_PkPosn_Flt_Stat_CPC: start 24, 2 bit, little-endian, data-type=c02_TCM_PkPosn_Flt, init-value=XDIS_8k19ab1yez6czusrvo38kfnut/lIDLE, transfer-property=TRIGGERED-ON-CHANGE, to TCM  # Störung Parksperre / Transmission park position fault state
          signal TSL_MtnLk1_Disp_Rq_CPC_V2: start 32, 2 bit, little-endian, data-type=c02_TSL_MtnLk_Disp_Rq_V2, init-value=XDIS_46hl4413mztp2ukvqdcv4cwpj/lIDLE, transfer-property=TRIGGERED-ON-CHANGE, to TCM  # Anforderung Getriebewählhebelsperre 1 Anzeige von CPC / Transmission selector lever motion lock 1 display request by CPC
          signal TSL_MtnLk2_Disp_Rq_CPC_V2: start 34, 2 bit, little-endian, data-type=c02_TSL_MtnLk2_3_Disp_Rq_V2, init-value=XDIS_ekoet742eksgh9ctith6nex6m/lIDLE, transfer-property=TRIGGERED-ON-CHANGE, to TCM  # Anforderung Getriebewählhebelsperre 2 Anzeige von CPC / Transmission selector lever motion lock 2 display request by CPC
          signal TSL_MtnLk3_Disp_Rq_CPC_V2: start 36, 2 bit, little-endian, data-type=c02_TSL_MtnLk2_3_Disp_Rq_V2, init-value=XDIS_ekoet742eksgh9ctith6nex6m/lIDLE, transfer-property=TRIGGERED-ON-CHANGE, to TCM  # Anforderung Getriebewählhebelsperre 3 Anzeige von CPC / Transmission selector lever motion lock 3 display request by CPC
          signal TxDrvPosn_Disp_Rq_CPC: start 16, 8 bit, little-endian, data-type=c08_TxDrvPosn, init-value=XDIS_1cx5hyudrxwg04ni87gsdlad7/l255, transfer-property=TRIGGERED-ON-CHANGE, to TCM  # Anforderung Anzeige Getriebefahrstufe von CPC / Transmission driving position display request by CPC
          signal Rsrv0_SBW_Drv_Pk_Posn_CPC_Pr2: start 26, 6 bit, little-endian, data-type=Rsrv06, init-value=XDIS_zukcixzhzplmgdoo03mopm29/l0, transfer-property=PENDING, to TCM  # Reserviert für zukünftige Verwendung / Reserved for future use
          signal Rsrv1_SBW_Drv_Pk_Posn_CPC_Pr2: start 15, 1 bit, little-endian, data-type=Rsrv01, init-value=XDIS_e2uhxyvdu33zsyqfjnk549pp2/l0, transfer-property=PENDING, to TCM  # Reserviert für zukünftige Verwendung / Reserved for future use
          signal SBW_Drv_Pk_Posn_CPC_Pr2_acd3oordbhg0yjkmuwx4u8jib: little-endian, system-signal=[CRC_SBW_Drv_Pk_Posn_CPC_Pr2, Rsrv0_SBW_Drv_Pk_Posn_CPC_Pr2, Rsrv1_SBW_Drv_Pk_Posn_CPC_Pr2, SBW_Msg_Disp_Rq_CPC, SQC_SBW_Drv_Pk_Posn_CPC_Pr2, TCM_PkPosn_Flt_Stat_CPC, TxDrvPosn_Disp_Rq_CPC], to TCM  # SBW_Drv_Pk_Posn_CPC_Pr2 (degraded)
      frame HYBRID_POWERTRAIN_R1_AR2: id 0x427, from CPC, to TCM, frame-length=8, can-addressing-mode=STANDARD
        pdu HYBRID_POWERTRAIN_R1_AR2: length=64, unused-bit-pattern=0, cyclic-timing={repeating-time=0.2, starting-time=0.09}
          signal EM01_OilCool_Rotor_Rq: start 25, 3 bit, little-endian, data-type=c03_l_per_min_0_3_0k5, init-value=XDIS_143yj8chof4gyrz0n8zsr7dhu/l7, transfer-property=PENDING, update-indication-bit-position=28, to TCM  # Anforderung Ölkühlung für Läufer / Oil cooling request for rotor
          signal EM01_OilCool_Stator_Rq: start 11, 4 bit, little-endian, data-type=c04_l_per_min_0_14_1, init-value=XDIS_8olq1vzwet2qxm5w4donr6tmx/l15, transfer-property=PENDING, update-indication-bit-position=15, to TCM  # Anforderung Ölkühlung für Ständer / Oil cooling request for stator
          signal EM01_RotorObsrv_Temp: start 16, 8 bit, little-endian, data-type=c08_degC_m40_214_1, init-value=XDIS_carqyv2gq7ncv789c849hnl6r/l255, transfer-property=PENDING, update-indication-bit-position=24, to TCM  # Überwachte Läufertemperatur / Observed rotor temperature
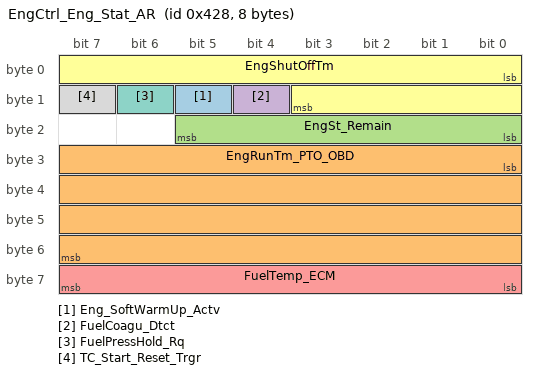
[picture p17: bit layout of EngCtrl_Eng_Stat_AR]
      frame EngCtrl_Eng_Stat_AR: id 0x428, from ECM, to CPC FSCM TCM, frame-length=8, can-addressing-mode=STANDARD
        pdu EngCtrl_Eng_Stat_AR: length=64, unused-bit-pattern=0, cyclic-timing={repeating-time=0.1, starting-time=0.035}, event-controlled-timing=number-of-repeats=0, minimum-delay=0.02
          signal Eng_SoftWarmUp_Actv: start 13, 1 bit, little-endian, data-type=DC_BOOL, init-value=XDIS_h5tcyk98kzbgrc5svasomeyt/lfalse, transfer-property=TRIGGERED-ON-CHANGE, to CPC TCM  # Motor schonenden Warmlaufs aktiv / Engine soft warm-up active
          signal EngRunTm_PTO_OBD: start 24, 32 bit, little-endian, data-type=c32_s_0_4294967294_1, init-value=XDIS_c8v40vytc583vwtspwjkq57k3/l0, transfer-property=PENDING, to CPC FSCM  # PTO Gesamtlaufzeit / PTO Total run time for the life of vehicle
          signal EngSt_Remain: start 16, 6 bit, little-endian, data-type=c06_0_63_1_SNA_na, init-value=XDIS_efjwndmyv9jwvt4o20fd0h4jr/l0, transfer-property=PENDING, update-indication-bit-position=22  # Verbleibende Motor-Starts / Remaining engine starts
          signal FuelCoagu_Dtct: start 12, 1 bit, little-endian, data-type=DC_BOOL, init-value=XDIS_h5tcyk98kzbgrc5svasomeyt/lfalse, transfer-property=PENDING, to FSCM  # Kraftversulzung erkannt / Fuel coagulation detected
          signal FuelTemp_ECM: start 56, 8 bit, little-endian, data-type=c08_degC_m50_204_1, init-value=XDIS_1qgh8ijswcrhuty1cyrfufsk3/l255, transfer-property=PENDING, to FSCM  # Aktueller Kraftstofftemperatur ECM / Actual Fuel temperature ECM
          signal EngShutOffTm: start 0, 12 bit, little-endian, data-type=c12_min_0_4094_1, init-value=XDIS_d65q5o6fvqky5zbqr8rc19l61/l4095, transfer-property=PENDING, update-indication-bit-position=23  # Motorabstellzeit / Engine shut-off time
          signal FuelPressHold_Rq: start 14, 1 bit, little-endian, data-type=DC_BOOL, init-value=XDIS_h5tcyk98kzbgrc5svasomeyt/lfalse, transfer-property=PENDING  # Kraftstoffdruck halten / Fuell pressure hold request
          signal TC_Start_Reset_Trgr: start 15, 1 bit, little-endian, data-type=DC_BOOL, init-value=XDIS_h5tcyk98kzbgrc5svasomeyt/lfalse, transfer-property=PENDING  # Reiserechner "Ab Start Reset" Trigger / Trip computer start reset trigger
      frame CHASSIS_POWERTRAIN_R1_AR2: id 0x43D, from CPC, to ECM ISM TCM, frame-length=8, can-addressing-mode=STANDARD
        pdu CHASSIS_POWERTRAIN_R1_AR2: length=64, unused-bit-pattern=0, cyclic-timing={repeating-time=0.1, starting-time=0.0}, event-controlled-timing=number-of-repeats=0, minimum-delay=0.02
          signal ABC_PmpTrq: start 40, 8 bit, little-endian, data-type=c08_Nm_0_63k5_0k25, init-value=XDIS_3tke51neyh9tc3i280hit3n6t/l255, to ECM TCM  # Lastmoment ABC-Pumpe (nicht bei elektr. Pumpe) / Actual ABC-pump crankshaft torque (not if electrical pump)
          signal ActvDnShift_Rq_AS: start 39, 1 bit, little-endian, data-type=DC_BOOL, init-value=XDIS_h5tcyk98kzbgrc5svasomeyt/lfalse, to TCM(timeout 1.55 s)  # Aktive Rückschaltung / Active down shift
          signal ADC_SwLED_Rq_V2: start 0, 2 bit, little-endian, data-type=c02_ADC_SwLED_Rq_V2, init-value=lSPORT_COMFORT_OFF, transfer-property=TRIGGERED-ON-CHANGE, update-indication-bit-position=2, to ECM TCM  # Anforderung LED Taster Aktive Dämpfungskontrolle ein / Active Damping Control switch LED request
          signal AirTemp_Outsd: start 16, 8 bit, little-endian, data-type=c08_degC_m40_85_0k5_Init, init-value=XDIS_6xus7h4johp7w01aac5miev9n/l255, transfer-property=PENDING, update-indication-bit-position=32, to TCM  # Außenlufttemperatur / Outside air temperature
          signal DynFLDS_Supp_Rq_AS: start 13, 1 bit, little-endian, data-type=DC_BOOL, init-value=XDIS_h5tcyk98kzbgrc5svasomeyt/lfalse, to TCM(timeout 1.55 s)  # Unterdrückung dynamische Vollastrückschaltung / Suppression of dynamic full load down shift request
          signal EngRPM_Rq_ABC: start 24, 8 bit, little-endian, data-type=c08_rpm_0_2540_10, init-value=XDIS_4lbkzmttx3raa0rous18ftgmy/l255, to ECM TCM  # Anforderung Motordrehzahl / Engine speed request
          signal EngTrqMin_Rq_RBS: start 54, 1 bit, little-endian, data-type=DC_BOOL, init-value=XDIS_h5tcyk98kzbgrc5svasomeyt/lfalse, to TCM(timeout 1.55 s)  # Motormomentenanforderung Min / Engine torque request minimum
          signal GrMax_Rq_ESP_V2: start 60, 4 bit, little-endian, data-type=c04_GrMax_Rq_v2, init-value=XDIS_7uq2qghvjbhki2cbg83r4b55h/lPASSIVE, to TCM(timeout 1.55 s)  # Sollgang, obere Grenze / Requested gear, upper limit
          signal GrMin_Rq_ESP_V2: start 56, 4 bit, little-endian, data-type=c04_GrMin_Rq_v2, init-value=XDIS_9m6sblz9nzl5h9osu1t5bxtb7/lPASSIVE, to TCM(timeout 1.55 s)  # Sollgang, untere Grenze / Requested gear, lower limit
          signal GrMinMax_Rq_DTR: start 52, 1 bit, little-endian, data-type=DC_BOOL, init-value=XDIS_h5tcyk98kzbgrc5svasomeyt/lfalse, to TCM(timeout 1.55 s)  # Sollgang-Anforderung von DTR / Gear limit request from DTR
          signal PlugInHyb_OprtnMd_V2: start 34, 3 bit, little-endian, data-type=c03_Hyb_EV_ESave_Blank_Chrg, init-value=lHYBRID, transfer-property=PENDING, update-indication-bit-position=37, to TCM  # Plug-In hybrid Betriebsmodus / Plug-In hybrid operation mode
          signal PwrFreeD_Supp_Rq_AS: start 11, 2 bit, little-endian, data-type=c02_PwrFreeD_Supp_Rq, init-value=XDIS_brn6ekenriy9tl0cxpiegrr91/lIDLE, to TCM(timeout 1.55 s)  # Anforderung "Kraftfrei in D" / "Power-free in D" suppression request
          signal ShftChrDsp_Rq_AS: start 48, 4 bit, little-endian, data-type=c04_ShftChrDsp_Rq, init-value=lSKL0, to TCM(timeout 1.55 s)  # Anforderung Schaltlinienverschiebung / Shift characteristic displacement request
          signal SSA_ECO_Sw_LED_On_Rq: start 14, 2 bit, little-endian, data-type=c02_Off_On, init-value=XDIS_e0p8eo65xegbkeoit2yb8bj0v/l3, transfer-property=TRIGGERED-ON-CHANGE, update-indication-bit-position=53, to TCM  # Stopp/Start-Automatik: ECO-Taster LED Einschaltanforderung / Stop/Start Automatic: ECO switch LED on request
          signal Term54_Actv: start 6, 1 bit, little-endian, data-type=DC_BOOL, init-value=XDIS_h5tcyk98kzbgrc5svasomeyt/lfalse, transfer-property=TRIGGERED-ON-CHANGE, update-indication-bit-position=7, to ISM TCM  # Klemme 54 (Bremslicht) Rückmeldung von SAM_R / Terminal 54 (brake light) active (from SAM_R)
          signal VehDrvProg_M_Rq_PT: start 8, 2 bit, little-endian, data-type=c02_NPsd_Psd, init-value=XDIS_daq9spsdlmsva4t7y2tw69dn3/l3, transfer-property=TRIGGERED-ON-CHANGE, to TCM  # Anforderung Manuelles Schaltprogramm (M) (alle Telematikbedienmöglichkeiten) / Vehicle driving program manual transmission (M) request (all telematics input methods)
          signal VehDrvProg_M_Rq_PT_Avl: start 10, 1 bit, little-endian, data-type=DC_BOOL, init-value=XDIS_h5tcyk98kzbgrc5svasomeyt/lfalse, transfer-property=TRIGGERED-ON-CHANGE, to TCM  # Diagnose Bit für VehDrvProg_M_Rq_PT / Diagnostics Bit for VehDrvProg_M_Rq_PT
          signal VehDrvProgSw_Psd: start 3, 2 bit, little-endian, data-type=c02_NPsd_NDefORDown_PsdORUp, init-value=XDIS_6gordusgbyogi4gfgkos43f1m/l3, transfer-property=TRIGGERED-ON-CHANGE, update-indication-bit-position=5, to TCM  # Taster Fahrprogramm betätigt / Vehicle driving program switch pressed
          signal Eng_Rq_ABC_Pr2_6os4g52vhw32mgg7rkesn49tl: little-endian, system-signal=[ABC_PmpTrq, EngRPM_Rq_ABC], transfer-property=TRIGGERED-ON-CHANGE, update-indication-bit-position=33, to ECM TCM  # Active Body Control Anforderung an Motorsteuergerät (degraded) / Active Body Control Engine request (degraded)
          signal PT_Rq_ESP_Pr2_7zyc9ptgtwt6c0u4cmgedic39: little-endian, system-signal=[ActvDnShift_Rq_AS, DynFLDS_Supp_Rq_AS, EngTrqMin_Rq_RBS, GrMax_Rq_ESP_V2, GrMin_Rq_ESP_V2, GrMinMax_Rq_DTR, PwrFreeD_Supp_Rq_AS, ShftChrDsp_Rq_AS], transfer-property=TRIGGERED-ON-CHANGE, update-indication-bit-position=38, to TCM(timeout 1.55 s)  # Antriebsstrang-Request (degraded) / Powertrain request (degraded)
      frame DIAG_RQ_GLOBAL_UDS: id 0x441, from CPC, to ASX FFAP_STAR_2 FSCM ISM TCM, frame-length=8, can-addressing-mode=STANDARD  # Funktionale Diagnose Anfrage (UDS) / Functional Diagnostic Request (UDS)
        n pdu DIAG_RQ_GLOBAL_UDS: length=64, unused-bit-pattern=0  # Funktionaler Diagnose-Request (UDS) / Functional Diagnostic Request (UDS)
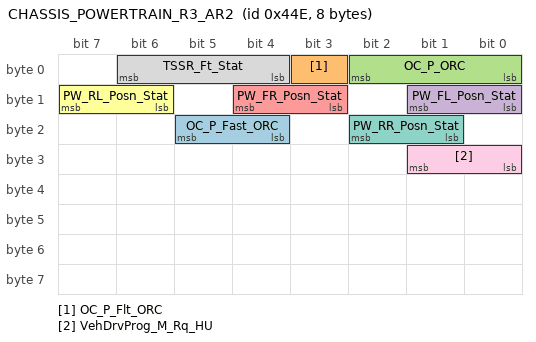
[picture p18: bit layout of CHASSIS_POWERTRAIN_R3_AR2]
      frame CHASSIS_POWERTRAIN_R3_AR2: id 0x44E, from CPC, to ASX TCM, frame-length=8, can-addressing-mode=STANDARD
        pdu CHASSIS_POWERTRAIN_R3_AR2: length=64, unused-bit-pattern=0, cyclic-timing={repeating-time=0.5, starting-time=0.25}, event-controlled-timing=number-of-repeats=0, minimum-delay=0.1
          signal OC_P_Fast_ORC: start 20, 2 bit, little-endian, data-type=c02_OC_Fast, init-value=XDIS_8spmd8rxc4l164byfeohhgwuq/l3, transfer-property=TRIGGERED-ON-CHANGE, update-indication-bit-position=22, to ASX  # Schnelle Sitzbelegungserkennung Beifahrer (Benutzung nur in Verbindung mit Funktion Gurtwarnung) / Occupant detection passenger fast (Only for use with seat belt reminder)
          signal OC_P_Flt_ORC: start 3, 1 bit, little-endian, data-type=DC_BOOL, init-value=XDIS_h5tcyk98kzbgrc5svasomeyt/lfalse, to ASX  # Fehler Sitzbelegungserkennung Beifahrer / Occupant classification passenger fault
          signal OC_P_ORC: start 0, 3 bit, little-endian, data-type=c03_OC, init-value=XDIS_dkb5h6hnop6bsl0vyu1k4jwow/l7, to ASX  # Sitzbelegungserkennung Beifahrer / Occupant classification passenger
          signal PW_FL_Posn_Stat: start 8, 2 bit, little-endian, data-type=c02_PW_Posn_Stat, init-value=XDIS_6gtvtx8k4w3ft2iz5jjwfb9x2/l3, to ASX  # Position Fensterheberansteuerung vorne links / Power window front left position state
          signal PW_FR_Posn_Stat: start 11, 2 bit, little-endian, data-type=c02_PW_Posn_Stat, init-value=XDIS_6gtvtx8k4w3ft2iz5jjwfb9x2/l3, to ASX  # Position Fensterheberansteuerung vorne rechts / Power window front right position state
          signal PW_RL_Posn_Stat: start 14, 2 bit, little-endian, data-type=c02_PW_Posn_Stat, init-value=XDIS_6gtvtx8k4w3ft2iz5jjwfb9x2/l3, to ASX  # Position Fensterheberansteuerung hinten links / Power window rear left position state
          signal PW_RR_Posn_Stat: start 17, 2 bit, little-endian, data-type=c02_PW_Posn_Stat, init-value=XDIS_6gtvtx8k4w3ft2iz5jjwfb9x2/l3, to ASX  # Position Fensterheberansteuerung hinten rechts / Power window rear right position state
          signal TSSR_Ft_Stat: start 4, 3 bit, little-endian, data-type=c03_TSSR_Stat, init-value=XDIS_3m20hovfm8hy3au4j9itz9zkd/l7, to ASX  # Schiebehebedach Status vorne / Front tilt/slide sunroof state
          signal VehDrvProg_M_Rq_HU: start 24, 2 bit, little-endian, data-type=c02_NPsd_Psd, init-value=XDIS_daq9spsdlmsva4t7y2tw69dn3/l3, transfer-property=TRIGGERED-ON-CHANGE, update-indication-bit-position=26, to TCM  # Anforderung Manuelles Schaltprogramm (M) (alle Telematikbedienmöglichkeiten) / Vehicle driving program manual transmission (M) request (all telematics input methods)
          signal OC_P_ORC_Stat_b88mnsk10wi9igll55wkw677g: little-endian, system-signal=[OC_P_Flt_ORC, OC_P_ORC], transfer-property=TRIGGERED-ON-CHANGE, update-indication-bit-position=23, to ASX  # Status Sitzbelegungserkennung Beifahrer (degraded) / Occupant classification passenger state (degraded)
          signal PW_FL_Stat_V2_6v70rlaz165e71dnyncul6g95: little-endian, system-signal=PW_FL_Posn_Stat, transfer-property=TRIGGERED-ON-CHANGE, update-indication-bit-position=10, to ASX  # PW_FL_Stat_V2 (degraded)
          signal PW_FR_Stat_V2_2x3udh0wjaxzx1twouxqkpy52: little-endian, system-signal=PW_FR_Posn_Stat, transfer-property=TRIGGERED-ON-CHANGE, update-indication-bit-position=13, to ASX  # PW_FR_Stat_V2 (degraded)
          signal PW_RL_Stat_V2_dgy4a11dbcs3i53xerhwo9yp0: little-endian, system-signal=PW_RL_Posn_Stat, transfer-property=TRIGGERED-ON-CHANGE, update-indication-bit-position=16, to ASX  # PW_RL_Stat_V2 (degraded)
          signal PW_RR_Stat_V2_adyzba63i840bap88qsx59309: little-endian, system-signal=PW_RR_Posn_Stat, transfer-property=TRIGGERED-ON-CHANGE, update-indication-bit-position=19, to ASX  # PW_RR_Stat_V2 (degraded)
          signal TSSR_Stat_3s1wz4y3oqhndwn553g3cyqdy: little-endian, system-signal=TSSR_Ft_Stat, transfer-property=TRIGGERED-ON-CHANGE, update-indication-bit-position=7, to ASX  # TSSR_Stat (degraded)
      frame CHASSIS_POWERTRAIN_R4_AR2: id 0x456, from CPC, to ASX TCM, frame-length=8, can-addressing-mode=STANDARD
        pdu CHASSIS_POWERTRAIN_R4_AR2: length=64, unused-bit-pattern=0, cyclic-timing={repeating-time=0.2, starting-time=0.12}, event-controlled-timing=number-of-repeats=0, minimum-delay=0.02
          signal CT_Stat: start 25, 3 bit, little-endian, data-type=c03_CT_Stat, init-value=XDIS_8qdi3elilivdzh499jr1d0mu5/l7, transfer-property=PENDING, update-indication-bit-position=28, to ASX  # Verdeckstatus / Convertible Top State
          signal ESP_FricCoeff_Stat: start 19, 3 bit, little-endian, data-type=c03_ESP_FricCoeff_Stat, init-value=XDIS_2b0kumr7w8srfxx8b0glpobif/lIDLE, to TCM(timeout 2.1 s)  # Der Stand des Reibungskoeffizient vom ESP (only AMG) / Status of friction coefficient from ESP (only AMG)
          signal ESP_Md_Rq_Ack: start 22, 2 bit, little-endian, data-type=c02_ESP_Md_Rq_Ack, init-value=XDIS_144h16k13t6h9czp5y7udtr3s/lON, to TCM  # Bestätigung Anforderung ESP-Modus / ESP mode request acknowledge
          signal LDC_Spd_Dsr: start 0, 8 bit, little-endian, data-type=c08_LDC_Spd, init-value=XDIS_dvm76papxqeuwchaycpewq03l/l253, to TCM  # Gewünschte Geschwindigkeit Längsregler / Desired longitudinal controller speed
          signal LDC_Spd_Dsr_RDU: start 8, 8 bit, little-endian, data-type=c08_LDC_Spd, init-value=XDIS_dvm76papxqeuwchaycpewq03l/l253, to TCM  # Gewünschte Geschwindigkeit Längsregler / Desired longitudinal controller speed
          signal AWD_TCASE_Rq_ESP_Pr2_6zte6z0zjmd0zcj41mtuz08ph: little-endian, system-signal=ESP_FricCoeff_Stat, transfer-property=PENDING, update-indication-bit-position=18, to TCM(timeout 2.1 s)  # Anforderung Differentialsperren / Allradkupplung (degraded) / Differential locks AWD Clutch request (degraded)
          signal ESP_Disp_Rq_Pr2_39wzgvb26pwujef2adbohryly: little-endian, system-signal=ESP_Md_Rq_Ack, transfer-property=TRIGGERED-ON-CHANGE, update-indication-bit-position=24, to TCM  # Anzeige ESP (degraded) / ESP display request (degraded)
          signal LDC_Disp_Rq_ESP_8w7vdtj2cn0be26e2qunelq4k: little-endian, system-signal=LDC_Spd_Dsr, transfer-property=TRIGGERED-ON-CHANGE, update-indication-bit-position=16, to TCM  # Anforderung Display-Anzeigen Längsregler (degraded) / Longitudinal controller display request (degraded)
          signal LDC_Disp_Rq_RDU_V2_37596z9a6jee3gfi1bkb9wjtb: little-endian, system-signal=LDC_Spd_Dsr_RDU, transfer-property=TRIGGERED-ON-CHANGE, update-indication-bit-position=17, to TCM  # Anforderung Display-Anzeigen Längsregler (degraded) / Longitudinal controller display request (degraded)
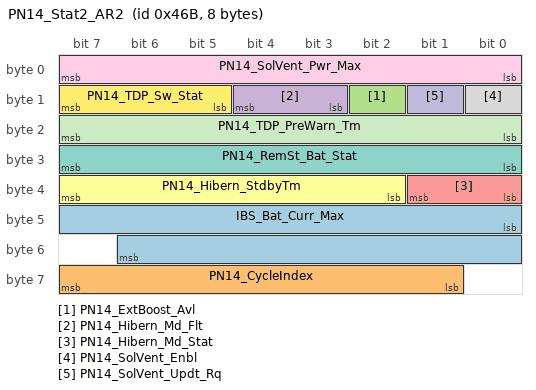
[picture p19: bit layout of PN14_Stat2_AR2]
      frame PN14_Stat2_AR2: id 0x46B, from CPC, to ECM FSCM TCM, frame-length=8, can-addressing-mode=STANDARD  # Status 14V Bordnetz 2 / Powernet 14V state 2
        pdu PN14_Stat2_AR2: length=64, unused-bit-pattern=0, cyclic-timing=repeating-time=0.2, event-controlled-timing=number-of-repeats=0, minimum-delay=0.05  # Status 14V Bordnetz 2 / Powernet 14V state 2
          signal IBS_Bat_Curr_Max: start 40, 15 bit, little-endian, data-type=c15_A_m2000_0_0k1, init-value=l32767, transfer-property=PENDING  # IBS Batteriestrom Max / IBS Battery Current Max
          signal PN14_CycleIndex: start 57, 7 bit, little-endian, data-type=c07_0_126_1_SNA, init-value=XDIS_37u671a64pxgywqfufc5m7a6l/l0, transfer-property=PENDING  # Bordnetzdiagnose Synchronisationsindex / PN-Diagnostics Sync Index
          signal PN14_ExtBoost_Avl: start 10, 1 bit, little-endian, data-type=DC_BOOL, init-value=XDIS_h5tcyk98kzbgrc5svasomeyt/lfalse, transfer-property=TRIGGERED-ON-CHANGE  # Boosting 14V Externer Lader nach 48V verfuegbar / Boosting from 14V external charger to 48V available
          signal PN14_Hibern_Md_Flt: start 11, 2 bit, little-endian, data-type=c02_PN14_Hibern_Md_Flt, init-value=XDIS_48lw99wcmt2gfe6ctxxml2dph/l3, transfer-property=TRIGGERED-ON-CHANGE  # Fehler Funktion "Lange Standzeit" / Powernet Hibernation mode fault
          signal PN14_Hibern_Md_Stat: start 32, 2 bit, little-endian, data-type=c02_Off_On, init-value=XDIS_e0p8eo65xegbkeoit2yb8bj0v/l3, transfer-property=TRIGGERED-ON-CHANGE  # Status Funktion "Lange Standzeit" / Powernet Hibernation mode state
          signal PN14_Hibern_StdbyTm: start 34, 6 bit, little-endian, data-type=c06_Week_0_60_1, init-value=XDIS_7qofwcgungbr7ph21duzxj03/l63, transfer-property=TRIGGERED-ON-CHANGE  # Restzeit Funktion "Lange Standzeit" / Powernet Hibernation mode available standby time
          signal PN14_RemSt_Bat_Stat: start 24, 8 bit, little-endian, data-type=c08_perc_0_100_1, init-value=l50, transfer-property=PENDING  # Batteriestatus für Motorfernstart / Battery state for remote start
          signal PN14_SolVent_Enbl: start 8, 1 bit, little-endian, data-type=DC_BOOL, init-value=XDIS_h5tcyk98kzbgrc5svasomeyt/lfalse, transfer-property=PENDING  # Solarlüften erlaubt / Solar ventilation enabled
          signal PN14_SolVent_Pwr_Max: start 0, 8 bit, little-endian, data-type=c08_W_0_100, init-value=XDIS_cwzsz5ekwyls7to4nkihtfz4x/l255, transfer-property=PENDING  # Maximale Leistung Solarlüften / Solar ventilation maximum power
          signal PN14_SolVent_Updt_Rq: start 9, 1 bit, little-endian, data-type=DC_BOOL, init-value=XDIS_h5tcyk98kzbgrc5svasomeyt/lfalse, transfer-property=PENDING  # Solarlüften Anforderung Temperaturupdate / Solar ventilation temperature update request
          signal PN14_TDP_PreWarn_Tm: start 16, 8 bit, little-endian, data-type=c08_s_0_1270_5, init-value=l60, transfer-property=PENDING, to ECM(timeout 2.1 s) FSCM(timeout 2.1 s) TCM(timeout 2.1 s)  # Vorwarnzeit Tiefentladeschutz / Total discharge protection pre warn time
          signal PN14_TDP_Sw_Stat: start 13, 3 bit, little-endian, data-type=c03_PN14_TDP_Sw_Stat, init-value=XDIS_15lbynoto8hu3um81qo7cznt0/lCLS, transfer-property=TRIGGERED-ON-CHANGE, to ECM(timeout 2.1 s) FSCM(timeout 2.1 s) TCM(timeout 2.1 s)  # Status Tiefentladeschutz / Total discharge protection switch state
          signal PN14_TDP_Stat_7ug3myfadyinv3s4lvtfvpcqb: little-endian, system-signal=[PN14_TDP_PreWarn_Tm, PN14_TDP_Sw_Stat], to ECM(timeout 2.1 s) FSCM(timeout 2.1 s) TCM(timeout 2.1 s)  # Status Tiefentladeschutz 14V Bordnetz (degraded) / Powernet 14V total discharge protection switch state (degraded)
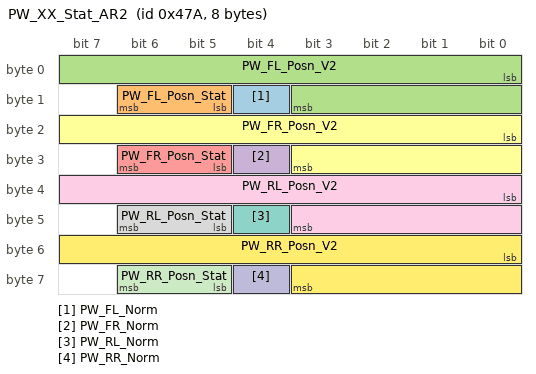
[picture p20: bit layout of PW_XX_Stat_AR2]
      frame PW_XX_Stat_AR2: id 0x47A, from CPC, to ASX TGW, frame-length=8, can-addressing-mode=STANDARD
        pdu PW_XX_Stat_AR2: length=64, unused-bit-pattern=0, cyclic-timing=repeating-time=0.5, event-controlled-timing=number-of-repeats=0, minimum-delay=0.1
          signal PW_FL_Norm: start 12, 1 bit, little-endian, data-type=DC_BOOL, init-value=XDIS_h5tcyk98kzbgrc5svasomeyt/lfalse, to ASX TGW  # Fensterheber vorne links normiert / Power window front left normalized
          signal PW_FL_Posn_Stat: start 13, 2 bit, little-endian, data-type=c02_PW_Posn_Stat, init-value=XDIS_6gtvtx8k4w3ft2iz5jjwfb9x2/l3, to ASX TGW  # Position Fensterheberansteuerung vorne links / Power window front left position state
          signal PW_FL_Posn_V2: start 0, 12 bit, little-endian, data-type=c12_mm_m1023_1024_0k5, init-value=XDIS_aa60nt5d7egr455yb39jbe86r/l4095, to ASX TGW  # El. Fensterheber vorne links Position / Power window front left position
          signal PW_FR_Norm: start 28, 1 bit, little-endian, data-type=DC_BOOL, init-value=XDIS_h5tcyk98kzbgrc5svasomeyt/lfalse, to ASX TGW  # Fensterheber vorne rechts normiert / Power window front right normalized
          signal PW_FR_Posn_Stat: start 29, 2 bit, little-endian, data-type=c02_PW_Posn_Stat, init-value=XDIS_6gtvtx8k4w3ft2iz5jjwfb9x2/l3, to ASX TGW  # Position Fensterheberansteuerung vorne rechts / Power window front right position state
          signal PW_FR_Posn_V2: start 16, 12 bit, little-endian, data-type=c12_mm_m1023_1024_0k5, init-value=XDIS_aa60nt5d7egr455yb39jbe86r/l4095, to ASX TGW  # El. Fensterheber vorne rechts Position / Power window front right position
          signal PW_RL_Norm: start 44, 1 bit, little-endian, data-type=DC_BOOL, init-value=XDIS_h5tcyk98kzbgrc5svasomeyt/lfalse, to ASX TGW  # Fensterheber hinten links normiert (nicht R172) / Power window rear left normalized (not R172)
          signal PW_RL_Posn_Stat: start 45, 2 bit, little-endian, data-type=c02_PW_Posn_Stat, init-value=XDIS_6gtvtx8k4w3ft2iz5jjwfb9x2/l3, to ASX TGW  # Position Fensterheberansteuerung hinten links / Power window rear left position state
          signal PW_RL_Posn_V2: start 32, 12 bit, little-endian, data-type=c12_mm_m1023_1024_0k5, init-value=XDIS_aa60nt5d7egr455yb39jbe86r/l4095, to ASX TGW  # El. Fensterheber hinten links Position / Power window rear left position
          signal PW_RR_Norm: start 60, 1 bit, little-endian, data-type=DC_BOOL, init-value=XDIS_h5tcyk98kzbgrc5svasomeyt/lfalse, to ASX TGW  # Fensterheber hinten rechts normiert (nicht R172) / Power window rear right normalized (not R172)
          signal PW_RR_Posn_Stat: start 61, 2 bit, little-endian, data-type=c02_PW_Posn_Stat, init-value=XDIS_6gtvtx8k4w3ft2iz5jjwfb9x2/l3, to ASX TGW  # Position Fensterheberansteuerung hinten rechts / Power window rear right position state
          signal PW_RR_Posn_V2: start 48, 12 bit, little-endian, data-type=c12_mm_m1023_1024_0k5, init-value=XDIS_aa60nt5d7egr455yb39jbe86r/l4095, to ASX TGW  # El. Fensterheber hinten rechts Position / Power window rear right position
          signal PW_FL_Stat_V2_6cv3doeps2jg8qalnshxlbd6j: little-endian, system-signal=[PW_FL_Norm, PW_FL_Posn_Stat, PW_FL_Posn_V2], transfer-property=TRIGGERED-ON-CHANGE, update-indication-bit-position=15, to ASX TGW  # PW_FL_Stat_V2 (degraded)
          signal PW_FR_Stat_V2_br9vsxm9a7yjl7yworl3ulwat: little-endian, system-signal=[PW_FR_Norm, PW_FR_Posn_Stat, PW_FR_Posn_V2], transfer-property=TRIGGERED-ON-CHANGE, update-indication-bit-position=31, to ASX TGW  # PW_FR_Stat_V2 (degraded)
          signal PW_RL_Stat_V2_19hnhwdw4d7qgho1t244h23m6: little-endian, system-signal=[PW_RL_Norm, PW_RL_Posn_Stat, PW_RL_Posn_V2], transfer-property=TRIGGERED-ON-CHANGE, update-indication-bit-position=47, to ASX TGW  # PW_RL_Stat_V2 (degraded)
          signal PW_RR_Stat_V2_300ewz00spt7h0y32xvjjityz: little-endian, system-signal=[PW_RR_Norm, PW_RR_Posn_Stat, PW_RR_Posn_V2], transfer-property=TRIGGERED-ON-CHANGE, update-indication-bit-position=63, to ASX TGW  # PW_RR_Stat_V2 (degraded)
      frame PT_DATA_AR2: id 0x498, from CPC, to ECM TCM, frame-length=8, can-addressing-mode=STANDARD
        pdu PT_DATA_AR2: length=64, unused-bit-pattern=0, cyclic-timing={repeating-time=0.5, starting-time=0.22}  # Koordinierung Antriebsstrang / Powertrain Coordination
          signal EMM_PNHV_Bat_SOC_LoRsltn: start 0, 7 bit, little-endian, data-type=c07_per_0to100_1_SNA, init-value=XDIS_6w7kc8amiekknqhh61qaaoij9/l127, transfer-property=PENDING, to ECM TCM  # Ist-Ladezustand Versorgungsbatterie Hochspannungs-Bordnetz (niedrige Auflösung) / SOC of HV-Battery (low resolution)
      frame ASX_Stat_AR: id 0x4A2, from ASX, to CPC, frame-length=1, can-addressing-mode=STANDARD  # ASX Stat AR
        pdu ASX_Stat_AR: length=8, unused-bit-pattern=0, cyclic-timing={repeating-time=1.0, starting-time=0.0}, event-controlled-timing=number-of-repeats=0, minimum-delay=0.02  # ASX Stat AR
          signal ASX_Stat: start 0, 2 bit, little-endian, data-type=c02_NotActv_Actv_NDef, init-value=XDIS_ezq64jqrud10seps4g49pyj4h/lNOTACTV, transfer-property=PENDING, to CPC  # ASX-Status / State of ASX
          signal DPC_Md_ASX_Rs_CPC: start 2, 4 bit, little-endian, data-type=c04_DPC_Md_ASX, init-value=XDIS_ee6lf6fesmlxx9pcig2c90tw0/lINIT, transfer-property=TRIGGERED-ON-CHANGE, to CPC  # Fahrprogrammwahl: Antwort ASX / Driving program control: ASX mode response
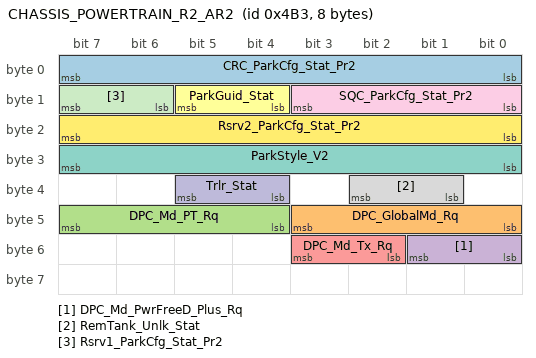
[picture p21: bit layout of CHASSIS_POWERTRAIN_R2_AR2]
      frame CHASSIS_POWERTRAIN_R2_AR2: id 0x4B3, from CPC, to ASX ECM TCM, frame-length=8, can-addressing-mode=STANDARD
        pdu CHASSIS_POWERTRAIN_R2_AR2: length=64, unused-bit-pattern=0, cyclic-timing={repeating-time=0.2, starting-time=0.06}, event-controlled-timing=number-of-repeats=0, minimum-delay=0.02
          signal CRC_ParkCfg_Stat_Pr2: start 0, 8 bit, little-endian, data-type=c08_CRC_woSNA, init-value=l20, transfer-property=PENDING, to TCM  # CRC-Checksumme der Signal Gruppe gemäß AUTOSAR Profil 2 / CRC-checksum of signal group according to AUTOSAR Profile 2
          signal DPC_GlobalMd_Rq: start 40, 4 bit, little-endian, data-type=c04_DPC_GlobalMd_Rq, init-value=XDIS_41wlneoof3s174x1y63qsu1os/lCOMFORT, to ASX(timeout 2.1 s) TCM  # Fahrprogrammwahl: Anforderung Global / Driving program control: global mode request
          signal DPC_Md_PT_Rq: start 44, 4 bit, little-endian, data-type=c04_DPC_Md_PT, init-value=XDIS_didolfsk1r6nfzojvd6lbxo4w/lCOMFORT, to ASX(timeout 2.1 s) TCM  # Fahrprogrammwahl: Anforderung Powertrain / Driving program control: powertrain mode request
          signal DPC_Md_PwrFreeD_Plus_Rq: start 48, 2 bit, little-endian, data-type=c02_NDef_On_Off, init-value=XDIS_3y644026va6c2x8rschu8ysp4/lOFF, to ASX(timeout 2.1 s) TCM  # Fahrprogrammwahl: Anforderung "Kraftfrei in D +" / Driving program control: "Power free in D +" request
          signal DPC_Md_Tx_Rq: start 50, 2 bit, little-endian, data-type=c02_NDef_Man_Auto, init-value=lAUTO, to ASX(timeout 2.1 s) TCM  # Fahrprogrammwahl: Antwort Getriebe (nur AMG) / Driving program control: transmission mode response (only AMG)
          signal ParkGuid_Stat: start 12, 2 bit, little-endian, data-type=c02_ParkGuide_Stat, init-value=lPARK_GUI_INACT, transfer-property=TRIGGERED-ON-CHANGE, to TCM  # Status Parkführung / Parking guidance state
          signal ParkStyle_V2: start 24, 8 bit, little-endian, data-type=c08_ParkStyle_V2, init-value=XDIS_8rj9jyau39wef0k9rwkix7ooy/l255, transfer-property=PENDING, to TCM  # Parkunterstützungstyp / Parking control style
          signal RemTank_Unlk_Stat: start 33, 2 bit, little-endian, data-type=c02_Locked_Unlocked_Err, init-value=lLOCKED, transfer-property=TRIGGERED-ON-CHANGE, update-indication-bit-position=35, to ECM  # Status Drucktankentriegelung (Hybrid) / Remote tank unlock state
          signal SQC_ParkCfg_Stat_Pr2: start 8, 4 bit, little-endian, data-type=c04_0_15_1_SNA_na, init-value=XDIS_2gdok7is6uk227cngmpgf9wxb/l0, transfer-property=PENDING, to TCM  # Sequenzzähler / Sequence counter
          signal Trlr_Stat: start 36, 2 bit, little-endian, data-type=c02_Trl_Stat, init-value=XDIS_3b2408oy0czl0zjvs4t4fel2g/l3, transfer-property=TRIGGERED-ON-CHANGE, update-indication-bit-position=38, to ECM TCM  # Anhängerbetrieb erkannt / Trailer detected
          signal Rsrv1_ParkCfg_Stat_Pr2: start 14, 2 bit, little-endian, data-type=Rsrv02, init-value=XDIS_7jeo5ges9wp8ufla3pohsuw83/l0, transfer-property=PENDING, to ASX ECM TCM  # Reserviert für zukünftige Verwendung / Reserved for future use
          signal Rsrv2_ParkCfg_Stat_Pr2: start 16, 8 bit, little-endian, data-type=Rsrv08, init-value=XDIS_4flxbk4wkjkdew7cw07d9of66/l0, transfer-property=PENDING, to ASX ECM TCM  # Reserviert für zukünftige Verwendung / Reserved for future use
          signal DPC_Master_Rq_Pr2_6xpghgrxfn5z4r5iojjh5y496: little-endian, system-signal=[DPC_GlobalMd_Rq, DPC_Md_PT_Rq, DPC_Md_PwrFreeD_Plus_Rq, DPC_Md_Tx_Rq], transfer-property=TRIGGERED-ON-CHANGE, update-indication-bit-position=39, to ASX(timeout 2.1 s) TCM  # Fahrprogrammwahl Master-Anforderung (degraded) / Driving program control master request (degraded)
          signal ParkCfg_Stat_Pr2_5onkeem8aikyiyd802x686qlp: little-endian, system-signal=[CRC_ParkCfg_Stat_Pr2, ParkGuid_Stat, ParkStyle_V2, Rsrv1_ParkCfg_Stat_Pr2, Rsrv2_ParkCfg_Stat_Pr2, SQC_ParkCfg_Stat_Pr2], update-indication-bit-position=32, to TCM  # ParkCfg_Stat_Pr2 (degraded)
      frame RTC_Stat1_AR2: id 0x4C0, from CPC, to ECM FSCM TCM, frame-length=8, can-addressing-mode=STANDARD  # RealTimeClock Status / RealTimeClock State
        pdu RTC_Stat1_AR2: length=64, unused-bit-pattern=0, cyclic-timing=repeating-time=1.0, event-controlled-timing=number-of-repeats=0, minimum-delay=0.1  # RealTimeClock Status / RealTimeClock State
          signal DayCnt: start 0, 16 bit, little-endian, data-type=c16_Days_0_65534_1, init-value=XDIS_2x6qhs0nt51q72g71quz2c4ol/l65535, transfer-property=PENDING, to ECM  # Tagesumlaufzähler / Circular day counter
          signal EngShutOffTm: start 36, 12 bit, little-endian, data-type=c12_min_0_4094_1, init-value=XDIS_d65q5o6fvqky5zbqr8rc19l61/l4095, transfer-property=PENDING, to ECM FSCM TCM  # Motorabstellzeit / Engine shut-off time
          signal HVAC_Vprzr_DryVnTmr_Stat: start 22, 2 bit, little-endian, data-type=c02_Vprzr_DryVnTmr_Stat, init-value=XDIS_8jlkrpnlx80l2hsrzz68ooa35/lINACTV, transfer-property=TRIGGERED-ON-CHANGE  # Verdampfertrockenlüften Zustand timer / Vaporizer dry ventilation timer state
          signal PT_ShutOffTm: start 24, 12 bit, little-endian, data-type=c12_min_0_4094_1, init-value=XDIS_d65q5o6fvqky5zbqr8rc19l61/l4095, transfer-property=PENDING, to ECM TCM  # Powertrainabstellzeit / Powertrain shut-off time
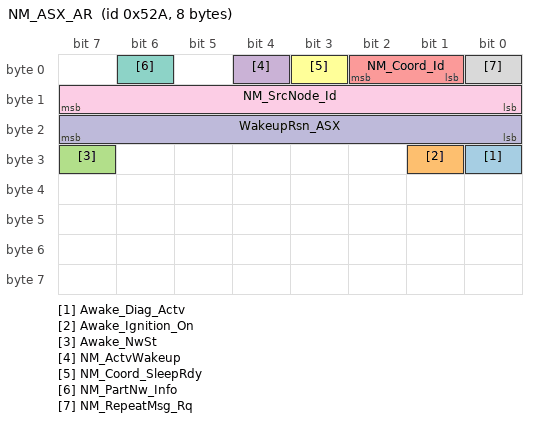
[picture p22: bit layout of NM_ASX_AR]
      frame NM_ASX_AR: id 0x52A, from ASX, frame-length=8, can-addressing-mode=STANDARD  # Network Management
        nm pdu NM_ASX_AR: length=64, nm-cbv-position=0, nm-nid-position=8, nm-user-data-length=6  # Network Management
          signal Awake_Diag_Actv: start 24, 1 bit, little-endian, data-type=DC_BOOL, init-value=XDIS_h5tcyk98kzbgrc5svasomeyt/lfalse, transfer-property=PENDING  # Wachhalten für Diagnose aktiv / Stay awake for diagnostics active
          signal Awake_Ignition_On: start 25, 1 bit, little-endian, data-type=DC_BOOL, init-value=XDIS_h5tcyk98kzbgrc5svasomeyt/lfalse, transfer-property=PENDING  # Wachhalten für Zündung eingeschaltet / Stay awake for ignition on
          signal Awake_NwSt: start 31, 1 bit, little-endian, data-type=DC_BOOL, init-value=XDIS_h5tcyk98kzbgrc5svasomeyt/lfalse, transfer-property=PENDING  # Wachhalten für Netzwerkstartphase / Stay awake for network startup
          signal NM_ActvWakeup: start 4, 1 bit, little-endian, data-type=XDIS_8zznnqbxnga51x5ej9fjpu597, init-value=XDIS_5un2e5dvr5cfu5m0829mn2f54/lfalse, transfer-property=PENDING  # Active Wakeup Bit
          signal NM_Coord_Id: start 1, 2 bit, little-endian, data-type=XDIS_ag9ggh2r04cqwuwmmjm5ytd7y, init-value=XDIS_9kvl7kybe3ytco3yjv5uyh4l/l0, transfer-property=PENDING  # NM Coordinator ID
          signal NM_Coord_SleepRdy: start 3, 1 bit, little-endian, data-type=XDIS_3jji6ucrc8il6b9sf0gioatpa, init-value=XDIS_bxrvh10jawmlothu6ak0oeoq1/lfalse, transfer-property=PENDING  # NM Coordinator Sleep Ready Bit
          signal NM_PartNw_Info: start 6, 1 bit, little-endian, data-type=XDIS_8anm4jlkd5rjz5a4dj8p5z2aw, init-value=XDIS_4setjwl49z8hlvz1qf446y4u9/lfalse, transfer-property=PENDING  # Partial Network Information Bit
          signal NM_RepeatMsg_Rq: start 0, 1 bit, little-endian, data-type=XDIS_ey4gzz3x4s3pbgmamj990b7l5, init-value=XDIS_28el54ybfxmt2nm5z16pi8wul/lfalse, transfer-property=PENDING  # Repeat Message Request
          signal NM_SrcNode_Id: start 8, 8 bit, little-endian, data-type=XDIS_dgxq2p852kecqaamwh1cpsgat, init-value=XDIS_atkxru0u5pzxs91gr5r6s45de/l0, transfer-property=PENDING  # Source Node Identifier
          signal WakeupRsn_ASX: start 16, 8 bit, little-endian, data-type=c08_WakeupRsn_SWSP, init-value=XDIS_3n14ia5jbtvrmzyyp9apgzvw8/l255, transfer-property=PENDING  # Weckgrund / Wakeup reason
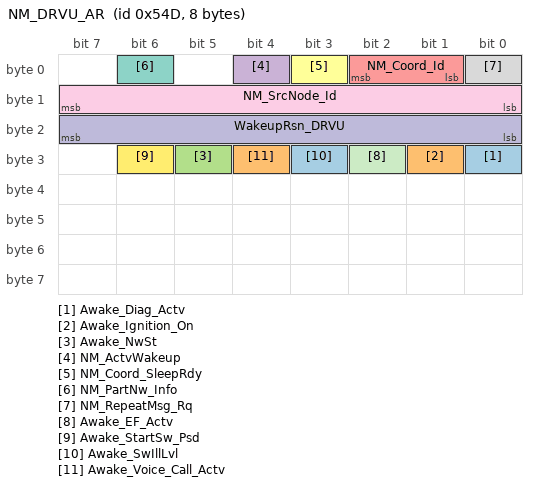
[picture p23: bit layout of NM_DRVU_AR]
      frame NM_DRVU_AR: id 0x54D, from DRVU, frame-length=8, can-addressing-mode=STANDARD  # Network Management
        nm pdu NM_DRVU_AR: length=64, nm-cbv-position=0, nm-nid-position=8, nm-user-data-length=6  # Network Management
          signal Awake_Diag_Actv: start 24, 1 bit, little-endian, data-type=DC_BOOL, init-value=XDIS_h5tcyk98kzbgrc5svasomeyt/lfalse, transfer-property=PENDING  # Wachhalten für Diagnose aktiv / Stay awake for diagnostics active
          signal Awake_Ignition_On: start 25, 1 bit, little-endian, data-type=DC_BOOL, init-value=XDIS_h5tcyk98kzbgrc5svasomeyt/lfalse, transfer-property=PENDING  # Wachhalten für Zündung eingeschaltet / Stay awake for ignition on
          signal Awake_NwSt: start 29, 1 bit, little-endian, data-type=DC_BOOL, init-value=XDIS_h5tcyk98kzbgrc5svasomeyt/lfalse, transfer-property=PENDING  # Wachhalten für Netzwerkstartphase / Stay awake for network startup
          signal NM_ActvWakeup: start 4, 1 bit, little-endian, data-type=XDIS_8zznnqbxnga51x5ej9fjpu597, init-value=XDIS_5un2e5dvr5cfu5m0829mn2f54/lfalse, transfer-property=PENDING  # Active Wakeup Bit
          signal NM_Coord_Id: start 1, 2 bit, little-endian, data-type=XDIS_ag9ggh2r04cqwuwmmjm5ytd7y, init-value=XDIS_9kvl7kybe3ytco3yjv5uyh4l/l0, transfer-property=PENDING  # NM Coordinator ID
          signal NM_Coord_SleepRdy: start 3, 1 bit, little-endian, data-type=XDIS_3jji6ucrc8il6b9sf0gioatpa, init-value=XDIS_bxrvh10jawmlothu6ak0oeoq1/lfalse, transfer-property=PENDING  # NM Coordinator Sleep Ready Bit
          signal NM_PartNw_Info: start 6, 1 bit, little-endian, data-type=XDIS_8anm4jlkd5rjz5a4dj8p5z2aw, init-value=XDIS_4setjwl49z8hlvz1qf446y4u9/lfalse, transfer-property=PENDING  # Partial Network Information Bit
          signal NM_RepeatMsg_Rq: start 0, 1 bit, little-endian, data-type=XDIS_ey4gzz3x4s3pbgmamj990b7l5, init-value=XDIS_28el54ybfxmt2nm5z16pi8wul/lfalse, transfer-property=PENDING  # Repeat Message Request
          signal NM_SrcNode_Id: start 8, 8 bit, little-endian, data-type=XDIS_dgxq2p852kecqaamwh1cpsgat, init-value=XDIS_atkxru0u5pzxs91gr5r6s45de/l0, transfer-property=PENDING  # Source Node Identifier
          signal WakeupRsn_DRVU: start 16, 8 bit, little-endian, data-type=c08_WakeupRsn_DRVU, init-value=XDIS_3c4ksz7u3rji951ohmnidw85i/l255, transfer-property=PENDING  # Weckgrund / Wakeup reason
          signal Awake_EF_Actv: start 26, 1 bit, little-endian, data-type=DC_BOOL, init-value=XDIS_h5tcyk98kzbgrc5svasomeyt/lfalse, transfer-property=PENDING  # Wachhalten für Warnblinker aktiv / Stay awake for emergency flasher active
          signal Awake_StartSw_Psd: start 30, 1 bit, little-endian, data-type=DC_BOOL, init-value=XDIS_h5tcyk98kzbgrc5svasomeyt/lfalse, transfer-property=PENDING  # Wachhalten für Starttaster betätigt / Stay awake for start switch pressed
          signal Awake_SwIllLvl: start 27, 1 bit, little-endian, data-type=DC_BOOL, init-value=XDIS_h5tcyk98kzbgrc5svasomeyt/lfalse, transfer-property=PENDING  # Wachhalten für Suchbeleuchtung (Kl. 58d) / Stay awake for switch illumination level (Term. 58d)
          signal Awake_Voice_Call_Actv: start 28, 1 bit, little-endian, data-type=DC_BOOL, init-value=XDIS_h5tcyk98kzbgrc5svasomeyt/lfalse, transfer-property=PENDING  # Wachhalten für Anrufeingang HMI / Stay awake for voice call HMI
